VERSION "created by canmatrix"

NS_ :

BS_:

BU_:

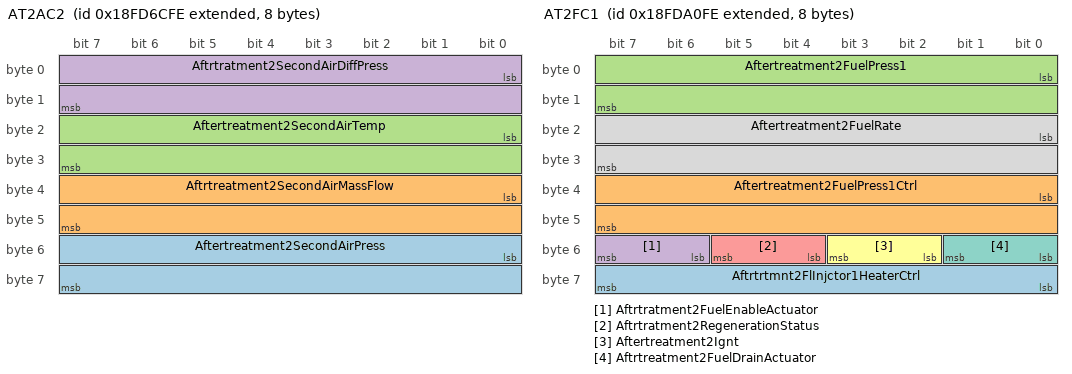
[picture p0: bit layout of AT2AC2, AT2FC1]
BO_ 2566745342 AT2AC2: 8 Vector__XXX
 SG_ Aftertreatment2SecondAirPress : 48|16@1+ (0.1,0) [0|6425.5] "kPa" Vector__XXX
 SG_ Aftrtreatment2SecondAirMassFlow : 32|16@1+ (0.2,0) [0|12851] "kg/h" Vector__XXX
 SG_ Aftertreatment2SecondAirTemp : 16|16@1+ (0.03125,-273) [-273|1734.96875] "deg C" Vector__XXX
 SG_ Aftrtratment2SecondAirDiffPress : 0|16@1+ (0.0078125,-250) [-250|251.99] "kPa" Vector__XXX

BO_ 2566758654 AT2FC1: 8 Vector__XXX
 SG_ Aftrtrtmnt2FlInjctor1HeaterCtrl : 56|8@1+ (0.4,0) [0|100] "%" Vector__XXX
 SG_ Aftertreatment2FuelPress1Ctrl : 32|16@1+ (0.0025,0) [0|160.6375] "%" Vector__XXX
 SG_ Aftertreatment2FuelPress1 : 0|16@1+ (0.1,0) [0|6425.5] "kPa" Vector__XXX
 SG_ Aftrtratment2FuelEnableActuator : 54|2@1+ (1,0) [0|3] "" Vector__XXX
 SG_ Aftrtratment2RegenerationStatus : 52|2@1+ (1,0) [0|3] "" Vector__XXX
 SG_ Aftertreatment2Ignt : 50|2@1+ (1,0) [0|3] "" Vector__XXX
 SG_ Aftrtreatment2FuelDrainActuator : 48|2@1+ (1,0) [0|3] "" Vector__XXX
 SG_ Aftertreatment2FuelRate : 16|16@1+ (0.05,0) [0|3212.75] "L/h" Vector__XXX

BO_ 2566753278 AT2GP: 8 Vector__XXX
 SG_ DslPrticulateFilterOutletPress2 : 16|16@1+ (0.1,0) [0|6425.5] "kPa" Vector__XXX
 SG_ DslPrticulateFilterIntakePress2 : 0|16@1+ (0.1,0) [0|6425.5] "kPa" Vector__XXX

BO_ 2566756862 AT2HI: 36 Vector__XXX
 SG_ Aftrtrtmnt2TtlNmbrOfActvRgnrtnMn : 224|32@1+ (1,0) [0|4294967295] "counts" Vector__XXX
 SG_ Aftrtrtmnt2TtlNmbrOfActvRgnrtnIn : 192|32@1+ (1,0) [0|4294967295] "counts" Vector__XXX
 SG_ Aftrtrtmnt2AvrgTmBtwnActvRgnrtns : 256|32@1+ (1,0) [0|4211081215] "s" Vector__XXX
 SG_ Aftrtrtmnt2TtlNmbrOfPssvRgnrtns : 160|32@1+ (1,0) [0|4294967295] "counts" Vector__XXX
 SG_ Aftrtrtmnt2TtlPssvRgnrationTime : 128|32@1+ (1,0) [0|4211081215] "s" Vector__XXX
 SG_ Aftrtrtmnt2TtlNmbrOfActvRgnrtns : 96|32@1+ (1,0) [0|4294967295] "counts" Vector__XXX
 SG_ Aftrtreatment2TotalDisabledTime : 64|32@1+ (1,0) [0|4211081215] "s" Vector__XXX
 SG_ Aftrtrtmnt2TtalRegenerationTime : 32|32@1+ (1,0) [0|4211081215] "s" Vector__XXX
 SG_ Aftertreatment2TotalFuelUsed : 0|32@1+ (0.5,0) [0|2105540607.5] "L" Vector__XXX

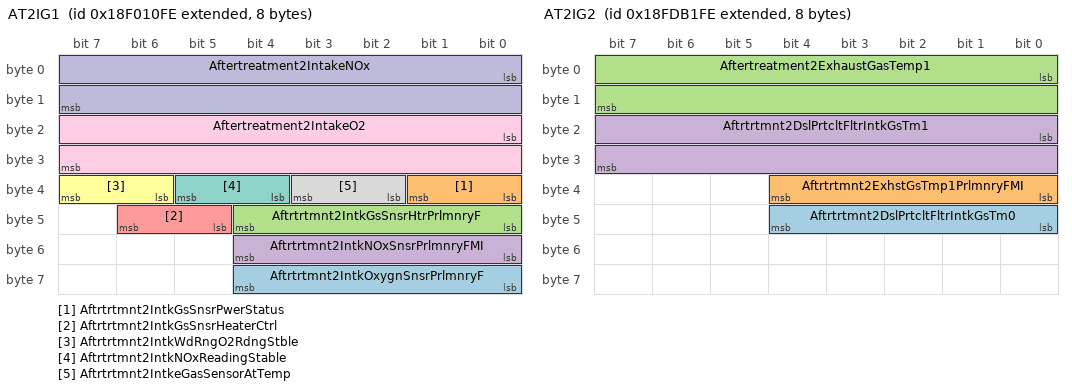
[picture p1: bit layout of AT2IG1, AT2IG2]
BO_ 2565869822 AT2IG1: 8 Vector__XXX
 SG_ Aftrtrtmnt2IntkOxygnSnsrPrlmnryF : 56|5@1+ (1,0) [0|31] "" Vector__XXX
 SG_ Aftrtrtmnt2IntkGsSnsrPwerStatus : 32|2@1+ (1,0) [0|3] "" Vector__XXX
 SG_ Aftrtrtmnt2IntkGsSnsrHtrPrlmnryF : 40|5@1+ (1,0) [0|31] "" Vector__XXX
 SG_ Aftrtrtmnt2IntkNOxSnsrPrlmnryFMI : 48|5@1+ (1,0) [0|31] "" Vector__XXX
 SG_ Aftrtrtmnt2IntkGsSnsrHeaterCtrl : 45|2@1+ (1,0) [0|3] "" Vector__XXX
 SG_ Aftrtrtmnt2IntkWdRngO2RdngStble : 38|2@1+ (1,0) [0|3] "" Vector__XXX
 SG_ Aftrtrtmnt2IntkNOxReadingStable : 36|2@1+ (1,0) [0|3] "" Vector__XXX
 SG_ Aftrtrtmnt2IntkeGasSensorAtTemp : 34|2@1+ (1,0) [0|3] "" Vector__XXX
 SG_ Aftertreatment2IntakeO2 : 16|16@1+ (0.000514,-12) [-12|21] "%" Vector__XXX
 SG_ Aftertreatment2IntakeNOx : 0|16@1+ (0.05,-200) [-200|3012.75] "ppm" Vector__XXX

BO_ 2566763006 AT2IG2: 8 Vector__XXX
 SG_ Aftrtrtmnt2DslPrtcltFltrIntkGsTm0 : 40|5@1+ (1,0) [0|31] "" Vector__XXX
 SG_ Aftrtrtmnt2ExhstGsTmp1PrlmnryFMI : 32|5@1+ (1,0) [0|31] "" Vector__XXX
 SG_ Aftertreatment2ExhaustGasTemp1 : 0|16@1+ (0.03125,-273) [-273|1734.96875] "deg C" Vector__XXX
 SG_ Aftrtrtmnt2DslPrtcltFltrIntkGsTm1 : 16|16@1+ (0.03125,-273) [-273|1734.96875] "deg C" Vector__XXX

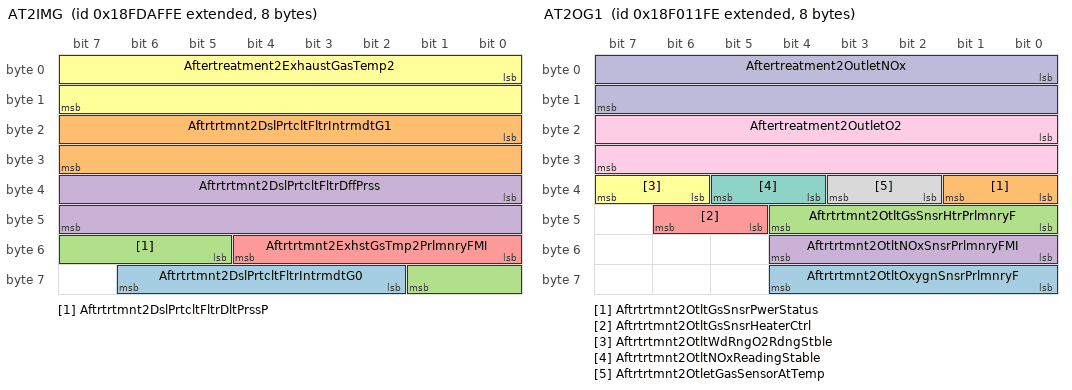
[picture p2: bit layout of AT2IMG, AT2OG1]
BO_ 2566762494 AT2IMG: 8 Vector__XXX
 SG_ Aftrtrtmnt2DslPrtcltFltrIntrmdtG0 : 58|5@1+ (1,0) [0|31] "" Vector__XXX
 SG_ Aftrtrtmnt2DslPrtcltFltrIntrmdtG1 : 16|16@1+ (0.03125,-273) [-273|1734.96875] "deg C" Vector__XXX
 SG_ Aftrtrtmnt2DslPrtcltFltrDltPrssP : 53|5@1+ (1,0) [0|31] "" Vector__XXX
 SG_ Aftrtrtmnt2DslPrtcltFltrDffPrss : 32|16@1+ (0.1,0) [0|6425.5] "kPa" Vector__XXX
 SG_ Aftrtrtmnt2ExhstGsTmp2PrlmnryFMI : 48|5@1+ (1,0) [0|31] "" Vector__XXX
 SG_ Aftertreatment2ExhaustGasTemp2 : 0|16@1+ (0.03125,-273) [-273|1734.96875] "deg C" Vector__XXX

BO_ 2565870078 AT2OG1: 8 Vector__XXX
 SG_ Aftrtrtmnt2OtltOxygnSnsrPrlmnryF : 56|5@1+ (1,0) [0|31] "" Vector__XXX
 SG_ Aftrtrtmnt2OtltGsSnsrPwerStatus : 32|2@1+ (1,0) [0|3] "" Vector__XXX
 SG_ Aftrtrtmnt2OtltGsSnsrHtrPrlmnryF : 40|5@1+ (1,0) [0|31] "" Vector__XXX
 SG_ Aftrtrtmnt2OtltNOxSnsrPrlmnryFMI : 48|5@1+ (1,0) [0|31] "" Vector__XXX
 SG_ Aftrtrtmnt2OtltGsSnsrHeaterCtrl : 45|2@1+ (1,0) [0|3] "" Vector__XXX
 SG_ Aftrtrtmnt2OtltWdRngO2RdngStble : 38|2@1+ (1,0) [0|3] "" Vector__XXX
 SG_ Aftrtrtmnt2OtltNOxReadingStable : 36|2@1+ (1,0) [0|3] "" Vector__XXX
 SG_ Aftrtrtmnt2OtletGasSensorAtTemp : 34|2@1+ (1,0) [0|3] "" Vector__XXX
 SG_ Aftertreatment2OutletO2 : 16|16@1+ (0.000514,-12) [-12|21] "%" Vector__XXX
 SG_ Aftertreatment2OutletNOx : 0|16@1+ (0.05,-200) [-200|3012.75] "ppm" Vector__XXX

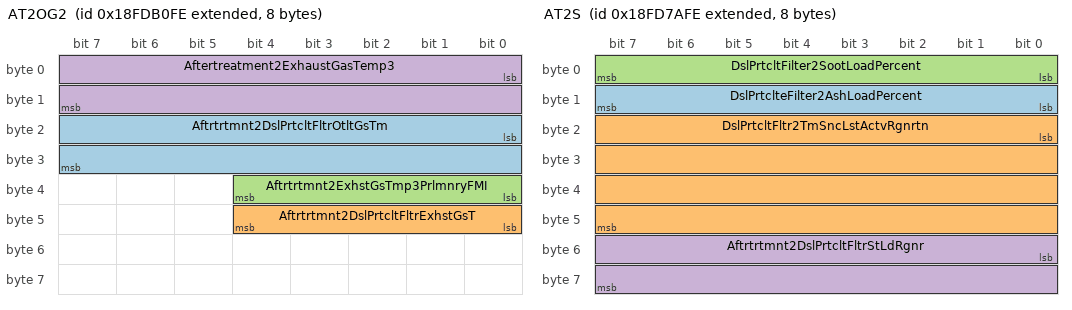
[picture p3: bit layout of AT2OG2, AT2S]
BO_ 2566762750 AT2OG2: 8 Vector__XXX
 SG_ Aftrtrtmnt2DslPrtcltFltrOtltGsTm : 16|16@1+ (0.03125,-273) [-273|1734.96875] "deg C" Vector__XXX
 SG_ Aftrtrtmnt2DslPrtcltFltrExhstGsT : 40|5@1+ (1,0) [0|31] "" Vector__XXX
 SG_ Aftrtrtmnt2ExhstGsTmp3PrlmnryFMI : 32|5@1+ (1,0) [0|31] "" Vector__XXX
 SG_ Aftertreatment2ExhaustGasTemp3 : 0|16@1+ (0.03125,-273) [-273|1734.96875] "deg C" Vector__XXX

BO_ 2566748926 AT2S: 8 Vector__XXX
 SG_ DslPrtclteFilter2AshLoadPercent : 8|8@1+ (1,0) [0|250] "%" Vector__XXX
 SG_ DslPrtcltFltr2TmSncLstActvRgnrtn : 16|32@1+ (1,0) [0|4211081215] "s" Vector__XXX
 SG_ DslPrtcltFilter2SootLoadPercent : 0|8@1+ (1,0) [0|250] "%" Vector__XXX
 SG_ Aftrtrtmnt2DslPrtcltFltrStLdRgnr : 48|16@1+ (0.0025,0) [0|160.6375] "%" Vector__XXX

BO_ 2566748414 AT2TI: 32 Vector__XXX
 SG_ Aftrtrtmnt2TrpNmbrOfActvRgnrtnMn : 224|32@1+ (1,0) [0|4294967295] "counts" Vector__XXX
 SG_ Aftrtrtmnt2TrpNmbrOfActvRgnrtnIn : 192|32@1+ (1,0) [0|4294967295] "counts" Vector__XXX
 SG_ Aftrtrtmnt2TrpNmbrOfPssvRgnrtns : 160|32@1+ (1,0) [0|4294967295] "counts" Vector__XXX
 SG_ Aftrtrtmnt2TrpPssvRgnrationTime : 128|32@1+ (1,0) [0|4211081215] "s" Vector__XXX
 SG_ Aftrtrtmnt2TrpNmbrOfActvRgnrtns : 96|32@1+ (1,0) [0|4294967295] "counts" Vector__XXX
 SG_ Aftertreatment2TripDisabledTime : 64|32@1+ (1,0) [0|4211081215] "s" Vector__XXX
 SG_ Aftrtrtmnt2TrpActvRgnrationTime : 32|32@1+ (1,0) [0|4211081215] "s" Vector__XXX
 SG_ Aftertreatment2TripFuelUsed : 0|32@1+ (0.5,0) [0|2105540607.5] "L" Vector__XXX

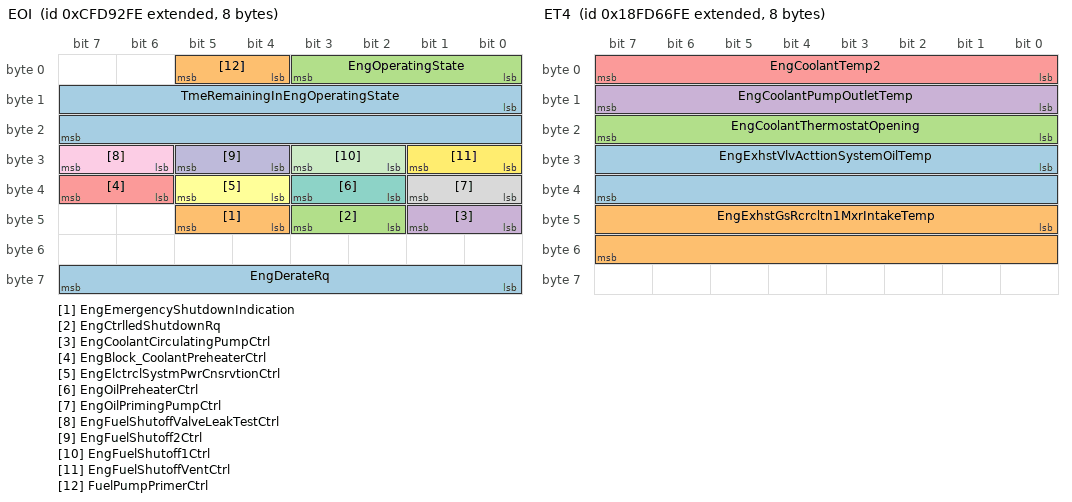
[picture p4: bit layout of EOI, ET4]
BO_ 2365428478 EOI: 8 Vector__XXX
 SG_ EngDerateRq : 56|8@1+ (0.4,0) [0|100] "%" Vector__XXX
 SG_ EngEmergencyShutdownIndication : 44|2@1+ (1,0) [0|3] "" Vector__XXX
 SG_ EngCtrlledShutdownRq : 42|2@1+ (1,0) [0|3] "" Vector__XXX
 SG_ EngCoolantCirculatingPumpCtrl : 40|2@1+ (1,0) [0|3] "" Vector__XXX
 SG_ EngBlock_CoolantPreheaterCtrl : 38|2@1+ (1,0) [0|3] "" Vector__XXX
 SG_ EngElctrclSystmPwrCnsrvtionCtrl : 36|2@1+ (1,0) [0|3] "" Vector__XXX
 SG_ EngOilPreheaterCtrl : 34|2@1+ (1,0) [0|3] "" Vector__XXX
 SG_ EngOilPrimingPumpCtrl : 32|2@1+ (1,0) [0|3] "" Vector__XXX
 SG_ EngFuelShutoffValveLeakTestCtrl : 30|2@1+ (1,0) [0|3] "" Vector__XXX
 SG_ EngFuelShutoff2Ctrl : 28|2@1+ (1,0) [0|3] "" Vector__XXX
 SG_ EngFuelShutoff1Ctrl : 26|2@1+ (1,0) [0|3] "" Vector__XXX
 SG_ EngFuelShutoffVentCtrl : 24|2@1+ (1,0) [0|3] "" Vector__XXX
 SG_ TmeRemainingInEngOperatingState : 8|16@1+ (1,0) [0|64255] "s" Vector__XXX
 SG_ FuelPumpPrimerCtrl : 4|2@1+ (1,0) [0|3] "" Vector__XXX
 SG_ EngOperatingState : 0|4@1+ (1,0) [0|15] "" Vector__XXX

BO_ 2566743806 ET4: 8 Vector__XXX
 SG_ EngExhstVlvActtionSystemOilTemp : 24|16@1+ (0.03125,-273) [-273|1734.96875] "deg C" Vector__XXX
 SG_ EngExhstGsRcrcltn1MxrIntakeTemp : 40|16@1+ (0.03125,-273) [-273|1734.96875] "deg C" Vector__XXX
 SG_ EngCoolantThermostatOpening : 16|8@1+ (0.4,0) [0|100] "%" Vector__XXX
 SG_ EngCoolantPumpOutletTemp : 8|8@1+ (1,-40) [-40|210] "deg C" Vector__XXX
 SG_ EngCoolantTemp2 : 0|8@1+ (1,-40) [-40|210] "deg C" Vector__XXX

BO_ 2499635454 GCVW: 8 Vector__XXX
 SG_ NetVehicleWeightChange : 24|24@1+ (2,-16449535) [-16449535|16449535] "kg" Vector__XXX
 SG_ GrossCombinationWeight : 0|24@1+ (2,0) [0|32899070] "kg" Vector__XXX

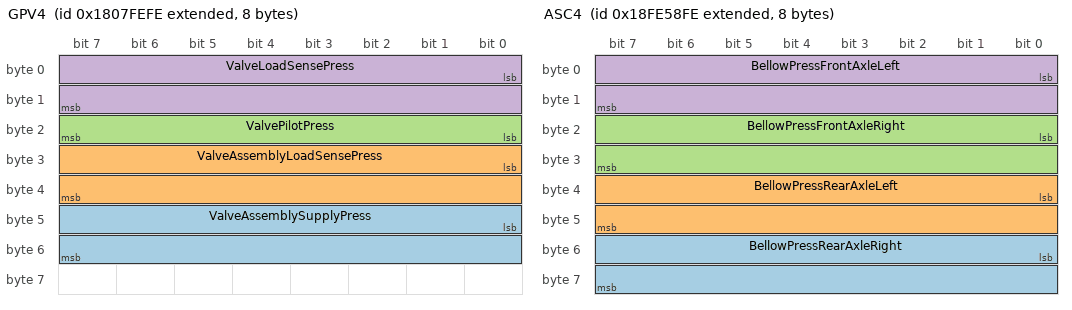
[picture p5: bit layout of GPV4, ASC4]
BO_ 2550660862 GPV4: 8 Vector__XXX
 SG_ ValveAssemblySupplyPress : 40|16@1+ (5,0) [0|321275] "kPa" Vector__XXX
 SG_ ValveAssemblyLoadSensePress : 24|16@1+ (5,0) [0|321275] "kPa" Vector__XXX
 SG_ ValvePilotPress : 16|8@1+ (16,0) [0|4000] "kPa" Vector__XXX
 SG_ ValveLoadSensePress : 0|16@1+ (5,0) [0|321275] "kPa" Vector__XXX

BO_ 2566805758 ASC4: 8 Vector__XXX
 SG_ BellowPressRearAxleRight : 48|16@1+ (0.1,0) [0|6425.5] "kPa" Vector__XXX
 SG_ BellowPressRearAxleLeft : 32|16@1+ (0.1,0) [0|6425.5] "kPa" Vector__XXX
 SG_ BellowPressFrontAxleRight : 16|16@1+ (0.1,0) [0|6425.5] "kPa" Vector__XXX
 SG_ BellowPressFrontAxleLeft : 0|16@1+ (0.1,0) [0|6425.5] "kPa" Vector__XXX

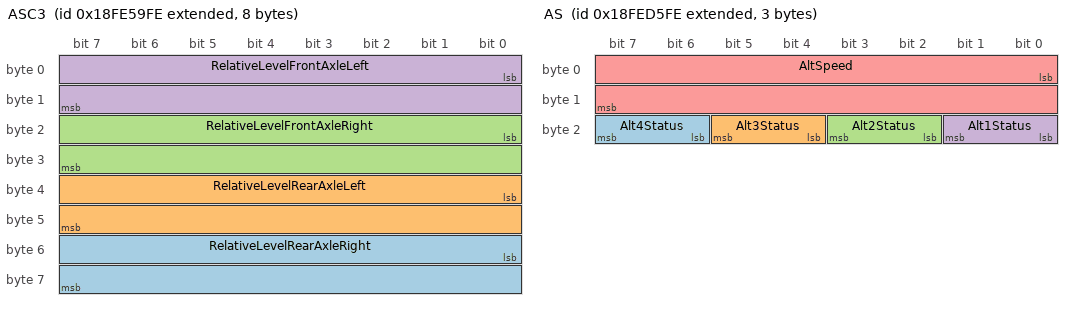
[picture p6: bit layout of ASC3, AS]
BO_ 2566806014 ASC3: 8 Vector__XXX
 SG_ RelativeLevelRearAxleRight : 48|16@1+ (0.1,-3200) [-3200|3225.5] "mm" Vector__XXX
 SG_ RelativeLevelRearAxleLeft : 32|16@1+ (0.1,-3200) [-3200|3225.5] "mm" Vector__XXX
 SG_ RelativeLevelFrontAxleRight : 16|16@1+ (0.1,-3200) [-3200|3225.5] "mm" Vector__XXX
 SG_ RelativeLevelFrontAxleLeft : 0|16@1+ (0.1,-3200) [-3200|3225.5] "mm" Vector__XXX

BO_ 2362638078 ASC2: 8 Vector__XXX
 SG_ SpeedDependentLevelCtrlRq : 56|2@1+ (1,0) [0|3] "" Vector__XXX
 SG_ PrhbtAutomaticAirSuspensionCtrl : 58|2@1+ (1,0) [0|3] "" Vector__XXX
 SG_ MemoryLevelRq : 60|4@1+ (1,0) [0|15] "" Vector__XXX
 SG_ AllowLevelCtrlDuringBrakingCmd : 54|2@1+ (1,0) [0|3] "" Vector__XXX
 SG_ ProhibitAirSuspensionCtrl : 52|2@1+ (1,0) [0|3] "" Vector__XXX
 SG_ KneelingCmdRearAxle : 50|2@1+ (1,0) [0|3] "" Vector__XXX
 SG_ KneelingCmdFrontAxle : 48|2@1+ (1,0) [0|3] "" Vector__XXX
 SG_ DamperStiffnessRqLift_TagAxle : 40|8@1+ (0.4,0) [0|100] "%" Vector__XXX
 SG_ DamperStiffnessRqRearAxle : 32|8@1+ (0.4,0) [0|100] "%" Vector__XXX
 SG_ DamperStiffnessRqFrontAxle : 24|8@1+ (0.4,0) [0|100] "%" Vector__XXX
 SG_ LevelCtrlModeRq : 16|4@1+ (1,0) [0|15] "" Vector__XXX
 SG_ NominalLevelRqRearAxle : 12|4@1+ (1,0) [0|15] "" Vector__XXX
 SG_ NominalLevelRqFrontAxle : 8|4@1+ (1,0) [0|15] "" Vector__XXX
 SG_ KneelingCtrlModeRq : 6|2@1+ (1,0) [0|3] "" Vector__XXX
 SG_ KneelingRqRightSide : 4|2@1+ (1,0) [0|3] "" Vector__XXX
 SG_ KneelingRqLeftSide : 2|2@1+ (1,0) [0|3] "" Vector__XXX
 SG_ AutomaticTractionHelp : 0|2@1+ (1,0) [0|3] "" Vector__XXX
 SG_ LiftAxle2PosCmd : 22|2@1+ (1,0) [0|3] "" Vector__XXX
 SG_ LiftAxle1PosCmd : 20|2@1+ (1,0) [0|3] "" Vector__XXX

BO_ 2365479678 ASC1: 8 Vector__XXX
 SG_ SpeedDependantLevelCtrlStatus : 54|2@1+ (1,0) [0|3] "" Vector__XXX
 SG_ MemoryLevel : 60|4@1+ (1,0) [0|15] "" Vector__XXX
 SG_ AllwLvelCtrlDuringBrakingStatus : 52|2@1+ (1,0) [0|3] "" Vector__XXX
 SG_ SspensionCtrlRefusalInformation : 56|4@1+ (1,0) [0|15] "" Vector__XXX
 SG_ SuspensionRemoteCtrl2 : 50|2@1+ (1,0) [0|3] "" Vector__XXX
 SG_ SuspensionRemoteCtrl1 : 48|2@1+ (1,0) [0|3] "" Vector__XXX
 SG_ RearAxleInBumperRange : 42|2@1+ (1,0) [0|3] "" Vector__XXX
 SG_ FrontAxleInBumperRange : 40|2@1+ (1,0) [0|3] "" Vector__XXX
 SG_ DoorRelease : 36|2@1+ (1,0) [0|3] "" Vector__XXX
 SG_ VehicleMotionInhibit : 34|2@1+ (1,0) [0|3] "" Vector__XXX
 SG_ SecurityDevice : 32|2@1+ (1,0) [0|3] "" Vector__XXX
 SG_ LevelCtrlMode : 28|4@1+ (1,0) [0|15] "" Vector__XXX
 SG_ KneelingInformation : 24|4@1+ (1,0) [0|15] "" Vector__XXX
 SG_ LiftingCtrlModeRearAxle : 22|2@1+ (1,0) [0|3] "" Vector__XXX
 SG_ LiftingCtrlModeFrontAxle : 20|2@1+ (1,0) [0|3] "" Vector__XXX
 SG_ LoweringCtrlModeRearAxle : 18|2@1+ (1,0) [0|3] "" Vector__XXX
 SG_ LoweringCtrlModeFrontAxle : 16|2@1+ (1,0) [0|3] "" Vector__XXX
 SG_ AboveNominalLevelRearAxle : 14|2@1+ (1,0) [0|3] "" Vector__XXX
 SG_ AboveNominalLevelFrontAxle : 12|2@1+ (1,0) [0|3] "" Vector__XXX
 SG_ BelowNominalLevelRearAxle : 10|2@1+ (1,0) [0|3] "" Vector__XXX
 SG_ BelowNominalLevelFrontAxle : 8|2@1+ (1,0) [0|3] "" Vector__XXX
 SG_ NominalLevelRearAxle : 4|4@1+ (1,0) [0|15] "" Vector__XXX
 SG_ NominalLevelFrontAxle : 0|4@1+ (1,0) [0|15] "" Vector__XXX
 SG_ LiftAxle2Pos : 46|2@1+ (1,0) [0|3] "" Vector__XXX
 SG_ LiftAxle1Pos : 38|2@1+ (1,0) [0|3] "" Vector__XXX

BO_ 2566837758 AS: 3 Vector__XXX
 SG_ Alt4Status : 22|2@1+ (1,0) [0|3] "" Vector__XXX
 SG_ Alt3Status : 20|2@1+ (1,0) [0|3] "" Vector__XXX
 SG_ Alt2Status : 18|2@1+ (1,0) [0|3] "" Vector__XXX
 SG_ Alt1Status : 16|2@1+ (1,0) [0|3] "" Vector__XXX
 SG_ AltSpeed : 0|16@1+ (0.5,0) [0|32127.5] "rpm" Vector__XXX

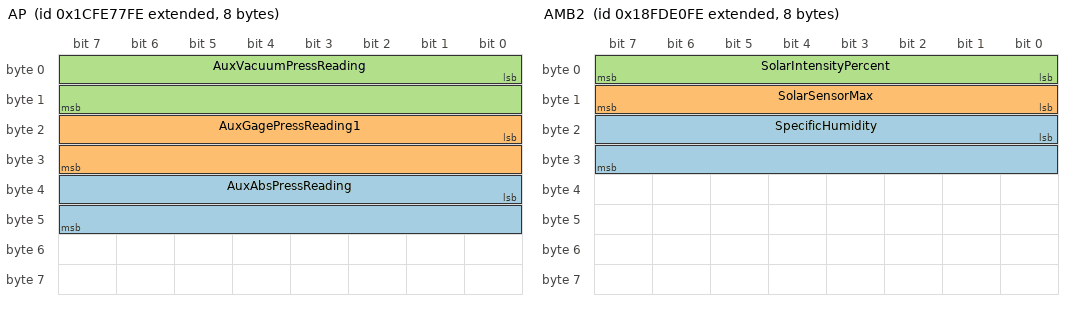
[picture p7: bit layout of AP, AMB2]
BO_ 2633922558 AP: 8 Vector__XXX
 SG_ AuxAbsPressReading : 32|16@1+ (0.5,0) [0|32127.5] "kPa" Vector__XXX
 SG_ AuxGagePressReading1 : 16|16@1+ (0.5,0) [0|32127.5] "kPa" Vector__XXX
 SG_ AuxVacuumPressReading : 0|16@1+ (0.5,0) [0|32127.5] "kPa" Vector__XXX

BO_ 2566775038 AMB2: 8 Vector__XXX
 SG_ SpecificHumidity : 16|16@1+ (0.01,0) [0|642.55] "g/kg" Vector__XXX
 SG_ SolarSensorMax : 8|8@1+ (0.4,0) [0|100] "mW/cm/cm" Vector__XXX
 SG_ SolarIntensityPercent : 0|8@1+ (0.4,0) [0|100] "%" Vector__XXX

BO_ 2499635966 AGW: 8 Vector__XXX
 SG_ AxleGroupWeight : 8|16@1+ (2,0) [0|128510] "kg" Vector__XXX
 SG_ AxleGroupLocation : 0|4@1+ (1,0) [0|15] "" Vector__XXX

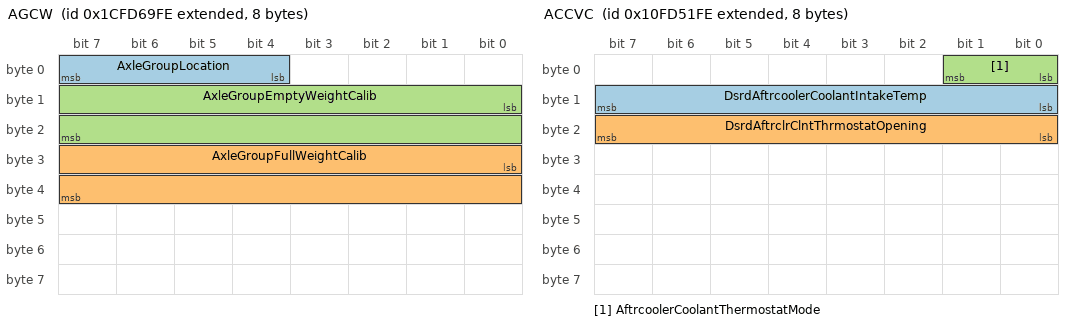
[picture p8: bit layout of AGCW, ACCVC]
BO_ 2633853438 AGCW: 8 Vector__XXX
 SG_ AxleGroupLocation : 4|4@1+ (1,0) [0|15] "" Vector__XXX
 SG_ AxleGroupFullWeightCalib : 24|16@1+ (2,0) [0|128510] "kg" Vector__XXX
 SG_ AxleGroupEmptyWeightCalib : 8|16@1+ (2,0) [0|128510] "kg" Vector__XXX

BO_ 2432520702 ACCVC: 8 Vector__XXX
 SG_ DsrdAftrcoolerCoolantIntakeTemp : 8|8@1+ (1,-40) [-40|210] "deg C" Vector__XXX
 SG_ DsrdAftrclrClntThrmostatOpening : 16|8@1+ (0.4,0) [0|100] "%" Vector__XXX
 SG_ AftrcoolerCoolantThermostatMode : 0|2@1+ (1,0) [0|3] "" Vector__XXX

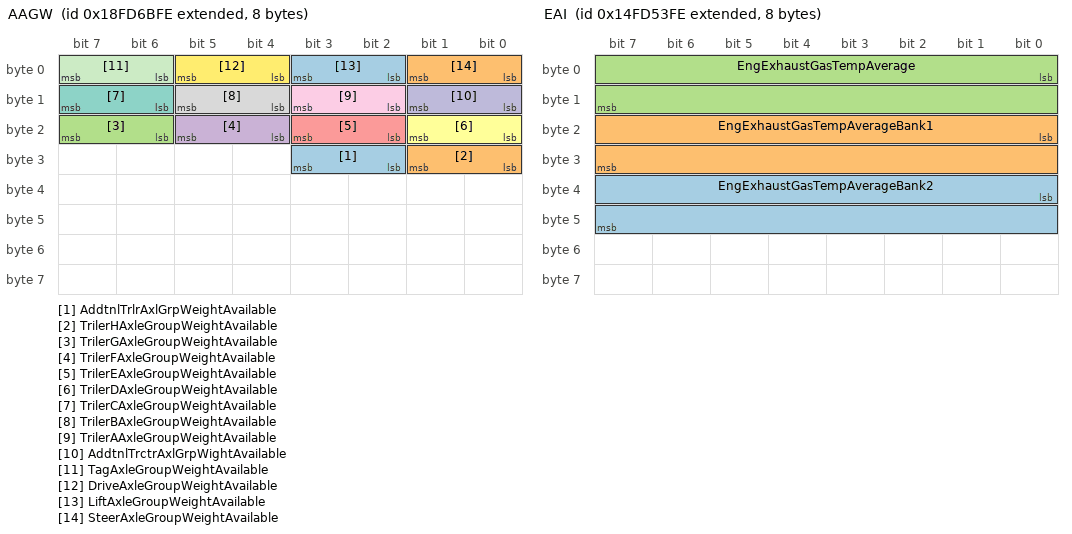
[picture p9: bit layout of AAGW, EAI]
BO_ 2566745086 AAGW: 8 Vector__XXX
 SG_ AddtnlTrlrAxlGrpWeightAvailable : 26|2@1+ (1,0) [0|3] "" Vector__XXX
 SG_ TrilerHAxleGroupWeightAvailable : 24|2@1+ (1,0) [0|3] "" Vector__XXX
 SG_ TrilerGAxleGroupWeightAvailable : 22|2@1+ (1,0) [0|3] "" Vector__XXX
 SG_ TrilerFAxleGroupWeightAvailable : 20|2@1+ (1,0) [0|3] "" Vector__XXX
 SG_ TrilerEAxleGroupWeightAvailable : 18|2@1+ (1,0) [0|3] "" Vector__XXX
 SG_ TrilerDAxleGroupWeightAvailable : 16|2@1+ (1,0) [0|3] "" Vector__XXX
 SG_ TrilerCAxleGroupWeightAvailable : 14|2@1+ (1,0) [0|3] "" Vector__XXX
 SG_ TrilerBAxleGroupWeightAvailable : 12|2@1+ (1,0) [0|3] "" Vector__XXX
 SG_ TrilerAAxleGroupWeightAvailable : 10|2@1+ (1,0) [0|3] "" Vector__XXX
 SG_ AddtnlTrctrAxlGrpWightAvailable : 8|2@1+ (1,0) [0|3] "" Vector__XXX
 SG_ TagAxleGroupWeightAvailable : 6|2@1+ (1,0) [0|3] "" Vector__XXX
 SG_ DriveAxleGroupWeightAvailable : 4|2@1+ (1,0) [0|3] "" Vector__XXX
 SG_ LiftAxleGroupWeightAvailable : 2|2@1+ (1,0) [0|3] "" Vector__XXX
 SG_ SteerAxleGroupWeightAvailable : 0|2@1+ (1,0) [0|3] "" Vector__XXX

BO_ 2566744062 ZNVW: 8 Vector__XXX
 SG_ ZeroNetVehicleWeightChange : 0|2@1+ (1,0) [0|3] "" Vector__XXX

BO_ 2499630078 EAI: 8 Vector__XXX
 SG_ EngExhaustGasTempAverageBank2 : 32|16@1+ (0.03125,-273) [-273|1734.96875] "deg C" Vector__XXX
 SG_ EngExhaustGasTempAverageBank1 : 16|16@1+ (0.03125,-273) [-273|1734.96875] "deg C" Vector__XXX
 SG_ EngExhaustGasTempAverage : 0|16@1+ (0.03125,-273) [-273|1734.96875] "deg C" Vector__XXX

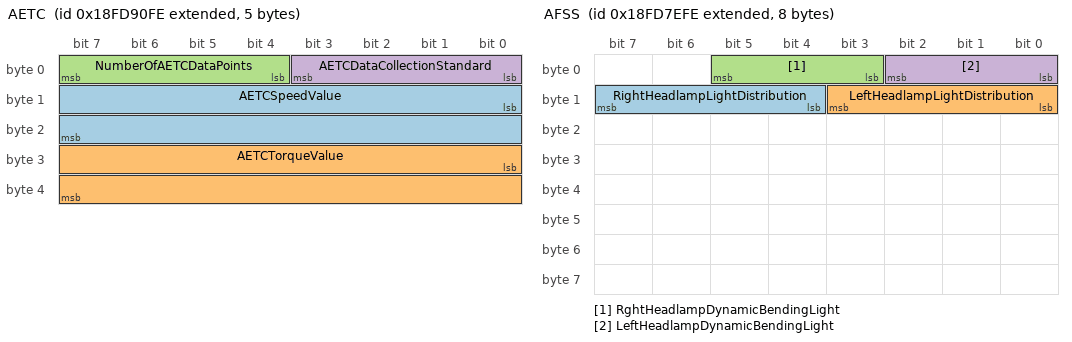
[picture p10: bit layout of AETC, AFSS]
BO_ 2566754558 AETC: 5 Vector__XXX
 SG_ AETCSpeedValue : 8|16@1- (1,0) [0|8031.875] "rpm" Vector__XXX
 SG_ AETCTorqueValue : 24|16@1+ (1,0) [0|64255] "Nm" Vector__XXX
 SG_ NumberOfAETCDataPoints : 4|4@1+ (1,0) [0|15] "" Vector__XXX
 SG_ AETCDataCollectionStandard : 0|4@1+ (1,0) [0|15] "" Vector__XXX

BO_ 2566749950 AFSS: 8 Vector__XXX
 SG_ RightHeadlampLightDistribution : 12|4@1+ (1,0) [0|15] "" Vector__XXX
 SG_ LeftHeadlampLightDistribution : 8|4@1+ (1,0) [0|15] "" Vector__XXX
 SG_ RghtHeadlampDynamicBendingLight : 3|3@1+ (1,0) [0|7] "" Vector__XXX
 SG_ LeftHeadlampDynamicBendingLight : 0|3@1+ (1,0) [0|7] "" Vector__XXX

BO_ 2566838782 AUXIO1: 8 Vector__XXX
 SG_ AuxI_O16 : 24|2@1+ (1,0) [0|3] "" Vector__XXX
 SG_ AuxI_O15 : 26|2@1+ (1,0) [0|3] "" Vector__XXX
 SG_ AuxI_O14 : 28|2@1+ (1,0) [0|3] "" Vector__XXX
 SG_ AuxI_O13 : 30|2@1+ (1,0) [0|3] "" Vector__XXX
 SG_ AuxI_O12 : 16|2@1+ (1,0) [0|3] "" Vector__XXX
 SG_ AuxI_O11 : 18|2@1+ (1,0) [0|3] "" Vector__XXX
 SG_ AuxI_O10 : 20|2@1+ (1,0) [0|3] "" Vector__XXX
 SG_ AuxI_O09 : 22|2@1+ (1,0) [0|3] "" Vector__XXX
 SG_ AuxI_O08 : 8|2@1+ (1,0) [0|3] "" Vector__XXX
 SG_ AuxI_O07 : 10|2@1+ (1,0) [0|3] "" Vector__XXX
 SG_ AuxI_O06 : 12|2@1+ (1,0) [0|3] "" Vector__XXX
 SG_ AuxI_O05 : 14|2@1+ (1,0) [0|3] "" Vector__XXX
 SG_ AuxI_O04 : 0|2@1+ (1,0) [0|3] "" Vector__XXX
 SG_ AuxI_O03 : 2|2@1+ (1,0) [0|3] "" Vector__XXX
 SG_ AuxI_O02 : 4|2@1+ (1,0) [0|3] "" Vector__XXX
 SG_ AuxI_O01 : 6|2@1+ (1,0) [0|3] "" Vector__XXX
 SG_ AuxI_OChannel2 : 48|16@1+ (1,0) [0|64255] "counts" Vector__XXX
 SG_ AuxI_OChannel1 : 32|16@1+ (1,0) [0|64255] "counts" Vector__XXX

BO_ 2561146622 AUXIO2: 8 Vector__XXX
 SG_ AuxI_O45 : 62|2@1+ (1,0) [0|3] "" Vector__XXX
 SG_ AuxI_O46 : 60|2@1+ (1,0) [0|3] "" Vector__XXX
 SG_ AuxI_O47 : 58|2@1+ (1,0) [0|3] "" Vector__XXX
 SG_ AuxI_O48 : 56|2@1+ (1,0) [0|3] "" Vector__XXX
 SG_ AuxI_O41 : 54|2@1+ (1,0) [0|3] "" Vector__XXX
 SG_ AuxI_O42 : 52|2@1+ (1,0) [0|3] "" Vector__XXX
 SG_ AuxI_O43 : 50|2@1+ (1,0) [0|3] "" Vector__XXX
 SG_ AuxI_O44 : 48|2@1+ (1,0) [0|3] "" Vector__XXX
 SG_ AuxI_O37 : 46|2@1+ (1,0) [0|3] "" Vector__XXX
 SG_ AuxI_O38 : 44|2@1+ (1,0) [0|3] "" Vector__XXX
 SG_ AuxI_O39 : 42|2@1+ (1,0) [0|3] "" Vector__XXX
 SG_ AuxI_O40 : 40|2@1+ (1,0) [0|3] "" Vector__XXX
 SG_ AuxI_O33 : 38|2@1+ (1,0) [0|3] "" Vector__XXX
 SG_ AuxI_O34 : 36|2@1+ (1,0) [0|3] "" Vector__XXX
 SG_ AuxI_O35 : 34|2@1+ (1,0) [0|3] "" Vector__XXX
 SG_ AuxI_O36 : 32|2@1+ (1,0) [0|3] "" Vector__XXX
 SG_ AuxI_O29 : 30|2@1+ (1,0) [0|3] "" Vector__XXX
 SG_ AuxI_O30 : 28|2@1+ (1,0) [0|3] "" Vector__XXX
 SG_ AuxI_O31 : 26|2@1+ (1,0) [0|3] "" Vector__XXX
 SG_ AuxI_O32 : 24|2@1+ (1,0) [0|3] "" Vector__XXX
 SG_ AuxI_O25 : 22|2@1+ (1,0) [0|3] "" Vector__XXX
 SG_ AuxI_O26 : 20|2@1+ (1,0) [0|3] "" Vector__XXX
 SG_ AuxI_O27 : 18|2@1+ (1,0) [0|3] "" Vector__XXX
 SG_ AuxI_O28 : 16|2@1+ (1,0) [0|3] "" Vector__XXX
 SG_ AuxI_O21 : 14|2@1+ (1,0) [0|3] "" Vector__XXX
 SG_ AuxI_O22 : 12|2@1+ (1,0) [0|3] "" Vector__XXX
 SG_ AuxI_O23 : 10|2@1+ (1,0) [0|3] "" Vector__XXX
 SG_ AuxI_O24 : 8|2@1+ (1,0) [0|3] "" Vector__XXX
 SG_ AuxI_O17 : 6|2@1+ (1,0) [0|3] "" Vector__XXX
 SG_ AuxI_O18 : 4|2@1+ (1,0) [0|3] "" Vector__XXX
 SG_ AuxI_O19 : 2|2@1+ (1,0) [0|3] "" Vector__XXX
 SG_ AuxI_O20 : 0|2@1+ (1,0) [0|3] "" Vector__XXX

BO_ 2561081086 AUXIO3: 8 Vector__XXX
 SG_ AuxI_O77 : 62|2@1+ (1,0) [0|3] "" Vector__XXX
 SG_ AuxI_O78 : 60|2@1+ (1,0) [0|3] "" Vector__XXX
 SG_ AuxI_O79 : 58|2@1+ (1,0) [0|3] "" Vector__XXX
 SG_ AuxI_O80 : 56|2@1+ (1,0) [0|3] "" Vector__XXX
 SG_ AuxI_O73 : 54|2@1+ (1,0) [0|3] "" Vector__XXX
 SG_ AuxI_O74 : 52|2@1+ (1,0) [0|3] "" Vector__XXX
 SG_ AuxI_O75 : 50|2@1+ (1,0) [0|3] "" Vector__XXX
 SG_ AuxI_O76 : 48|2@1+ (1,0) [0|3] "" Vector__XXX
 SG_ AuxI_O69 : 46|2@1+ (1,0) [0|3] "" Vector__XXX
 SG_ AuxI_O70 : 44|2@1+ (1,0) [0|3] "" Vector__XXX
 SG_ AuxI_O71 : 42|2@1+ (1,0) [0|3] "" Vector__XXX
 SG_ AuxI_O72 : 40|2@1+ (1,0) [0|3] "" Vector__XXX
 SG_ AuxI_O65 : 38|2@1+ (1,0) [0|3] "" Vector__XXX
 SG_ AuxI_O66 : 36|2@1+ (1,0) [0|3] "" Vector__XXX
 SG_ AuxI_O67 : 34|2@1+ (1,0) [0|3] "" Vector__XXX
 SG_ AuxI_O68 : 32|2@1+ (1,0) [0|3] "" Vector__XXX
 SG_ AuxI_O61 : 30|2@1+ (1,0) [0|3] "" Vector__XXX
 SG_ AuxI_O62 : 28|2@1+ (1,0) [0|3] "" Vector__XXX
 SG_ AuxI_O63 : 26|2@1+ (1,0) [0|3] "" Vector__XXX
 SG_ AuxI_O64 : 24|2@1+ (1,0) [0|3] "" Vector__XXX
 SG_ AuxI_O57 : 22|2@1+ (1,0) [0|3] "" Vector__XXX
 SG_ AuxI_O58 : 20|2@1+ (1,0) [0|3] "" Vector__XXX
 SG_ AuxI_O59 : 18|2@1+ (1,0) [0|3] "" Vector__XXX
 SG_ AuxI_O60 : 16|2@1+ (1,0) [0|3] "" Vector__XXX
 SG_ AuxI_O53 : 14|2@1+ (1,0) [0|3] "" Vector__XXX
 SG_ AuxI_O54 : 12|2@1+ (1,0) [0|3] "" Vector__XXX
 SG_ AuxI_O55 : 10|2@1+ (1,0) [0|3] "" Vector__XXX
 SG_ AuxI_O56 : 8|2@1+ (1,0) [0|3] "" Vector__XXX
 SG_ AuxI_O49 : 6|2@1+ (1,0) [0|3] "" Vector__XXX
 SG_ AuxI_O50 : 4|2@1+ (1,0) [0|3] "" Vector__XXX
 SG_ AuxI_O51 : 2|2@1+ (1,0) [0|3] "" Vector__XXX
 SG_ AuxI_O52 : 0|2@1+ (1,0) [0|3] "" Vector__XXX

BO_ 2561015550 AUXIO4: 8 Vector__XXX
 SG_ AuxI_O92 : 16|2@1+ (1,0) [0|3] "" Vector__XXX
 SG_ AuxI_O85 : 14|2@1+ (1,0) [0|3] "" Vector__XXX
 SG_ AuxI_O86 : 12|2@1+ (1,0) [0|3] "" Vector__XXX
 SG_ AuxI_O87 : 10|2@1+ (1,0) [0|3] "" Vector__XXX
 SG_ AuxI_O88 : 8|2@1+ (1,0) [0|3] "" Vector__XXX
 SG_ AuxI_O81 : 6|2@1+ (1,0) [0|3] "" Vector__XXX
 SG_ AuxI_O82 : 4|2@1+ (1,0) [0|3] "" Vector__XXX
 SG_ AuxI_O83 : 2|2@1+ (1,0) [0|3] "" Vector__XXX
 SG_ AuxI_O84 : 0|2@1+ (1,0) [0|3] "" Vector__XXX
 SG_ AuxI_O109 : 62|2@1+ (1,0) [0|3] "" Vector__XXX
 SG_ AuxI_O110 : 60|2@1+ (1,0) [0|3] "" Vector__XXX
 SG_ AuxI_O111 : 58|2@1+ (1,0) [0|3] "" Vector__XXX
 SG_ AuxI_O112 : 56|2@1+ (1,0) [0|3] "" Vector__XXX
 SG_ AuxI_O105 : 54|2@1+ (1,0) [0|3] "" Vector__XXX
 SG_ AuxI_O106 : 52|2@1+ (1,0) [0|3] "" Vector__XXX
 SG_ AuxI_O107 : 50|2@1+ (1,0) [0|3] "" Vector__XXX
 SG_ AuxI_O108 : 48|2@1+ (1,0) [0|3] "" Vector__XXX
 SG_ AuxI_O101 : 46|2@1+ (1,0) [0|3] "" Vector__XXX
 SG_ AuxI_O102 : 44|2@1+ (1,0) [0|3] "" Vector__XXX
 SG_ AuxI_O103 : 42|2@1+ (1,0) [0|3] "" Vector__XXX
 SG_ AuxI_O104 : 40|2@1+ (1,0) [0|3] "" Vector__XXX
 SG_ AuxI_O97 : 38|2@1+ (1,0) [0|3] "" Vector__XXX
 SG_ AuxI_O98 : 36|2@1+ (1,0) [0|3] "" Vector__XXX
 SG_ AuxI_O99 : 34|2@1+ (1,0) [0|3] "" Vector__XXX
 SG_ AuxI_O100 : 32|2@1+ (1,0) [0|3] "" Vector__XXX
 SG_ AuxI_O93 : 30|2@1+ (1,0) [0|3] "" Vector__XXX
 SG_ AuxI_O94 : 28|2@1+ (1,0) [0|3] "" Vector__XXX
 SG_ AuxI_O95 : 26|2@1+ (1,0) [0|3] "" Vector__XXX
 SG_ AuxI_O96 : 24|2@1+ (1,0) [0|3] "" Vector__XXX
 SG_ AuxI_O89 : 22|2@1+ (1,0) [0|3] "" Vector__XXX
 SG_ AuxI_O90 : 20|2@1+ (1,0) [0|3] "" Vector__XXX
 SG_ AuxI_O91 : 18|2@1+ (1,0) [0|3] "" Vector__XXX

BO_ 2566746622 BSA: 8 Vector__XXX
 SG_ TrailerBrakeStrokeAxle5Right : 57|3@1+ (1,0) [0|7] "" Vector__XXX
 SG_ TrailerBrakeStrokeAxle5Left : 54|3@1+ (1,0) [0|7] "" Vector__XXX
 SG_ TrailerBrakeStrokeAxle4Right : 51|3@1+ (1,0) [0|7] "" Vector__XXX
 SG_ TrailerBrakeStrokeAxle4Left : 48|3@1+ (1,0) [0|7] "" Vector__XXX
 SG_ TrailerBrakeStrokeAxle3Right : 45|3@1+ (1,0) [0|7] "" Vector__XXX
 SG_ TrailerBrakeStrokeAxle3Left : 42|3@1+ (1,0) [0|7] "" Vector__XXX
 SG_ TrailerBrakeStrokeAxle2Right : 39|3@1+ (1,0) [0|7] "" Vector__XXX
 SG_ TrailerBrakeStrokeAxle2Left : 36|3@1+ (1,0) [0|7] "" Vector__XXX
 SG_ TrailerBrakeStrokeAxle1Right : 33|3@1+ (1,0) [0|7] "" Vector__XXX
 SG_ TrailerBrakeStrokeAxle1Left : 30|3@1+ (1,0) [0|7] "" Vector__XXX
 SG_ TractorBrakeStrokeAxle5Right : 27|3@1+ (1,0) [0|7] "" Vector__XXX
 SG_ TractorBrakeStrokeAxle5Left : 24|3@1+ (1,0) [0|7] "" Vector__XXX
 SG_ TractorBrakeStrokeAxle4Right : 21|3@1+ (1,0) [0|7] "" Vector__XXX
 SG_ TractorBrakeStrokeAxle4Left : 18|3@1+ (1,0) [0|7] "" Vector__XXX
 SG_ TractorBrakeStrokeAxle3Right : 15|3@1+ (1,0) [0|7] "" Vector__XXX
 SG_ TractorBrakeStrokeAxle3Left : 12|3@1+ (1,0) [0|7] "" Vector__XXX
 SG_ TractorBrakeStrokeAxle2Right : 9|3@1+ (1,0) [0|7] "" Vector__XXX
 SG_ TractorBrakeStrokeAxle2Left : 6|3@1+ (1,0) [0|7] "" Vector__XXX
 SG_ TractorBrakeStrokeAxle1Right : 3|3@1+ (1,0) [0|7] "" Vector__XXX
 SG_ TractorBrakeStrokeAxle1Left : 0|3@1+ (1,0) [0|7] "" Vector__XXX

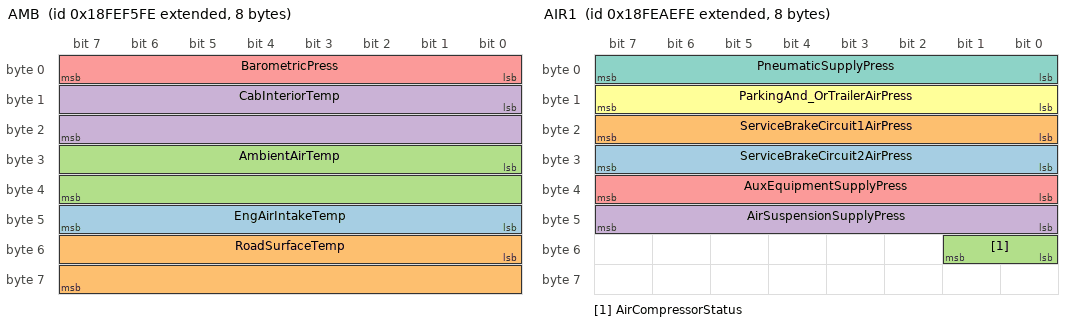
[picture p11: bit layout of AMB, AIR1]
BO_ 2566845950 AMB: 8 Vector__XXX
 SG_ EngAirIntakeTemp : 40|8@1+ (1,-40) [-40|210] "deg C" Vector__XXX
 SG_ RoadSurfaceTemp : 48|16@1+ (0.03125,-273) [-273|1734.96875] "deg C" Vector__XXX
 SG_ AmbientAirTemp : 24|16@1+ (0.03125,-273) [-273|1734.96875] "deg C" Vector__XXX
 SG_ CabInteriorTemp : 8|16@1+ (0.03125,-273) [-273|1734.96875] "deg C" Vector__XXX
 SG_ BarometricPress : 0|8@1+ (0.5,0) [0|125] "kPa" Vector__XXX

BO_ 2566840062 AIR2: 8 Vector__XXX
 SG_ EngAirStartPress : 0|8@1+ (4,0) [0|1000] "kPa" Vector__XXX

BO_ 2566827774 AIR1: 8 Vector__XXX
 SG_ ServiceBrakeCircuit2AirPress : 24|8@1+ (8,0) [0|2000] "kPa" Vector__XXX
 SG_ ServiceBrakeCircuit1AirPress : 16|8@1+ (8,0) [0|2000] "kPa" Vector__XXX
 SG_ AirCompressorStatus : 48|2@1+ (1,0) [0|3] "" Vector__XXX
 SG_ AirSuspensionSupplyPress : 40|8@1+ (8,0) [0|2000] "kPa" Vector__XXX
 SG_ AuxEquipmentSupplyPress : 32|8@1+ (8,0) [0|2000] "kPa" Vector__XXX
 SG_ ParkingAnd_OrTrailerAirPress : 8|8@1+ (8,0) [0|2000] "kPa" Vector__XXX
 SG_ PneumaticSupplyPress : 0|8@1+ (8,0) [0|2000] "kPa" Vector__XXX

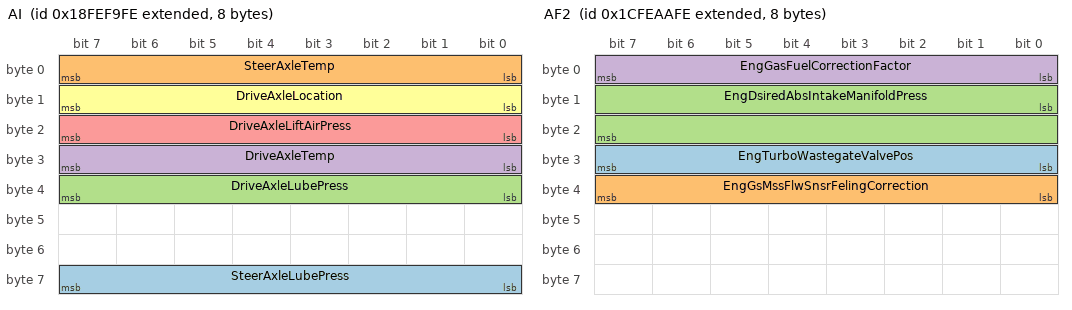
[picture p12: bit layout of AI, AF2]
BO_ 2566846974 AI: 8 Vector__XXX
 SG_ SteerAxleLubePress : 56|8@1+ (4,0) [0|1000] "kPa" Vector__XXX
 SG_ SteerAxleTemp : 0|8@1+ (1,-40) [-40|210] "deg C" Vector__XXX
 SG_ DriveAxleLubePress : 32|8@1+ (4,0) [0|1000] "kPa" Vector__XXX
 SG_ DriveAxleTemp : 24|8@1+ (1,-40) [-40|210] "deg C" Vector__XXX
 SG_ DriveAxleLiftAirPress : 16|8@1+ (4,0) [0|1000] "kPa" Vector__XXX
 SG_ DriveAxleLocation : 8|8@1+ (1,0) [0|255] "" Vector__XXX

BO_ 2633935614 AF2: 8 Vector__XXX
 SG_ EngTurboWastegateValvePos : 24|8@1+ (0.4,0) [0|100] "%" Vector__XXX
 SG_ EngGsMssFlwSnsrFelingCorrection : 32|8@1+ (1,-125) [-125|125] "%" Vector__XXX
 SG_ EngDsiredAbsIntakeManifoldPress : 8|16@1+ (0.1,0) [0|6425.5] "kPa" Vector__XXX
 SG_ EngGasFuelCorrectionFactor : 0|8@1+ (1,0) [0|250] "%" Vector__XXX

BO_ 2566803966 ACC2: 8 Vector__XXX
 SG_ ACCUsageDemand : 0|2@1+ (1,0) [0|3] "" Vector__XXX
 SG_ RqedACCDistanceMode : 5|3@1+ (1,0) [0|7] "" Vector__XXX

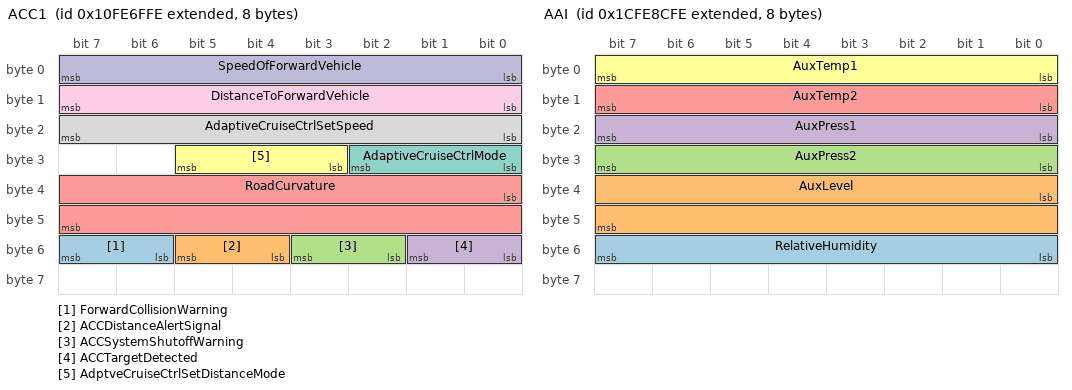
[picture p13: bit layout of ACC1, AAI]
BO_ 2432593918 ACC1: 8 Vector__XXX
 SG_ ForwardCollisionWarning : 54|2@1+ (1,0) [0|3] "" Vector__XXX
 SG_ ACCDistanceAlertSignal : 52|2@1+ (1,0) [0|3] "" Vector__XXX
 SG_ ACCSystemShutoffWarning : 50|2@1+ (1,0) [0|3] "" Vector__XXX
 SG_ ACCTargetDetected : 48|2@1+ (1,0) [0|3] "" Vector__XXX
 SG_ RoadCurvature : 32|16@1+ (0.0078125,-250) [-250|251.992] "1/km" Vector__XXX
 SG_ AdptveCruiseCtrlSetDistanceMode : 27|3@1+ (1,0) [0|7] "" Vector__XXX
 SG_ AdaptiveCruiseCtrlMode : 24|3@1+ (1,0) [0|7] "" Vector__XXX
 SG_ AdaptiveCruiseCtrlSetSpeed : 16|8@1+ (1,0) [0|250] "km/h" Vector__XXX
 SG_ DistanceToForwardVehicle : 8|8@1+ (1,0) [0|250] "m" Vector__XXX
 SG_ SpeedOfForwardVehicle : 0|8@1+ (1,0) [0|250] "km/h" Vector__XXX

BO_ 2633935102 AC: 8 Vector__XXX
 SG_ ArticulationAngle : 0|8@1+ (1,-125) [-125|125] "deg" Vector__XXX

BO_ 2633927934 AAI: 8 Vector__XXX
 SG_ RelativeHumidity : 48|8@1+ (0.4,0) [0|100] "%" Vector__XXX
 SG_ AuxLevel : 32|16@1+ (0.1,0) [0|6425.5] "mm" Vector__XXX
 SG_ AuxPress2 : 24|8@1+ (16,0) [0|4000] "kPa" Vector__XXX
 SG_ AuxPress1 : 16|8@1+ (16,0) [0|4000] "kPa" Vector__XXX
 SG_ AuxTemp2 : 8|8@1+ (1,-40) [-40|210] "deg C" Vector__XXX
 SG_ AuxTemp1 : 0|8@1+ (1,-40) [-40|210] "deg C" Vector__XXX

BO_ 2566847998 A1: 8 Vector__XXX
 SG_ EngBlowerBypassValvePos : 0|8@1+ (0.4,0) [0|100] "%" Vector__XXX
 SG_ EngGasSupplyPress : 8|16@1+ (0.5,0) [0|32127.5] "kPa" Vector__XXX

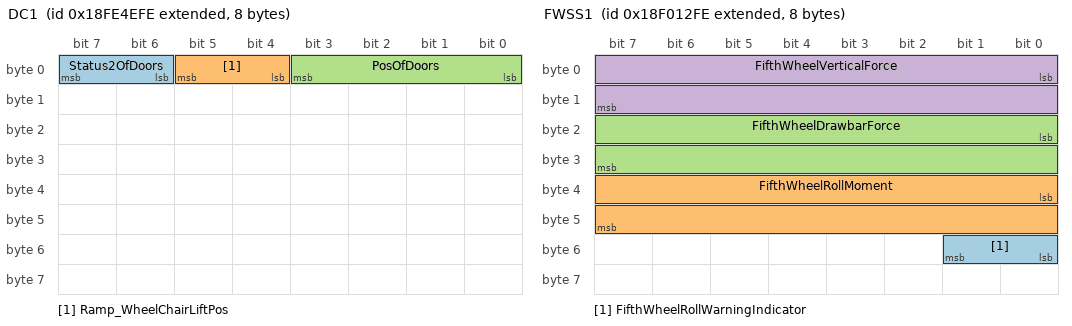
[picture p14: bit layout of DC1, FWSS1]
BO_ 2566803198 DC1: 8 Vector__XXX
 SG_ Status2OfDoors : 6|2@1+ (1,0) [0|3] "" Vector__XXX
 SG_ Ramp_WheelChairLiftPos : 4|2@1+ (1,0) [0|3] "" Vector__XXX
 SG_ PosOfDoors : 0|4@1+ (1,0) [0|15] "" Vector__XXX

BO_ 2565870334 FWSS1: 8 Vector__XXX
 SG_ FifthWheelRollWarningIndicator : 48|2@1+ (1,0) [0|3] "" Vector__XXX
 SG_ FifthWheelRollMoment : 32|16@1+ (10,-320000) [-320000|322550] "N" Vector__XXX
 SG_ FifthWheelDrawbarForce : 16|16@1+ (10,-320000) [-320000|322550] "N" Vector__XXX
 SG_ FifthWheelVerticalForce : 0|16@1+ (5,0) [0|321275] "N" Vector__XXX

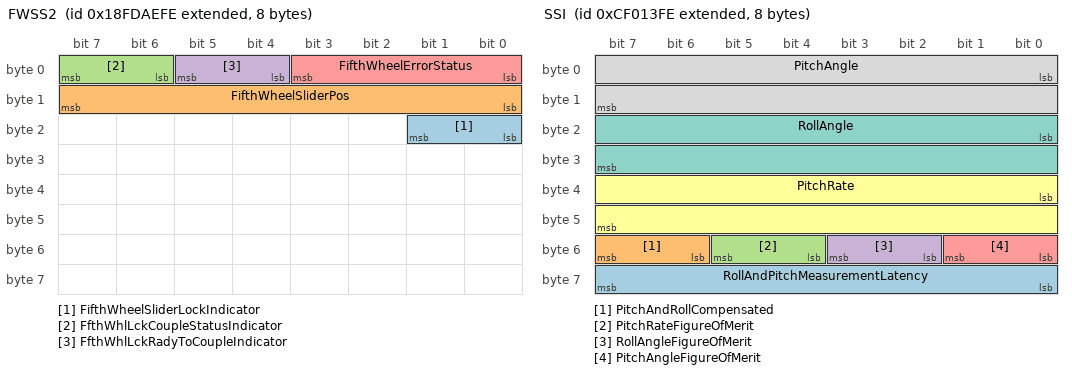
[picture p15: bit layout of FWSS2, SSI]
BO_ 2566762238 FWSS2: 8 Vector__XXX
 SG_ FifthWheelSliderLockIndicator : 16|2@1+ (1,0) [0|3] "" Vector__XXX
 SG_ FifthWheelSliderPos : 8|8@1+ (10,0) [0|2500] "mm" Vector__XXX
 SG_ FfthWhlLckCoupleStatusIndicator : 6|2@1+ (1,0) [0|3] "" Vector__XXX
 SG_ FfthWhlLckRadyToCoupleIndicator : 4|2@1+ (1,0) [0|3] "" Vector__XXX
 SG_ FifthWheelErrorStatus : 0|4@1+ (1,0) [0|15] "" Vector__XXX

BO_ 2364543998 SSI: 8 Vector__XXX
 SG_ RollAndPitchMeasurementLatency : 56|8@1+ (0.5,0) [0|125] "ms" Vector__XXX
 SG_ PitchAndRollCompensated : 54|2@1+ (1,0) [0|3] "" Vector__XXX
 SG_ PitchRateFigureOfMerit : 52|2@1+ (1,0) [0|3] "" Vector__XXX
 SG_ RollAngleFigureOfMerit : 50|2@1+ (1,0) [0|3] "" Vector__XXX
 SG_ PitchAngleFigureOfMerit : 48|2@1+ (1,0) [0|3] "" Vector__XXX
 SG_ PitchRate : 32|16@1+ (0.002,-64) [-64|64.51] "deg/sec" Vector__XXX
 SG_ RollAngle : 16|16@1+ (0.002,-64) [-64|64.51] "deg" Vector__XXX
 SG_ PitchAngle : 0|16@1+ (0.002,-64) [-64|64.51] "deg" Vector__XXX

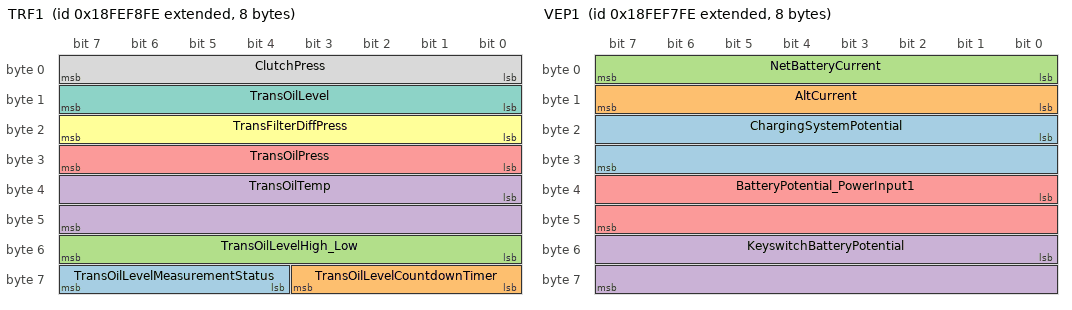
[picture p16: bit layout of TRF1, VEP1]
BO_ 2566846718 TRF1: 8 Vector__XXX
 SG_ TransOilLevelMeasurementStatus : 60|4@1+ (1,0) [0|15] "" Vector__XXX
 SG_ TransOilLevelCountdownTimer : 56|4@1+ (1,0) [0|15] "" Vector__XXX
 SG_ TransOilLevelHigh_Low : 48|8@1+ (0.5,-62.5) [-62.5|62.5] "L" Vector__XXX
 SG_ TransOilTemp : 32|16@1+ (0.03125,-273) [-273|1734.96875] "deg C" Vector__XXX
 SG_ TransOilPress : 24|8@1+ (16,0) [0|4000] "kPa" Vector__XXX
 SG_ TransFilterDiffPress : 16|8@1+ (2,0) [0|500] "kPa" Vector__XXX
 SG_ TransOilLevel : 8|8@1+ (0.4,0) [0|100] "%" Vector__XXX
 SG_ ClutchPress : 0|8@1+ (16,0) [0|4000] "kPa" Vector__XXX

BO_ 2566846462 VEP1: 8 Vector__XXX
 SG_ ChargingSystemPotential : 16|16@1+ (0.05,0) [0|3212.75] "V" Vector__XXX
 SG_ AltCurrent : 8|8@1+ (1,0) [0|250] "A" Vector__XXX
 SG_ NetBatteryCurrent : 0|8@1+ (1,-125) [-125|125] "A" Vector__XXX
 SG_ KeyswitchBatteryPotential : 48|16@1+ (0.05,0) [0|3212.75] "V" Vector__XXX
 SG_ BatteryPotential_PowerInput1 : 32|16@1+ (0.05,0) [0|3212.75] "V" Vector__XXX

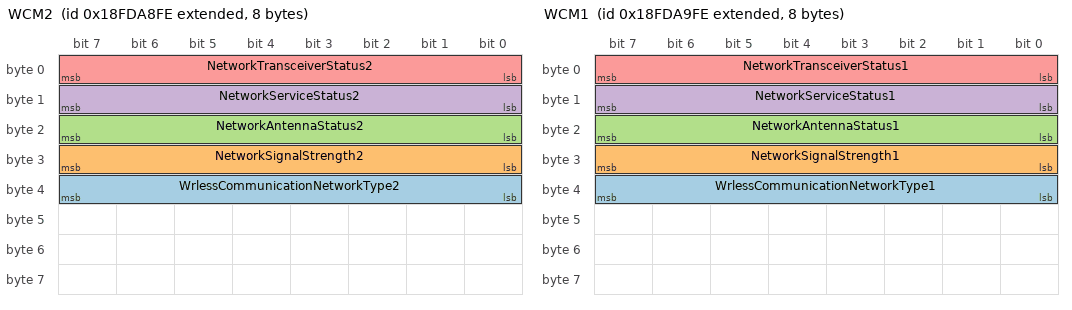
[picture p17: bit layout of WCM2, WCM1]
BO_ 2566760702 WCM2: 8 Vector__XXX
 SG_ WrlessCommunicationNetworkType2 : 32|8@1+ (1,0) [0|255] "" Vector__XXX
 SG_ NetworkSignalStrength2 : 24|8@1+ (0.4,0) [0|100] "%" Vector__XXX
 SG_ NetworkAntennaStatus2 : 16|8@1+ (1,0) [0|255] "" Vector__XXX
 SG_ NetworkServiceStatus2 : 8|8@1+ (1,0) [0|255] "" Vector__XXX
 SG_ NetworkTransceiverStatus2 : 0|8@1+ (1,0) [0|255] "" Vector__XXX

BO_ 2566760958 WCM1: 8 Vector__XXX
 SG_ WrlessCommunicationNetworkType1 : 32|8@1+ (1,0) [0|255] "" Vector__XXX
 SG_ NetworkSignalStrength1 : 24|8@1+ (0.4,0) [0|100] "%" Vector__XXX
 SG_ NetworkAntennaStatus1 : 16|8@1+ (1,0) [0|255] "" Vector__XXX
 SG_ NetworkServiceStatus1 : 8|8@1+ (1,0) [0|255] "" Vector__XXX
 SG_ NetworkTransceiverStatus1 : 0|8@1+ (1,0) [0|255] "" Vector__XXX

CM_ BO_ 2566745342  "Aftertreatment 2 Air Control 2";
CM_ BO_ 2566758654  "Aftertreatment 2 Fuel Control 1";
CM_ BO_ 2566753278  "Aftertreatment 2 Gas Parameters";
CM_ BO_ 2566756862  "Aftertreatment 2 Historical information";
CM_ BO_ 2565869822  "Aftertreatment 2 Intake Gas 1";
CM_ BO_ 2566763006  "Aftertreatment 2 Intake Gas 2";
CM_ BO_ 2566762494  "Aftertreatment 2 Intermediate Gas";
CM_ BO_ 2565870078  "Aftertreatment 2 Outlet Gas 1";
CM_ BO_ 2566762750  "Aftertreatment 2 Outlet Gas 2";
CM_ BO_ 2566748926  "Aftertreatment 2 Service";
CM_ BO_ 2566748414  "Aftertreatment 2 Trip Information";
CM_ BO_ 2365428478  "Engine Operating Information";
CM_ BO_ 2566743806  "Engine Temperature 4";
CM_ BO_ 2499635454  "Gross Combination Vehicle Weight";
CM_ BO_ 2550660862  "General Purpose Valve Pressure";
CM_ BO_ 2566805758  "Air Suspension Control 4";
CM_ BO_ 2566806014  "Air Suspension Control 3";
CM_ BO_ 2362638078  "Air Suspension Control 2";
CM_ BO_ 2365479678  "Air Suspension Control 1";
CM_ BO_ 2566837758  "Alternator Information";
CM_ BO_ 2633922558  "Auxiliary Pressures";
CM_ BO_ 2566775038  "Ambient Conditions 2";
CM_ BO_ 2499635966  "Axle Group Weight";
CM_ BO_ 2633853438  "Axle Group Calibration Weights";
CM_ BO_ 2432520702  "Aftercooler Coolant Control Valve Command";
CM_ BO_ 2566745086  "Available Axle Group Weights";
CM_ BO_ 2566744062  "Zero Net Vehicle Weight Change";
CM_ BO_ 2499630078  "Reports averaged engine information";
CM_ BO_ 2566754558  "Advertised Engine Torque Curve";
CM_ BO_ 2566749950  "Adaptive Front-Lighting System Status";
CM_ BO_ 2566838782  "Auxiliary Input/Output Status 1";
CM_ BO_ 2561146622  "Auxiliary Input/Output Status 2";
CM_ BO_ 2561081086  "Auxiliary Input/Output Status 3";
CM_ BO_ 2561015550  "Auxiliary Input/Output Status 4";
CM_ BO_ 2566746622  "Brake actuator stroke status";
CM_ BO_ 2566845950  "Ambient Conditions";
CM_ BO_ 2566840062  "Air Start Pressure";
CM_ BO_ 2566827774  "Air Supply Pressure";
CM_ BO_ 2566846974  "Axle Information";
CM_ BO_ 2633935614  "Alternate Fuel 2";
CM_ BO_ 2566803966  "Adaptive Cruise Control, Operator Input";
CM_ BO_ 2432593918  "Adaptive Cruise Control";
CM_ BO_ 2633935102  "Articulation Control";
CM_ BO_ 2633927934  "Auxiliary Analog Information";
CM_ BO_ 2566847998  "Alternate Fuel 1";
CM_ BO_ 2566803198  "Door Control 1";
CM_ BO_ 2565870334  "Fifth Wheel Smart Systems 1";
CM_ BO_ 2566762238  "Fifth Wheel Smart Systems 2";
CM_ BO_ 2364543998  "Slope Sensor Information";
CM_ BO_ 2566846718  "Transmission Fluids 1";
CM_ BO_ 2566846462  "Vehicle Electrical Power 1";
CM_ BO_ 2566760702  "Wireless Communications Message 2";
CM_ BO_ 2566760958  "Wireless Communications Message 1";
CM_ SG_ 2566745342 Aftertreatment2SecondAirPress "Pressure of the secondary air for aftertreatment 2.";
CM_ SG_ 2566745342 Aftrtreatment2SecondAirMassFlow "Indicates the secondary air mass flow for aftertreatment 2.";
CM_ SG_ 2566745342 Aftertreatment2SecondAirTemp "Indicates the secondary air temperature for aftertreatment 2.";
CM_ SG_ 2566745342 Aftrtratment2SecondAirDiffPress "Indicates the secondary air differential pressure for aftertreatment 2.";
CM_ SG_ 2566758654 Aftrtrtmnt2FlInjctor1HeaterCtrl "Heating level that the controller is commanding the aftertreatment 2 fuel injector 1 heater control to maintain.";
CM_ SG_ 2566758654 Aftertreatment2FuelPress1Ctrl "Position that the controller is commanding the aftertreatment 2 fuel pressure control to maintain.";
CM_ SG_ 2566758654 Aftertreatment2FuelPress1 "Pressure of the fuel for Aftertreatment 2.";
CM_ SG_ 2566758654 Aftrtratment2FuelEnableActuator "Indicates whether aftertreatment 2 fuel enable actuator is on or off";
CM_ SG_ 2566758654 Aftrtratment2RegenerationStatus "Indicates whether regeneration is active or inactive in aftertreatment 2.";
CM_ SG_ 2566758654 Aftertreatment2Ignt "Indicates whether aftertreatment 2 ignition circuit is energized by the ECM.";
CM_ SG_ 2566758654 Aftrtreatment2FuelDrainActuator "Indicates whether aftertreatment 2 fuel drain actuator is on or off";
CM_ SG_ 2566758654 Aftertreatment2FuelRate "Rate of fuel being delivered to aftertreatment 2 for regeneration";
CM_ SG_ 2566753278 DslPrticulateFilterOutletPress2 "This parameter indicates the diesel particulate filter outlet gage pressure 2 (bank 2).";
CM_ SG_ 2566753278 DslPrticulateFilterIntakePress2 "This parameter indicates the diesel particulate filter intake gage pressure 2 (bank 2).";
CM_ SG_ 2566756862 Aftrtrtmnt2TtlNmbrOfActvRgnrtnMn "Total number of Aftertreatment device 2 active regeneration manual requests by the operator over the lifetime of the";
CM_ SG_ 2566756862 Aftrtrtmnt2TtlNmbrOfActvRgnrtnIn "Total number of Aftertreatment device 2 active regeneration inhibit requests by the operator over the lifetime of the";
CM_ SG_ 2566756862 Aftrtrtmnt2AvrgTmBtwnActvRgnrtns "Indicates the average time since last reset between active regenerations, that have not been forced to occur by manual";
CM_ SG_ 2566756862 Aftrtrtmnt2TtlNmbrOfPssvRgnrtns "Total number of passive regenerations by Aftertreatment device 2 over the lifetime of the device.";
CM_ SG_ 2566756862 Aftrtrtmnt2TtlPssvRgnrationTime "Total amount of time that Aftertreatment device 2 has been in passive regeneration over the lifetime of the device.";
CM_ SG_ 2566756862 Aftrtrtmnt2TtlNmbrOfActvRgnrtns "Total number of active regenerations by aftertreatment device 2 over the lifetime of the device.";
CM_ SG_ 2566756862 Aftrtreatment2TotalDisabledTime "Total amount of time that aftertreatment 2 regeneration has been manually disabled.";
CM_ SG_ 2566756862 Aftrtrtmnt2TtalRegenerationTime "Total amount of time that aftertreatment device 2 has been regenerating over the lifetime of the device.";
CM_ SG_ 2566756862 Aftertreatment2TotalFuelUsed "Total amount of fuel used by aftertreatment device 2 over the lifetime of the device.";
CM_ SG_ 2565869822 Aftrtrtmnt2IntkOxygnSnsrPrlmnryF "Used to identify the applicable J1939-73 FMI detected in the aftertreatment intake oxygen sensor by the manufacturer's";
CM_ SG_ 2565869822 Aftrtrtmnt2IntkGsSnsrPwerStatus "Indicates that the power supplied to the aftertreatment intake gas sensor, either NOx or O2, is within the manufacturer's";
CM_ SG_ 2565869822 Aftrtrtmnt2IntkGsSnsrHtrPrlmnryF "Used to identify the applicable J1939-73 FMI detected in the heater of the intake exhaust gas sensor, either NOx or O2,";
CM_ SG_ 2565869822 Aftrtrtmnt2IntkNOxSnsrPrlmnryFMI "Used to identify the applicable J1939-73 FMI detected in the aftertreatment intake NOx sensor by the manufacturer's";
CM_ SG_ 2565869822 Aftrtrtmnt2IntkGsSnsrHeaterCtrl "Indicates the heater status in the warm-up process.";
CM_ SG_ 2565869822 Aftrtrtmnt2IntkWdRngO2RdngStble "Indicates that the %O2 reading of the aftertreatment intake gas sensor, either NOx or O2, is stable as determined by the";
CM_ SG_ 2565869822 Aftrtrtmnt2IntkNOxReadingStable "Indicates that the NOx reading of the aftertreatment intake NOx sensor is stable as determined by the manufacturer's";
CM_ SG_ 2565869822 Aftrtrtmnt2IntkeGasSensorAtTemp "Indicates that the heater element of the aftertreatment intake gas sensor, either NOx or O2, is within the manufacturer's";
CM_ SG_ 2565869822 Aftertreatment2IntakeO2 "The actual oxidation factor (%O2) of the gas within the exhaust stream.";
CM_ SG_ 2565869822 Aftertreatment2IntakeNOx "The amount of combined NO and NO2 in the exhaust entering the aftertreatment system measured by a NOx sensor at";
CM_ SG_ 2566763006 Aftrtrtmnt2DslPrtcltFltrIntkGsTm0 "Used to identify the applicable J1939-73 FMI detected in the diesel particulate filter intake gas temperature sensor by the";
CM_ SG_ 2566763006 Aftrtrtmnt2ExhstGsTmp1PrlmnryFMI "Used to identify the applicable J1939-73 FMI detected in the exhaust gas temperature 1 sensor by the manufacturer's";
CM_ SG_ 2566763006 Aftertreatment2ExhaustGasTemp1 "The reading from the exhaust gas temperature sensor located farthest upstream in the aftertreatment system in exhaust bank 2.";
CM_ SG_ 2566763006 Aftrtrtmnt2DslPrtcltFltrIntkGsTm1 "Temperature of engine combustion byproducts entering the diesel particulate filter in exhaust bank 2.";
CM_ SG_ 2566762494 Aftrtrtmnt2DslPrtcltFltrIntrmdtG0 "Used to identify the applicable J1939-73 FMI detected in the diesel particulate filter intermediate gas temperature sensor";
CM_ SG_ 2566762494 Aftrtrtmnt2DslPrtcltFltrIntrmdtG1 "Temperature of engine combustion byproducts at a mid-point in the diesel particulate filter in exhaust bank 2.";
CM_ SG_ 2566762494 Aftrtrtmnt2DslPrtcltFltrDltPrssP "Used to identify the applicable J1939-73 FMI detected in the diesel particulate filter differential pressure sensor by the";
CM_ SG_ 2566762494 Aftrtrtmnt2DslPrtcltFltrDffPrss "Exhaust differential pressure measured between the intake and exhaust of a diesel particulate filter in exhaust bank 2.";
CM_ SG_ 2566762494 Aftrtrtmnt2ExhstGsTmp2PrlmnryFMI "Used to identify the applicable J1939-73 FMI detected in the exhaust gas temperature 2 sensor by the manufacturer's";
CM_ SG_ 2566762494 Aftertreatment2ExhaustGasTemp2 "The reading from the exhaust gas temperature sensor located midstream of the other two temperature sensors in the";
CM_ SG_ 2565870078 Aftrtrtmnt2OtltOxygnSnsrPrlmnryF "Used to identify the applicable J1939-73 FMI detected in the aftertreatment outlet oxygen sensor by the manufacturer's";
CM_ SG_ 2565870078 Aftrtrtmnt2OtltGsSnsrPwerStatus "Indicates that the power supplied to the aftertreatment outlet gas sensor, either NOx or O2, is within the manufacturer's";
CM_ SG_ 2565870078 Aftrtrtmnt2OtltGsSnsrHtrPrlmnryF "Used to identify the applicable J1939-73 FMI detected in the heater of the outlet exhaust gas sensor, either NOx or O2, by";
CM_ SG_ 2565870078 Aftrtrtmnt2OtltNOxSnsrPrlmnryFMI "Used to identify the applicable J1939-73 FMI detected in the aftertreatment outlet NOx sensor by the manufacturer's";
CM_ SG_ 2565870078 Aftrtrtmnt2OtltGsSnsrHeaterCtrl "Indicates the heater status in the warm-up process.";
CM_ SG_ 2565870078 Aftrtrtmnt2OtltWdRngO2RdngStble "Indicates that the %O2 reading of the aftertreatment outlet gas sensor, either NOx or O2, is stable as determined by the";
CM_ SG_ 2565870078 Aftrtrtmnt2OtltNOxReadingStable "Indicates that the NOx reading of the aftertreatment outlet NOx sensor is stable as determined by the manufacturer's";
CM_ SG_ 2565870078 Aftrtrtmnt2OtletGasSensorAtTemp "Indicates that the heater element of the aftertreatment outlet gas sensor, either NOx or O2, is within the manufacturer's";
CM_ SG_ 2565870078 Aftertreatment2OutletO2 "The actual oxidation factor (%O2) of the gas within the exhaust stream.";
CM_ SG_ 2565870078 Aftertreatment2OutletNOx "The amount of combined NO and NO2 in the exhaust entering the aftertreatment system measured by a NOx sensor at";
CM_ SG_ 2566762750 Aftrtrtmnt2DslPrtcltFltrOtltGsTm "Temperature of engine combustion byproducts leaving the diesel particulate filter exhaust in exhaust bank 2.";
CM_ SG_ 2566762750 Aftrtrtmnt2DslPrtcltFltrExhstGsT "Used to identify the applicable J1939-73 FMI detected in the diesel particulate filter outlet gas temperature sensor by the";
CM_ SG_ 2566762750 Aftrtrtmnt2ExhstGsTmp3PrlmnryFMI "Used to identify the applicable J1939-73 FMI detected in the exhaust gas temperature 3 sensor by the manufacturer's";
CM_ SG_ 2566762750 Aftertreatment2ExhaustGasTemp3 "The reading from the exhaust gas temperature sensor located farthest downstream in the aftertreatment system in";
CM_ SG_ 2566748926 DslPrtclteFilter2AshLoadPercent "Indicates the ash load percent of diesel particulate filter 2.";
CM_ SG_ 2566748926 DslPrtcltFltr2TmSncLstActvRgnrtn "Indicates the time since the last active regeneration event of diesel particulate filter 2.";
CM_ SG_ 2566748926 DslPrtcltFilter2SootLoadPercent "Indicates the soot load percent of diesel particulate filter 2.";
CM_ SG_ 2566748926 Aftrtrtmnt2DslPrtcltFltrStLdRgnr "This parameter indicates the value that will first cause DPF regeneration in aftertreatment 2.";
CM_ SG_ 2566748414 Aftrtrtmnt2TrpNmbrOfActvRgnrtnMn "Total number of aftertreatment device 2 active regeneration manual requests by the operator during the current trip";
CM_ SG_ 2566748414 Aftrtrtmnt2TrpNmbrOfActvRgnrtnIn "Total number of aftertreatment device 2 active regeneration inhibit requests by the operator during the current trip period.";
CM_ SG_ 2566748414 Aftrtrtmnt2TrpNmbrOfPssvRgnrtns "Total number of passive regenerations by aftertreatment device 2 during the current trip period.";
CM_ SG_ 2566748414 Aftrtrtmnt2TrpPssvRgnrationTime "Total amount of time that aftertreatment device 2 has been in passive regeneration during the current trip period.";
CM_ SG_ 2566748414 Aftrtrtmnt2TrpNmbrOfActvRgnrtns "Total number of active regenerations by aftertreatment device 2 during the current trip period.";
CM_ SG_ 2566748414 Aftertreatment2TripDisabledTime "Total amount of time that aftertreatment 2 regeneration has been manually disabled during the current trip period.";
CM_ SG_ 2566748414 Aftrtrtmnt2TrpActvRgnrationTime "Total amount of time that aftertreatment device 2 has been in active regeneration during the current trip period.";
CM_ SG_ 2566748414 Aftertreatment2TripFuelUsed "Total amount of fuel used by aftertreatment device 2 during the current trip period.";
CM_ SG_ 2365428478 EngDerateRq "This parameter is a derate request made from the engine control system to an external system, where the engine is";
CM_ SG_ 2365428478 EngEmergencyShutdownIndication "A signal issued by the engine control system to a user or external system indicating that it is immediately shutting the engine";
CM_ SG_ 2365428478 EngCtrlledShutdownRq "A signal issued by the engine control system to a user or external system requesting for a controlled shutdown.";
CM_ SG_ 2365428478 EngCoolantCirculatingPumpCtrl "Control setting for an electrically actuated engine coolant circulating pump.";
CM_ SG_ 2365428478 EngBlock_CoolantPreheaterCtrl "Control setting for an electrically actuated engine block or coolant pre-heating device.";
CM_ SG_ 2365428478 EngElctrclSystmPwrCnsrvtionCtrl "Control setting for cutting power to various devices when the engine is not in use.";
CM_ SG_ 2365428478 EngOilPreheaterCtrl "Control setting for an electrically actuated oil pre-heating device.";
CM_ SG_ 2365428478 EngOilPrimingPumpCtrl "This control is used to activate a pump that lubricates the engine, particularly prior to initial engine startup.";
CM_ SG_ 2365428478 EngFuelShutoffValveLeakTestCtrl "Control setting for fuel shutoff valve proving system test.";
CM_ SG_ 2365428478 EngFuelShutoff2Ctrl "Control setting for fuel shutoff 2.";
CM_ SG_ 2365428478 EngFuelShutoff1Ctrl "Control setting for fuel shutoff 1.";
CM_ SG_ 2365428478 EngFuelShutoffVentCtrl "Control setting for a fuel shutoff vent.";
CM_ SG_ 2365428478 TmeRemainingInEngOperatingState "This parameter is used to indicate the time remaining in the current engine operating state, based on the state defined in";
CM_ SG_ 2365428478 FuelPumpPrimerCtrl "Parameter used to activate or deactivate a priming system on the fuel transfer system.";
CM_ SG_ 2365428478 EngOperatingState "This parameter is used to indicate the current state, or mode, of operation by the engine.";
CM_ SG_ 2566743806 EngExhstVlvActtionSystemOilTemp "The temperature of the oil in the hydraulic system that powers the engine exhaust valve actuation system";
CM_ SG_ 2566743806 EngExhstGsRcrcltn1MxrIntakeTemp "The temperature of the EGR gas entering the intake mixer, measured after the intake throttle when provided.";
CM_ SG_ 2566743806 EngCoolantThermostatOpening "The current position of the Thermostat used to regulate the temperature of the engine coolant.";
CM_ SG_ 2566743806 EngCoolantPumpOutletTemp "The actual value of engine coolant temperature at the coolant pump outlet";
CM_ SG_ 2566743806 EngCoolantTemp2 "Second temperature of liquid found in the engine cooling system.";
CM_ SG_ 2499635454 NetVehicleWeightChange "Identifies the net vehicle weight change from the time of last vehicle net weight zeroing.";
CM_ SG_ 2499635454 GrossCombinationWeight "Total weight of the truck and all the trailers with on-board scales.";
CM_ SG_ 2550660862 ValveAssemblySupplyPress "Pressure of the hydraulic supply port to a valve assembly.";
CM_ SG_ 2550660862 ValveAssemblyLoadSensePress "The maximum pressure of a valve assembly's current collective load sense pressures where a valve assembly can";
CM_ SG_ 2550660862 ValvePilotPress "Pressure of a valve's pilot supply port.";
CM_ SG_ 2550660862 ValveLoadSensePress "The maximum of the currently measured pressures of a valve's work port A and work port B.";
CM_ SG_ 2566805758 BellowPressRearAxleRight "Information of the pressure of the air suspension bellow at the right side of the rear axle";
CM_ SG_ 2566805758 BellowPressRearAxleLeft "Information of the pressure of the air suspension bellow at the left side of the rear axle";
CM_ SG_ 2566805758 BellowPressFrontAxleRight "Information of the pressure of the air suspension bellow at the right side of the front axle";
CM_ SG_ 2566805758 BellowPressFrontAxleLeft "Information of the pressure of the air suspension bellow at the left side of the front axle";
CM_ SG_ 2566806014 RelativeLevelRearAxleRight "Information of the height at the left side of the rear axle referred to normal level 1.";
CM_ SG_ 2566806014 RelativeLevelRearAxleLeft "Information of the height at the left side of the rear axle referred to normal level 1.";
CM_ SG_ 2566806014 RelativeLevelFrontAxleRight "Information of the height at the right side of the front axle referred to normal level 1.";
CM_ SG_ 2566806014 RelativeLevelFrontAxleLeft "Information of the height at the left side of the front axle referred to normal level 1.";
CM_ SG_ 2362638078 SpeedDependentLevelCtrlRq "This parameter activates speed dependent level control in suspension system.";
CM_ SG_ 2362638078 PrhbtAutomaticAirSuspensionCtrl "[Ed note - description needs to be reviewed and adjusted as necessary]";
CM_ SG_ 2362638078 MemoryLevelRq "Signal which indicates that the air suspension control requests a memory level or a memory level shall be stored.";
CM_ SG_ 2362638078 AllowLevelCtrlDuringBrakingCmd "This parameter overides the inhibit of level control during braking.";
CM_ SG_ 2362638078 ProhibitAirSuspensionCtrl "This parameter is an external request to the air suspension control system to prohibit all air suspension control.";
CM_ SG_ 2362638078 KneelingCmdRearAxle "Command signal to activate the kneeling functionality at the rear axle of the vehicle.";
CM_ SG_ 2362638078 KneelingCmdFrontAxle "Command signal to activate the kneeling functionality at the front axle of the vehicle";
CM_ SG_ 2362638078 DamperStiffnessRqLift_TagAxle "Demand value for the shock absorber control at the lift or tag axle";
CM_ SG_ 2362638078 DamperStiffnessRqRearAxle "Demand value for the shock absorber control at the rear axle.";
CM_ SG_ 2362638078 DamperStiffnessRqFrontAxle "Demand value for the shock absorber control at the front axle.";
CM_ SG_ 2362638078 LevelCtrlModeRq "Command signal to activate a level control mode";
CM_ SG_ 2362638078 NominalLevelRqRearAxle "Command signal to activate a level of the rear axle programmed and/or memorized in the ECU.";
CM_ SG_ 2362638078 NominalLevelRqFrontAxle "Command signal to activate a level of the front axle programmed and/or memorized in the ECU For explanations of";
CM_ SG_ 2362638078 KneelingCtrlModeRq "Command signal to select the kneeling functionality";
CM_ SG_ 2362638078 KneelingRqRightSide "Command signal to activate the kneeling functionality on the right side of the vehicle";
CM_ SG_ 2362638078 KneelingRqLeftSide "Command signal to activate the kneeling functionality on the left side of the vehicle";
CM_ SG_ 2362638078 AutomaticTractionHelp "This signal enables the traction help (load transfer) in case of an active ASR function";
CM_ SG_ 2362638078 LiftAxle2PosCmd "Signal to command the position / load condition of lift / tag axle #2.";
CM_ SG_ 2362638078 LiftAxle1PosCmd "Signal to command the position/load condition of lift/tag axle #1.";
CM_ SG_ 2365479678 SpeedDependantLevelCtrlStatus "This parameter indicates if the function Speed Dependant Level Control is active.";
CM_ SG_ 2365479678 MemoryLevel "Signal which indicates that the air suspension control has memory levels selected or stored.";
CM_ SG_ 2365479678 AllwLvelCtrlDuringBrakingStatus "This parameter indicates if the function Allow Level Control During Braking is active.";
CM_ SG_ 2365479678 SspensionCtrlRefusalInformation "Signal which indicates that the air suspension control cannot perform a request due to the operating conditions.";
CM_ SG_ 2365479678 SuspensionRemoteCtrl2 "Signal which indicates that the suspension system is controlled by remote control #2.";
CM_ SG_ 2365479678 SuspensionRemoteCtrl1 "Signal which indicates that the suspension system is controlled by remote control #1.";
CM_ SG_ 2365479678 RearAxleInBumperRange "Signal which indicates that the vehicle height at the rear axle (SPNs 1723 and 1724) is within the bumper range.";
CM_ SG_ 2365479678 FrontAxleInBumperRange "Signal which indicates that the vehicle height at the front axle (SPNs 1721 and 1722) is within the bumper range.";
CM_ SG_ 2365479678 DoorRelease "Signal which indicates that the doors may be opened.";
CM_ SG_ 2365479678 VehicleMotionInhibit "Signal which indicates whether vehicle motion is inhibited.";
CM_ SG_ 2365479678 SecurityDevice "The signal which indicates the status of the security device.";
CM_ SG_ 2365479678 LevelCtrlMode "Signal which indicates the actual control mode of the air suspension system";
CM_ SG_ 2365479678 KneelingInformation "Signal which indicates the actual level change in case of kneeling function";
CM_ SG_ 2365479678 LiftingCtrlModeRearAxle "Signal which indicates the actual lifting level change at the rear axle";
CM_ SG_ 2365479678 LiftingCtrlModeFrontAxle "Signal which indicates the actual lifting level change at the front axle";
CM_ SG_ 2365479678 LoweringCtrlModeRearAxle "Signal which indicates the actual lowering level change at the rear axle";
CM_ SG_ 2365479678 LoweringCtrlModeFrontAxle "Signal which indicates the actual lowering level change at the front axle";
CM_ SG_ 2365479678 AboveNominalLevelRearAxle "Signal which indicates whether the actual height of the rear axle is above the nominal (desired) level of the rear axle.";
CM_ SG_ 2365479678 AboveNominalLevelFrontAxle "Signal which indicates whether the actual height of the front axle is above the nominal (desired) level of the front axle.";
CM_ SG_ 2365479678 BelowNominalLevelRearAxle "Signal which indicates whether the actual height of the rear axle is below the nominal (desired) level for the rear axle.";
CM_ SG_ 2365479678 BelowNominalLevelFrontAxle "Signal which indicates whether the actual height of the front axle is below the nominal (desired) level for the front axle.";
CM_ SG_ 2365479678 NominalLevelRearAxle "Signal which indicates the nominal (desired) height of the rear axle to be controlled by the suspension system.";
CM_ SG_ 2365479678 NominalLevelFrontAxle "Signal which indicates the nominal (desired) height of the front axle to be controlled by the suspension system.";
CM_ SG_ 2365479678 LiftAxle2Pos "Signal which indicates the position / load condition of lift axle / tag axle #2.";
CM_ SG_ 2365479678 LiftAxle1Pos "Signal which indicates the position / load condition of lift axle / tag axle #1.";
CM_ SG_ 2566837758 Alt4Status "Alternator 4 operating status.";
CM_ SG_ 2566837758 Alt3Status "Alternator 3 operating status.";
CM_ SG_ 2566837758 Alt2Status "Alternator 2 operating status.";
CM_ SG_ 2566837758 Alt1Status "Alternator 1 operating status.";
CM_ SG_ 2566837758 AltSpeed "Actual rotation speed of the alternator.";
CM_ SG_ 2633922558 AuxAbsPressReading "Identifies the current absolute pressure (relative to 0 pressure) that is configured uniquely per application.";
CM_ SG_ 2633922558 AuxGagePressReading1 "Identifies the current gage pressure (relative to atmosphere) that is configured uniquely per application.";
CM_ SG_ 2633922558 AuxVacuumPressReading "Identifies the current vacuum pressure (relative to atmosphere) that is configured uniquely per application.";
CM_ SG_ 2566775038 SpecificHumidity "Specific humidity of the ambient intake air.";
CM_ SG_ 2566775038 SolarSensorMax "This is the maximum value which can be reported by the sensor for the solar intensity.";
CM_ SG_ 2566775038 SolarIntensityPercent "This is the solar radiation (power density) falling on the vehicle in percent of the maximum sensor value (SPN 2611).";
CM_ SG_ 2499635966 AxleGroupWeight "Total mass imposed on the road surface by all the tires in the axle group";
CM_ SG_ 2499635966 AxleGroupLocation "Specific axle group used in conjunction with and when communicating the axle group weight, listed from the front of the";
CM_ SG_ 2633853438 AxleGroupLocation "Specific axle group used in conjunction with and when communicating the axle group calibration, listed from the front of";
CM_ SG_ 2633853438 AxleGroupFullWeightCalib "The full weight calibration measurement of an axle group";
CM_ SG_ 2633853438 AxleGroupEmptyWeightCalib "The empty weight calibration measurement of an axle group";
CM_ SG_ 2432520702 DsrdAftrcoolerCoolantIntakeTemp "Indicates the desired temperature of the fluid in the low temperature aftercooler circuit to an electronic thermostat.";
CM_ SG_ 2432520702 DsrdAftrclrClntThrmostatOpening "Used to transmit the desired position of the low temperature aftercooler temperature control valve.";
CM_ SG_ 2432520702 AftrcoolerCoolantThermostatMode "Specifies if the aftercooler coolant thermostat valve will operate in temperature control mode or position control mode.";
CM_ SG_ 2566745086 AddtnlTrlrAxlGrpWeightAvailable "Indicates the availability of the additional trailer axle group for purposes of weight measurement";
CM_ SG_ 2566745086 TrilerHAxleGroupWeightAvailable "Indicates the availability of the trailer H axle group for purposes of weight measurement";
CM_ SG_ 2566745086 TrilerGAxleGroupWeightAvailable "Indicates the availability of the trailer G axle group for purposes of weight measurement";
CM_ SG_ 2566745086 TrilerFAxleGroupWeightAvailable "Indicates the availability of the trailer F axle group for purposes of weight measurement";
CM_ SG_ 2566745086 TrilerEAxleGroupWeightAvailable "Indicates the availability of the trailer E axle group for purposes of weight measurement";
CM_ SG_ 2566745086 TrilerDAxleGroupWeightAvailable "Indicates the availability of the trailer D axle group for purposes of weight measurement";
CM_ SG_ 2566745086 TrilerCAxleGroupWeightAvailable "Indicates the availability of the trailer C axle group for purposes of weight measurement";
CM_ SG_ 2566745086 TrilerBAxleGroupWeightAvailable "Indicates the availability of the trailer B axle group for purposes of weight measurement";
CM_ SG_ 2566745086 TrilerAAxleGroupWeightAvailable "Indicates the availability of the trailer A axle group for purposes of weight measurement";
CM_ SG_ 2566745086 AddtnlTrctrAxlGrpWightAvailable "Indicates the availability of the additional tractor axle group for purposes of weight measurement";
CM_ SG_ 2566745086 TagAxleGroupWeightAvailable "Indicates the availability of the tag axle group for purposes of weight measurement";
CM_ SG_ 2566745086 DriveAxleGroupWeightAvailable "Indicates the availability of the drive axle group for purposes of weight measurement";
CM_ SG_ 2566745086 LiftAxleGroupWeightAvailable "Indicates the availability of the lift axle group for purposes of weight measurement";
CM_ SG_ 2566745086 SteerAxleGroupWeightAvailable "Indicates the availability of the steer axle group for purposes of weight measurement";
CM_ SG_ 2566744062 ZeroNetVehicleWeightChange "Zero Net Vehicle Weight Change command.";
CM_ SG_ 2499630078 EngExhaustGasTempAverageBank2 "The calculated average temperature based upon all of the Bank 2 (right bank) engine exhaust port temperatures.";
CM_ SG_ 2499630078 EngExhaustGasTempAverageBank1 "The calculated average temperature based upon all of the Bank 1 (left bank) engine exhaust port temperatures.";
CM_ SG_ 2499630078 EngExhaustGasTempAverage "The calculated average temperature based upon all of the engine exhaust port temperatures.";
CM_ SG_ 2566754558 AETCTorqueValue "Engine torque value of the data points in PGN 64912 Advertised Engine Torque Curve (AETC).";
CM_ SG_ 2566754558 NumberOfAETCDataPoints "Indicates the number of speed / torque data points contained in the Advertised Engine Torque Curve broadcast (AETC).";
CM_ SG_ 2566754558 AETCDataCollectionStandard "Indicates the standardized method by which torque data was obtained for the Advertised Engine Torque Curve (AETC).";
CM_ SG_ 2566749950 RightHeadlampLightDistribution "This parameter indicates what kind of light distribution is set by the AFS system for the right headlamp.";
CM_ SG_ 2566749950 LeftHeadlampLightDistribution "This parameter indicates what kind of light distribution is set by the AFS system for the left headlamp.";
CM_ SG_ 2566749950 RghtHeadlampDynamicBendingLight "This parameter indicates whether the dynamic bending light of the left headlamp is working properly.";
CM_ SG_ 2566749950 LeftHeadlampDynamicBendingLight "This parameter indicates whether the dynamic bending light of the left headlamp is working properly.";
CM_ SG_ 2566838782 AuxI_O16 "Identifies the current status of auxiliary input/output functions that are configured uniquely per application.";
CM_ SG_ 2566838782 AuxI_O15 "Identifies the current status of auxiliary input/output functions that are configured uniquely per application.";
CM_ SG_ 2566838782 AuxI_O14 "Identifies the current status of auxiliary input/output functions that are configured uniquely per application.";
CM_ SG_ 2566838782 AuxI_O13 "Identifies the current status of auxiliary input/output functions that are configured uniquely per application.";
CM_ SG_ 2566838782 AuxI_O12 "Identifies the current status of auxiliary input/output functions that are configured uniquely per application.";
CM_ SG_ 2566838782 AuxI_O11 "Identifies the current status of auxiliary input/output functions that are configured uniquely per application.";
CM_ SG_ 2566838782 AuxI_O10 "Identifies the current status of auxiliary input/output functions that are configured uniquely per application.";
CM_ SG_ 2566838782 AuxI_O09 "Identifies the current status of auxiliary input/output functions that are configured uniquely per application.";
CM_ SG_ 2566838782 AuxI_O08 "Identifies the current status of auxiliary input/output functions that are configured uniquely per application.";
CM_ SG_ 2566838782 AuxI_O07 "Identifies the current status of auxiliary input/output functions that are configured uniquely per application.";
CM_ SG_ 2566838782 AuxI_O06 "Identifies the current status of auxiliary input/output functions that are configured uniquely per application.";
CM_ SG_ 2566838782 AuxI_O05 "Identifies the current status of auxiliary input/output functions that are configured uniquely per application.";
CM_ SG_ 2566838782 AuxI_O04 "Identifies the current status of auxiliary input/output functions that are configured uniquely per application.";
CM_ SG_ 2566838782 AuxI_O03 "Identifies the current status of auxiliary input/output functions that are configured uniquely per application.";
CM_ SG_ 2566838782 AuxI_O02 "Identifies the current status of auxiliary input/output functions that are configured uniquely per application.";
CM_ SG_ 2566838782 AuxI_O01 "Identifies the current status of auxiliary input/output functions that are configured uniquely per application.";
CM_ SG_ 2566838782 AuxI_OChannel2 "Auxiliary channel of data (16 bit) read by the ECU.";
CM_ SG_ 2566838782 AuxI_OChannel1 "Auxiliary channel of data (16 bit) read by the ECU.";
CM_ SG_ 2561146622 AuxI_O45 "Identifies the current status of auxiliary input/output functions that are configured uniquely per application.";
CM_ SG_ 2561146622 AuxI_O46 "Identifies the current status of auxiliary input/output functions that are configured uniquely per application.";
CM_ SG_ 2561146622 AuxI_O47 "Identifies the current status of auxiliary input/output functions that are configured uniquely per application.";
CM_ SG_ 2561146622 AuxI_O48 "Identifies the current status of auxiliary input/output functions that are configured uniquely per application.";
CM_ SG_ 2561146622 AuxI_O41 "Identifies the current status of auxiliary input/output functions that are configured uniquely per application.";
CM_ SG_ 2561146622 AuxI_O42 "Identifies the current status of auxiliary input/output functions that are configured uniquely per application.";
CM_ SG_ 2561146622 AuxI_O43 "Identifies the current status of auxiliary input/output functions that are configured uniquely per application.";
CM_ SG_ 2561146622 AuxI_O44 "Identifies the current status of auxiliary input/output functions that are configured uniquely per application.";
CM_ SG_ 2561146622 AuxI_O37 "Identifies the current status of auxiliary input/output functions that are configured uniquely per application.";
CM_ SG_ 2561146622 AuxI_O38 "Identifies the current status of auxiliary input/output functions that are configured uniquely per application.";
CM_ SG_ 2561146622 AuxI_O39 "Identifies the current status of auxiliary input/output functions that are configured uniquely per application.";
CM_ SG_ 2561146622 AuxI_O40 "Identifies the current status of auxiliary input/output functions that are configured uniquely per application.";
CM_ SG_ 2561146622 AuxI_O33 "Identifies the current status of auxiliary input/output functions that are configured uniquely per application.";
CM_ SG_ 2561146622 AuxI_O34 "Identifies the current status of auxiliary input/output functions that are configured uniquely per application.";
CM_ SG_ 2561146622 AuxI_O35 "Identifies the current status of auxiliary input/output functions that are configured uniquely per application.";
CM_ SG_ 2561146622 AuxI_O36 "Identifies the current status of auxiliary input/output functions that are configured uniquely per application.";
CM_ SG_ 2561146622 AuxI_O29 "Identifies the current status of auxiliary input/output functions that are configured uniquely per application.";
CM_ SG_ 2561146622 AuxI_O30 "Identifies the current status of auxiliary input/output functions that are configured uniquely per application.";
CM_ SG_ 2561146622 AuxI_O31 "Identifies the current status of auxiliary input/output functions that are configured uniquely per application.";
CM_ SG_ 2561146622 AuxI_O32 "Identifies the current status of auxiliary input/output functions that are configured uniquely per application.";
CM_ SG_ 2561146622 AuxI_O25 "Identifies the current status of auxiliary input/output functions that are configured uniquely per application.";
CM_ SG_ 2561146622 AuxI_O26 "Identifies the current status of auxiliary input/output functions that are configured uniquely per application.";
CM_ SG_ 2561146622 AuxI_O27 "Identifies the current status of auxiliary input/output functions that are configured uniquely per application.";
CM_ SG_ 2561146622 AuxI_O28 "Identifies the current status of auxiliary input/output functions that are configured uniquely per application.";
CM_ SG_ 2561146622 AuxI_O21 "Identifies the current status of auxiliary input/output functions that are configured uniquely per application.";
CM_ SG_ 2561146622 AuxI_O22 "Identifies the current status of auxiliary input/output functions that are configured uniquely per application.";
CM_ SG_ 2561146622 AuxI_O23 "Identifies the current status of auxiliary input/output functions that are configured uniquely per application.";
CM_ SG_ 2561146622 AuxI_O24 "Identifies the current status of auxiliary input/output functions that are configured uniquely per application.";
CM_ SG_ 2561146622 AuxI_O17 "Identifies the current status of auxiliary input/output functions that are configured uniquely per application.";
CM_ SG_ 2561146622 AuxI_O18 "Identifies the current status of auxiliary input/output functions that are configured uniquely per application.";
CM_ SG_ 2561146622 AuxI_O19 "Identifies the current status of auxiliary input/output functions that are configured uniquely per application.";
CM_ SG_ 2561146622 AuxI_O20 "Identifies the current status of auxiliary input/output functions that are configured uniquely per application.";
CM_ SG_ 2561081086 AuxI_O77 "Identifies the current status of auxiliary input/output functions that are configured uniquely per application.";
CM_ SG_ 2561081086 AuxI_O78 "Identifies the current status of auxiliary input/output functions that are configured uniquely per application.";
CM_ SG_ 2561081086 AuxI_O79 "Identifies the current status of auxiliary input/output functions that are configured uniquely per application.";
CM_ SG_ 2561081086 AuxI_O80 "Identifies the current status of auxiliary input/output functions that are configured uniquely per application.";
CM_ SG_ 2561081086 AuxI_O73 "Identifies the current status of auxiliary input/output functions that are configured uniquely per application.";
CM_ SG_ 2561081086 AuxI_O74 "Identifies the current status of auxiliary input/output functions that are configured uniquely per application.";
CM_ SG_ 2561081086 AuxI_O75 "Identifies the current status of auxiliary input/output functions that are configured uniquely per application.";
CM_ SG_ 2561081086 AuxI_O76 "Identifies the current status of auxiliary input/output functions that are configured uniquely per application.";
CM_ SG_ 2561081086 AuxI_O69 "Identifies the current status of auxiliary input/output functions that are configured uniquely per application.";
CM_ SG_ 2561081086 AuxI_O70 "Identifies the current status of auxiliary input/output functions that are configured uniquely per application.";
CM_ SG_ 2561081086 AuxI_O71 "Identifies the current status of auxiliary input/output functions that are configured uniquely per application.";
CM_ SG_ 2561081086 AuxI_O72 "Identifies the current status of auxiliary input/output functions that are configured uniquely per application.";
CM_ SG_ 2561081086 AuxI_O65 "Identifies the current status of auxiliary input/output functions that are configured uniquely per application.";
CM_ SG_ 2561081086 AuxI_O66 "Identifies the current status of auxiliary input/output functions that are configured uniquely per application.";
CM_ SG_ 2561081086 AuxI_O67 "Identifies the current status of auxiliary input/output functions that are configured uniquely per application.";
CM_ SG_ 2561081086 AuxI_O68 "Identifies the current status of auxiliary input/output functions that are configured uniquely per application.";
CM_ SG_ 2561081086 AuxI_O61 "Identifies the current status of auxiliary input/output functions that are configured uniquely per application.";
CM_ SG_ 2561081086 AuxI_O62 "Identifies the current status of auxiliary input/output functions that are configured uniquely per application.";
CM_ SG_ 2561081086 AuxI_O63 "Identifies the current status of auxiliary input/output functions that are configured uniquely per application.";
CM_ SG_ 2561081086 AuxI_O64 "Identifies the current status of auxiliary input/output functions that are configured uniquely per application.";
CM_ SG_ 2561081086 AuxI_O57 "Identifies the current status of auxiliary input/output functions that are configured uniquely per application.";
CM_ SG_ 2561081086 AuxI_O58 "Identifies the current status of auxiliary input/output functions that are configured uniquely per application.";
CM_ SG_ 2561081086 AuxI_O59 "Identifies the current status of auxiliary input/output functions that are configured uniquely per application.";
CM_ SG_ 2561081086 AuxI_O60 "Identifies the current status of auxiliary input/output functions that are configured uniquely per application.";
CM_ SG_ 2561081086 AuxI_O53 "Identifies the current status of auxiliary input/output functions that are configured uniquely per application.";
CM_ SG_ 2561081086 AuxI_O54 "Identifies the current status of auxiliary input/output functions that are configured uniquely per application.";
CM_ SG_ 2561081086 AuxI_O55 "Identifies the current status of auxiliary input/output functions that are configured uniquely per application.";
CM_ SG_ 2561081086 AuxI_O56 "Identifies the current status of auxiliary input/output functions that are configured uniquely per application.";
CM_ SG_ 2561081086 AuxI_O49 "Identifies the current status of auxiliary input/output functions that are configured uniquely per application.";
CM_ SG_ 2561081086 AuxI_O50 "Identifies the current status of auxiliary input/output functions that are configured uniquely per application.";
CM_ SG_ 2561081086 AuxI_O51 "Identifies the current status of auxiliary input/output functions that are configured uniquely per application.";
CM_ SG_ 2561081086 AuxI_O52 "Identifies the current status of auxiliary input/output functions that are configured uniquely per application.";
CM_ SG_ 2561015550 AuxI_O92 "Identifies the current status of auxiliary input/output functions that are configured uniquely per application.";
CM_ SG_ 2561015550 AuxI_O85 "Identifies the current status of auxiliary input/output functions that are configured uniquely per application.";
CM_ SG_ 2561015550 AuxI_O86 "Identifies the current status of auxiliary input/output functions that are configured uniquely per application.";
CM_ SG_ 2561015550 AuxI_O87 "Identifies the current status of auxiliary input/output functions that are configured uniquely per application.";
CM_ SG_ 2561015550 AuxI_O88 "Identifies the current status of auxiliary input/output functions that are configured uniquely per application.";
CM_ SG_ 2561015550 AuxI_O81 "Identifies the current status of auxiliary input/output functions that are configured uniquely per application.";
CM_ SG_ 2561015550 AuxI_O82 "Identifies the current status of auxiliary input/output functions that are configured uniquely per application.";
CM_ SG_ 2561015550 AuxI_O83 "Identifies the current status of auxiliary input/output functions that are configured uniquely per application.";
CM_ SG_ 2561015550 AuxI_O84 "Identifies the current status of auxiliary input/output functions that are configured uniquely per application.";
CM_ SG_ 2561015550 AuxI_O109 "Identifies the current status of auxiliary input/output functions that are configured uniquely per application.";
CM_ SG_ 2561015550 AuxI_O110 "Identifies the current status of auxiliary input/output functions that are configured uniquely per application.";
CM_ SG_ 2561015550 AuxI_O111 "Identifies the current status of auxiliary input/output functions that are configured uniquely per application.";
CM_ SG_ 2561015550 AuxI_O112 "Identifies the current status of auxiliary input/output functions that are configured uniquely per application.";
CM_ SG_ 2561015550 AuxI_O105 "Identifies the current status of auxiliary input/output functions that are configured uniquely per application.";
CM_ SG_ 2561015550 AuxI_O106 "Identifies the current status of auxiliary input/output functions that are configured uniquely per application.";
CM_ SG_ 2561015550 AuxI_O107 "Identifies the current status of auxiliary input/output functions that are configured uniquely per application.";
CM_ SG_ 2561015550 AuxI_O108 "Identifies the current status of auxiliary input/output functions that are configured uniquely per application.";
CM_ SG_ 2561015550 AuxI_O101 "Identifies the current status of auxiliary input/output functions that are configured uniquely per application.";
CM_ SG_ 2561015550 AuxI_O102 "Identifies the current status of auxiliary input/output functions that are configured uniquely per application.";
CM_ SG_ 2561015550 AuxI_O103 "Identifies the current status of auxiliary input/output functions that are configured uniquely per application.";
CM_ SG_ 2561015550 AuxI_O104 "Identifies the current status of auxiliary input/output functions that are configured uniquely per application.";
CM_ SG_ 2561015550 AuxI_O97 "Identifies the current status of auxiliary input/output functions that are configured uniquely per application.";
CM_ SG_ 2561015550 AuxI_O98 "Identifies the current status of auxiliary input/output functions that are configured uniquely per application.";
CM_ SG_ 2561015550 AuxI_O99 "Identifies the current status of auxiliary input/output functions that are configured uniquely per application.";
CM_ SG_ 2561015550 AuxI_O100 "Identifies the current status of auxiliary input/output functions that are configured uniquely per application.";
CM_ SG_ 2561015550 AuxI_O93 "Identifies the current status of auxiliary input/output functions that are configured uniquely per application.";
CM_ SG_ 2561015550 AuxI_O94 "Identifies the current status of auxiliary input/output functions that are configured uniquely per application.";
CM_ SG_ 2561015550 AuxI_O95 "Identifies the current status of auxiliary input/output functions that are configured uniquely per application.";
CM_ SG_ 2561015550 AuxI_O96 "Identifies the current status of auxiliary input/output functions that are configured uniquely per application.";
CM_ SG_ 2561015550 AuxI_O89 "Identifies the current status of auxiliary input/output functions that are configured uniquely per application.";
CM_ SG_ 2561015550 AuxI_O90 "Identifies the current status of auxiliary input/output functions that are configured uniquely per application.";
CM_ SG_ 2561015550 AuxI_O91 "Identifies the current status of auxiliary input/output functions that are configured uniquely per application.";
CM_ SG_ 2566746622 TrailerBrakeStrokeAxle5Right "Brake stroke status for right brake actuator on trailer axle 5.";
CM_ SG_ 2566746622 TrailerBrakeStrokeAxle5Left "Brake stroke status for left brake actuator on trailer axle 5.";
CM_ SG_ 2566746622 TrailerBrakeStrokeAxle4Right "Brake stroke status for right brake actuator on trailer axle 4.";
CM_ SG_ 2566746622 TrailerBrakeStrokeAxle4Left "Brake stroke status for left brake actuator on trailer axle 4.";
CM_ SG_ 2566746622 TrailerBrakeStrokeAxle3Right "Brake stroke status for right brake actuator on trailer axle 3.";
CM_ SG_ 2566746622 TrailerBrakeStrokeAxle3Left "Brake stroke status for left brake actuator on trailer axle 3.";
CM_ SG_ 2566746622 TrailerBrakeStrokeAxle2Right "Brake stroke status for right brake actuator on trailer axle 2.";
CM_ SG_ 2566746622 TrailerBrakeStrokeAxle2Left "Brake stroke status for left brake actuator on trailer axle 2.";
CM_ SG_ 2566746622 TrailerBrakeStrokeAxle1Right "Brake stroke status for right brake actuator on trailer axle 1.";
CM_ SG_ 2566746622 TrailerBrakeStrokeAxle1Left "Brake stroke status for left brake actuator on trailerr axle 1.";
CM_ SG_ 2566746622 TractorBrakeStrokeAxle5Right "Brake stroke status for right brake actuator on tractor axle 5.";
CM_ SG_ 2566746622 TractorBrakeStrokeAxle5Left "Brake stroke status for left brake actuator on tractor axle 5.";
CM_ SG_ 2566746622 TractorBrakeStrokeAxle4Right "Brake stroke status for right brake actuator on tractor axle 4.";
CM_ SG_ 2566746622 TractorBrakeStrokeAxle4Left "Brake stroke status for left brake actuator on tractor axle 4.";
CM_ SG_ 2566746622 TractorBrakeStrokeAxle3Right "Brake stroke status for right brake actuator on tractor axle 3.";
CM_ SG_ 2566746622 TractorBrakeStrokeAxle3Left "Brake stroke status for left brake actuator on tractor axle 3.";
CM_ SG_ 2566746622 TractorBrakeStrokeAxle2Right "Brake stroke status for right brake actuator on tractor axle 2.";
CM_ SG_ 2566746622 TractorBrakeStrokeAxle2Left "Brake stroke status for left brake actuator on tractor axle 2.";
CM_ SG_ 2566746622 TractorBrakeStrokeAxle1Right "Brake stroke status for right brake actuator on tractor axle 1.";
CM_ SG_ 2566746622 TractorBrakeStrokeAxle1Left "Brake stroke status for left brake actuator on tractor axle 1.";
CM_ SG_ 2566845950 EngAirIntakeTemp "Temperature of air entering vehicle air induction system.";
CM_ SG_ 2566845950 RoadSurfaceTemp "Indicated temperature of road surface over which vehicle is operating.";
CM_ SG_ 2566845950 AmbientAirTemp "Temperature of air surrounding vehicle.";
CM_ SG_ 2566845950 CabInteriorTemp "Temperature of air inside the part of the vehicle that encloses the driver and vehicle operating controls.";
CM_ SG_ 2566845950 BarometricPress "Absolute air pressure of the atmosphere.";
CM_ SG_ 2566840062 EngAirStartPress "Gage pressure of air in an engine starting system that utilizes compressed air to provide the force required to rotate the";
CM_ SG_ 2566827774 ServiceBrakeCircuit2AirPress "The pneumatic pressure in the secondary service brake circuit or reservoir, supplying the front axle.";
CM_ SG_ 2566827774 ServiceBrakeCircuit1AirPress "The pneumatic pressure in the primary service brake circuit or reservoir, supplying the rear axle.";
CM_ SG_ 2566827774 AirCompressorStatus "Indicates whether the air compressor is actively compressing air.";
CM_ SG_ 2566827774 AirSuspensionSupplyPress "The pneumatic pressure in the circuit for the electronically controlled air suspension system.";
CM_ SG_ 2566827774 AuxEquipmentSupplyPress "The pneumatic pressure in the auxiliary circuit.";
CM_ SG_ 2566827774 ParkingAnd_OrTrailerAirPress "The pneumatic pressure in the circuit or reservoir for the parking brake and/or the trailer supply.";
CM_ SG_ 2566827774 PneumaticSupplyPress "The pneumatic pressure in the main reservoir, sometimes referred to as the wet tank.";
CM_ SG_ 2566846974 SteerAxleLubePress "The steering axle lubricant pressure.";
CM_ SG_ 2566846974 SteerAxleTemp "Temperature of lubricant in steering axle.";
CM_ SG_ 2566846974 DriveAxleLubePress "The drive axle lubricant pressure with location determined by Drive Axle Location (SPN 930).";
CM_ SG_ 2566846974 DriveAxleTemp "Temperature of axle lubricant in drive axle.";
CM_ SG_ 2566846974 DriveAxleLiftAirPress "Gage pressure of air in system that utilizes compressed air to provide force between axle and frame.";
CM_ SG_ 2566846974 DriveAxleLocation "To identify to which of several similar devices (such as tires or fuel tanks) the information applies.";
CM_ SG_ 2633935614 EngTurboWastegateValvePos "The position of the turbocharger wastegate valve (not the electronic wastegate control valve).";
CM_ SG_ 2633935614 EngGsMssFlwSnsrFelingCorrection "The amount of fuel the Gas Mass Flow Sensor is sensing should be added or subtracted compared to the maximum";
CM_ SG_ 2633935614 EngDsiredAbsIntakeManifoldPress "The desired absolute intake manifold pressure of the engine.";
CM_ SG_ 2633935614 EngGasFuelCorrectionFactor "A correction to a predefined gaseous fuel energy (expressed in energy per unit volume) represented as a percentage.";
CM_ SG_ 2566803966 ACCUsageDemand "This parameter indicates the drivers demand to activate or deactivate ACC keeping distance control.";
CM_ SG_ 2566803966 RqedACCDistanceMode "The Requested Distance Control Mode to the ACC system from the operators interface.";
CM_ SG_ 2432593918 ForwardCollisionWarning "This parameter indicates if a collision is imminent and strong driver reaction either by braking hard or by an avoidance";
CM_ SG_ 2432593918 ACCDistanceAlertSignal "Signal to indicate to the operator that the ACC system is not able to maintain the distance to the target.";
CM_ SG_ 2432593918 ACCSystemShutoffWarning "Signal to warn the driver of system deactivation due to non-driver actions.";
CM_ SG_ 2432593918 ACCTargetDetected "Signal to indicate to the driver that the ACC system has detected a target.";
CM_ SG_ 2432593918 RoadCurvature "Estimated value of the current road curvature for use by the adaptive cruise control system.";
CM_ SG_ 2432593918 AdptveCruiseCtrlSetDistanceMode "Selected distance mode for adaptive cruise control.";
CM_ SG_ 2432593918 AdaptiveCruiseCtrlMode "This parameter is used to indicate the current state, or mode, of operation by the Adaptive Cruise Control (ACC) device.";
CM_ SG_ 2432593918 AdaptiveCruiseCtrlSetSpeed "Value of the desired (chosen) velocity of the adaptive cruise control system.";
CM_ SG_ 2432593918 DistanceToForwardVehicle "Distance to the preceding vehicle situated within 250 m in the same lane and moving in the same direction.";
CM_ SG_ 2432593918 SpeedOfForwardVehicle "Absolute velocity of the preceding vehicle situated within 250 m in the same lane and moving in the same direction.";
CM_ SG_ 2633935102 ArticulationAngle "Angle of deflection of an articulated transit vehicle.";
CM_ SG_ 2633927934 RelativeHumidity "Measures humidity of combustion air prior to entry into turbocharger";
CM_ SG_ 2633927934 AuxLevel "Level measured by a sensor.";
CM_ SG_ 2633927934 AuxPress2 "Pressure measured by auxiliary pressure sensor #2.";
CM_ SG_ 2633927934 AuxPress1 "Pressure measured by auxiliary pressure sensor #1.";
CM_ SG_ 2633927934 AuxTemp2 "Temperature measured by auxiliary temperature sensor #2.";
CM_ SG_ 2633927934 AuxTemp1 "Temperature measured by auxiliary temperature sensor #1.";
CM_ SG_ 2566847998 EngBlowerBypassValvePos "Relative position of the blower bypass valve.";
CM_ SG_ 2566847998 EngGasSupplyPress "Gage pressure of gas supply to fuel metering device.";
CM_ SG_ 2566803198 Status2OfDoors "Composite indication of all bus door statuses.";
CM_ SG_ 2566803198 Ramp_WheelChairLiftPos "Signal which indicates the actual position of the ramp / wheel chair lift.";
CM_ SG_ 2566803198 PosOfDoors "Signal which indicates the actual position of the doors.";
CM_ SG_ 2565870334 FifthWheelRollWarningIndicator "Indicates to the vehicle operator that the roll moment has exceeded a preset limit.";
CM_ SG_ 2565870334 FifthWheelRollMoment "Fifth wheel roll moment force - If the moment is positive, the trailer is rolling clockwise relative to the normal vehicle";
CM_ SG_ 2565870334 FifthWheelDrawbarForce "Fifth wheel drawbar force, with the trailer held stationary a positive force is generated by the vehicle pulling forward.";
CM_ SG_ 2565870334 FifthWheelVerticalForce "The amount of load being applied to the fifth wheel by the trailer.";
CM_ SG_ 2566762238 FifthWheelSliderLockIndicator "Indicates to vehicle operator that the fifth wheel slider is in position and locked.";
CM_ SG_ 2566762238 FifthWheelSliderPos "Slider position measurement.";
CM_ SG_ 2566762238 FfthWhlLckCoupleStatusIndicator "Indicates results of coupling operation to the vehicle operator.";
CM_ SG_ 2566762238 FfthWhlLckRadyToCoupleIndicator "Indicates to the vehicle operator that the fifth wheel lock is open and ready to couple.";
CM_ SG_ 2566762238 FifthWheelErrorStatus "Fifth wheel error state which conveys information when coupling status is incomplete or bad.";
CM_ SG_ 2364543998 RollAndPitchMeasurementLatency "The estimated measurement latency of the measurement.";
CM_ SG_ 2364543998 PitchAndRollCompensated "Compensated mode for the pitch and roll measurements.";
CM_ SG_ 2364543998 PitchRateFigureOfMerit "Figure of merit for the pitch rate measurement.";
CM_ SG_ 2364543998 RollAngleFigureOfMerit "Figure of merit for roll angle measurement.";
CM_ SG_ 2364543998 PitchAngleFigureOfMerit "Figure of merit for pitch angle measurement.";
CM_ SG_ 2364543998 PitchRate "Pitch rate is the rate-of-change of the pitch angle over time, where the pitch angle vector is in the direction of travel of the";
CM_ SG_ 2364543998 RollAngle "The angle between the vehicle y-axis and the ground plane.";
CM_ SG_ 2364543998 PitchAngle "The angle between the vehicle x-axis and the ground plane.";
CM_ SG_ 2566846718 TransOilLevelMeasurementStatus "Indicates if conditions are acceptable to obtain a valid transmission oil level measurement as conveyed in SPN 124";
CM_ SG_ 2566846718 TransOilLevelCountdownTimer "Once all vehicle conditions (such as vehicle stopped, etc) are met, some transmissions may require a `settling time' to";
CM_ SG_ 2566846718 TransOilLevelHigh_Low "Amount of current volume of transmission sump oil compared to recommended volume.";
CM_ SG_ 2566846718 TransOilTemp "Temperature of the transmission lubricant.";
CM_ SG_ 2566846718 TransOilPress "Gage pressure of lubrication fluid in transmission, measured after pump.";
CM_ SG_ 2566846718 TransFilterDiffPress "Change in transmission fluid pressure, measured after the filter, due to accumulation of solid or semisolid material on or in";
CM_ SG_ 2566846718 TransOilLevel "Ratio of volume of transmission sump oil to recommended volume.";
CM_ SG_ 2566846718 ClutchPress "Gage pressure of oil within a wet clutch.";
CM_ SG_ 2566846462 ChargingSystemPotential "Electrical potential measured at the charging system output.";
CM_ SG_ 2566846462 AltCurrent "Measure of electrical current flow from the alternator.";
CM_ SG_ 2566846462 NetBatteryCurrent "Net flow of electrical current into/out of the battery or batteries.";
CM_ SG_ 2566846462 KeyswitchBatteryPotential "Battery potential measured at the input of the electronic control unit supplied through a keyswitch or similar switching";
CM_ SG_ 2566846462 BatteryPotential_PowerInput1 "This parameter measures the first source of battery potential as measured at the input of the ECM/actuator etc.";
CM_ SG_ 2566760702 WrlessCommunicationNetworkType2 "Type of Wireless Communication Network";
CM_ SG_ 2566760702 NetworkSignalStrength2 "Indicates the signal strength for the wireless communications network type.";
CM_ SG_ 2566760702 NetworkAntennaStatus2 "Indicates the status of the antenna for the wireless communications network type";
CM_ SG_ 2566760702 NetworkServiceStatus2 "Indicates the status of the Service for the wireless communications network type";
CM_ SG_ 2566760702 NetworkTransceiverStatus2 "Indicates the status of the transceiver for the wireless communications network type";
CM_ SG_ 2566760958 WrlessCommunicationNetworkType1 "Type of Wireless Communication Network";
CM_ SG_ 2566760958 NetworkSignalStrength1 "Indicates the signal strength for the wireless communications network type.";
CM_ SG_ 2566760958 NetworkAntennaStatus1 "Indicates the status of the antenna for the wireless communications network type";
CM_ SG_ 2566760958 NetworkServiceStatus1 "Indicates the status of the Service for the wireless communications network type";
CM_ SG_ 2566760958 NetworkTransceiverStatus1 "Indicates the status of the transceiver for the wireless communications network type";

BA_DEF_ BO_ "GenMsgCycleTime" INT 0 3600000;
BA_DEF_ BO_ "GenMsgSendType" ENUM  "cyclic","reserved","cyclicIfActive","reserved","reserved","reserved","reserved","reserved","noMsgSendType";
BA_DEF_ BO_ "GenMsgStartDelayTime" INT 0 100000;
BA_DEF_ BO_ "VFrameFormat" ENUM  "StandardCAN","ExtendedCAN","reserved","J1939PG";
BA_DEF_ SG_ "GenSigStartValue" INT 0 10000;
BA_DEF_ SG_ "SPN" INT 0 524287;
BA_DEF_ SG_ "SigType" ENUM  "Default","Range","RangeSigned","ASCII","Discrete","Control","ReferencePGN","DTC","StringDelimiter","StringLength","StringLengthControl";
BA_DEF_ SG_ "SystemSignalLongSymbol" STRING;
BA_DEF_DEF_ "GenMsgCycleTime" 0;
BA_DEF_DEF_ "GenMsgSendType" "noMsgSendType";
BA_DEF_DEF_ "GenMsgStartDelayTime" 0;
BA_DEF_DEF_ "GenSigStartValue" 0;
BA_DEF_DEF_ "SPN" 0;
BA_DEF_DEF_ "SigType" "Default";
BA_DEF_DEF_ "VFrameFormat" "J1939PG";
BA_ "GenMsgCycleTime" BO_ 2566745342 500;
BA_ "GenMsgSendType" BO_ 2566745342 0;
BA_ "GenMsgCycleTime" BO_ 2566758654 500;
BA_ "GenMsgSendType" BO_ 2566758654 0;
BA_ "GenMsgCycleTime" BO_ 2566753278 500;
BA_ "GenMsgSendType" BO_ 2566753278 0;
BA_ "GenMsgCycleTime" BO_ 2565869822 50;
BA_ "GenMsgSendType" BO_ 2565869822 0;
BA_ "GenMsgCycleTime" BO_ 2566763006 500;
BA_ "GenMsgSendType" BO_ 2566763006 0;
BA_ "GenMsgCycleTime" BO_ 2566762494 500;
BA_ "GenMsgSendType" BO_ 2566762494 0;
BA_ "GenMsgCycleTime" BO_ 2565870078 50;
BA_ "GenMsgSendType" BO_ 2565870078 0;
BA_ "GenMsgCycleTime" BO_ 2566762750 500;
BA_ "GenMsgSendType" BO_ 2566762750 0;
BA_ "GenMsgCycleTime" BO_ 2365428478 250;
BA_ "GenMsgCycleTime" BO_ 2566743806 1000;
BA_ "GenMsgSendType" BO_ 2566743806 0;
BA_ "GenMsgCycleTime" BO_ 2550660862 100;
BA_ "GenMsgCycleTime" BO_ 2566805758 100;
BA_ "GenMsgSendType" BO_ 2566805758 0;
BA_ "GenMsgCycleTime" BO_ 2566806014 100;
BA_ "GenMsgSendType" BO_ 2566806014 0;
BA_ "GenMsgCycleTime" BO_ 2362638078 100;
BA_ "GenMsgSendType" BO_ 2362638078 0;
BA_ "GenMsgCycleTime" BO_ 2365479678 100;
BA_ "GenMsgSendType" BO_ 2365479678 0;
BA_ "GenMsgCycleTime" BO_ 2566837758 1000;
BA_ "GenMsgSendType" BO_ 2566837758 0;
BA_ "GenMsgCycleTime" BO_ 2566775038 1000;
BA_ "GenMsgSendType" BO_ 2566775038 0;
BA_ "GenMsgCycleTime" BO_ 2432520702 1000;
BA_ "GenMsgSendType" BO_ 2432520702 0;
BA_ "GenMsgCycleTime" BO_ 2499630078 500;
BA_ "GenMsgSendType" BO_ 2499630078 0;
BA_ "GenMsgCycleTime" BO_ 2566746622 1000;
BA_ "GenMsgSendType" BO_ 2566746622 0;
BA_ "GenMsgCycleTime" BO_ 2566845950 1000;
BA_ "GenMsgSendType" BO_ 2566845950 0;
BA_ "GenMsgCycleTime" BO_ 2566827774 1000;
BA_ "GenMsgSendType" BO_ 2566827774 0;
BA_ "GenMsgCycleTime" BO_ 2566846974 1000;
BA_ "GenMsgSendType" BO_ 2566846974 0;
BA_ "GenMsgCycleTime" BO_ 2566803966 250;
BA_ "GenMsgSendType" BO_ 2566803966 0;
BA_ "GenMsgCycleTime" BO_ 2432593918 100;
BA_ "GenMsgSendType" BO_ 2432593918 0;
BA_ "GenMsgCycleTime" BO_ 2566847998 500;
BA_ "GenMsgSendType" BO_ 2566847998 0;
BA_ "GenMsgCycleTime" BO_ 2566803198 100;
BA_ "GenMsgSendType" BO_ 2566803198 0;
BA_ "GenMsgCycleTime" BO_ 2565870334 50;
BA_ "GenMsgSendType" BO_ 2565870334 0;
BA_ "GenMsgCycleTime" BO_ 2364543998 10;
BA_ "GenMsgSendType" BO_ 2364543998 0;
BA_ "GenMsgCycleTime" BO_ 2566846718 1000;
BA_ "GenMsgSendType" BO_ 2566846718 0;
BA_ "GenMsgCycleTime" BO_ 2566846462 1000;
BA_ "GenMsgSendType" BO_ 2566846462 0;
BA_ "SPN" SG_ 2566745342 Aftertreatment2SecondAirPress 3838;
BA_ "SigType" SG_ 2566745342 Aftertreatment2SecondAirPress 1;
BA_ "SPN" SG_ 2566745342 Aftrtreatment2SecondAirMassFlow 3835;
BA_ "SigType" SG_ 2566745342 Aftrtreatment2SecondAirMassFlow 1;
BA_ "SPN" SG_ 2566745342 Aftertreatment2SecondAirTemp 3834;
BA_ "SigType" SG_ 2566745342 Aftertreatment2SecondAirTemp 1;
BA_ "SPN" SG_ 2566745342 Aftrtratment2SecondAirDiffPress 3833;
BA_ "SigType" SG_ 2566745342 Aftrtratment2SecondAirDiffPress 1;
BA_ "SPN" SG_ 2566758654 Aftrtrtmnt2FlInjctor1HeaterCtrl 4302;
BA_ "SigType" SG_ 2566758654 Aftrtrtmnt2FlInjctor1HeaterCtrl 1;
BA_ "SPN" SG_ 2566758654 Aftertreatment2FuelPress1Ctrl 3493;
BA_ "SigType" SG_ 2566758654 Aftertreatment2FuelPress1Ctrl 1;
BA_ "SPN" SG_ 2566758654 Aftertreatment2FuelPress1 3494;
BA_ "SigType" SG_ 2566758654 Aftertreatment2FuelPress1 1;
BA_ "SPN" SG_ 2566758654 Aftrtratment2FuelEnableActuator 3496;
BA_ "SigType" SG_ 2566758654 Aftrtratment2FuelEnableActuator 4;
BA_ "SPN" SG_ 2566758654 Aftrtratment2RegenerationStatus 3497;
BA_ "SigType" SG_ 2566758654 Aftrtratment2RegenerationStatus 4;
BA_ "SPN" SG_ 2566758654 Aftertreatment2Ignt 3498;
BA_ "SigType" SG_ 2566758654 Aftertreatment2Ignt 4;
BA_ "SPN" SG_ 2566758654 Aftrtreatment2FuelDrainActuator 4098;
BA_ "SigType" SG_ 2566758654 Aftrtreatment2FuelDrainActuator 4;
BA_ "SPN" SG_ 2566758654 Aftertreatment2FuelRate 3495;
BA_ "SigType" SG_ 2566758654 Aftertreatment2FuelRate 1;
BA_ "SPN" SG_ 2566753278 DslPrticulateFilterOutletPress2 3612;
BA_ "SigType" SG_ 2566753278 DslPrticulateFilterOutletPress2 1;
BA_ "SPN" SG_ 2566753278 DslPrticulateFilterIntakePress2 3611;
BA_ "SigType" SG_ 2566753278 DslPrticulateFilterIntakePress2 1;
BA_ "SPN" SG_ 2566756862 Aftrtrtmnt2TtlNmbrOfActvRgnrtnMn 3732;
BA_ "SigType" SG_ 2566756862 Aftrtrtmnt2TtlNmbrOfActvRgnrtnMn 1;
BA_ "SystemSignalLongSymbol" SG_ 2566756862 Aftrtrtmnt2TtlNmbrOfActvRgnrtnMn "Aftrtrtmnt2TtlNmbrOfActvRgnrtnMnlRqs";
BA_ "SPN" SG_ 2566756862 Aftrtrtmnt2TtlNmbrOfActvRgnrtnIn 3731;
BA_ "SigType" SG_ 2566756862 Aftrtrtmnt2TtlNmbrOfActvRgnrtnIn 1;
BA_ "SystemSignalLongSymbol" SG_ 2566756862 Aftrtrtmnt2TtlNmbrOfActvRgnrtnIn "Aftrtrtmnt2TtlNmbrOfActvRgnrtnInhbtRqs";
BA_ "SPN" SG_ 2566756862 Aftrtrtmnt2AvrgTmBtwnActvRgnrtns 5455;
BA_ "SigType" SG_ 2566756862 Aftrtrtmnt2AvrgTmBtwnActvRgnrtns 1;
BA_ "SPN" SG_ 2566756862 Aftrtrtmnt2TtlNmbrOfPssvRgnrtns 3730;
BA_ "SigType" SG_ 2566756862 Aftrtrtmnt2TtlNmbrOfPssvRgnrtns 1;
BA_ "SPN" SG_ 2566756862 Aftrtrtmnt2TtlPssvRgnrationTime 3729;
BA_ "SigType" SG_ 2566756862 Aftrtrtmnt2TtlPssvRgnrationTime 1;
BA_ "SPN" SG_ 2566756862 Aftrtrtmnt2TtlNmbrOfActvRgnrtns 3529;
BA_ "SigType" SG_ 2566756862 Aftrtrtmnt2TtlNmbrOfActvRgnrtns 1;
BA_ "SPN" SG_ 2566756862 Aftrtreatment2TotalDisabledTime 3528;
BA_ "SigType" SG_ 2566756862 Aftrtreatment2TotalDisabledTime 1;
BA_ "SPN" SG_ 2566756862 Aftrtrtmnt2TtalRegenerationTime 3527;
BA_ "SigType" SG_ 2566756862 Aftrtrtmnt2TtalRegenerationTime 1;
BA_ "SPN" SG_ 2566756862 Aftertreatment2TotalFuelUsed 3526;
BA_ "SigType" SG_ 2566756862 Aftertreatment2TotalFuelUsed 1;
BA_ "SPN" SG_ 2565869822 Aftrtrtmnt2IntkOxygnSnsrPrlmnryF 3264;
BA_ "SigType" SG_ 2565869822 Aftrtrtmnt2IntkOxygnSnsrPrlmnryF 1;
BA_ "SystemSignalLongSymbol" SG_ 2565869822 Aftrtrtmnt2IntkOxygnSnsrPrlmnryF "Aftrtrtmnt2IntkOxygnSnsrPrlmnryFMI";
BA_ "SPN" SG_ 2565869822 Aftrtrtmnt2IntkGsSnsrPwerStatus 3257;
BA_ "SigType" SG_ 2565869822 Aftrtrtmnt2IntkGsSnsrPwerStatus 4;
BA_ "SPN" SG_ 2565869822 Aftrtrtmnt2IntkGsSnsrHtrPrlmnryF 3261;
BA_ "SigType" SG_ 2565869822 Aftrtrtmnt2IntkGsSnsrHtrPrlmnryF 1;
BA_ "SystemSignalLongSymbol" SG_ 2565869822 Aftrtrtmnt2IntkGsSnsrHtrPrlmnryF "Aftrtrtmnt2IntkGsSnsrHtrPrlmnryFMI";
BA_ "SPN" SG_ 2565869822 Aftrtrtmnt2IntkNOxSnsrPrlmnryFMI 3263;
BA_ "SPN" SG_ 2565869822 Aftrtrtmnt2IntkGsSnsrHeaterCtrl 3262;
BA_ "SigType" SG_ 2565869822 Aftrtrtmnt2IntkGsSnsrHeaterCtrl 4;
BA_ "SPN" SG_ 2565869822 Aftrtrtmnt2IntkWdRngO2RdngStble 3260;
BA_ "SigType" SG_ 2565869822 Aftrtrtmnt2IntkWdRngO2RdngStble 4;
BA_ "SPN" SG_ 2565869822 Aftrtrtmnt2IntkNOxReadingStable 3259;
BA_ "SigType" SG_ 2565869822 Aftrtrtmnt2IntkNOxReadingStable 4;
BA_ "SPN" SG_ 2565869822 Aftrtrtmnt2IntkeGasSensorAtTemp 3258;
BA_ "SigType" SG_ 2565869822 Aftrtrtmnt2IntkeGasSensorAtTemp 4;
BA_ "SPN" SG_ 2565869822 Aftertreatment2IntakeO2 3256;
BA_ "SigType" SG_ 2565869822 Aftertreatment2IntakeO2 1;
BA_ "SPN" SG_ 2565869822 Aftertreatment2IntakeNOx 3255;
BA_ "SigType" SG_ 2565869822 Aftertreatment2IntakeNOx 1;
BA_ "SPN" SG_ 2566763006 Aftrtrtmnt2DslPrtcltFltrIntkGsTm0 3278;
BA_ "SigType" SG_ 2566763006 Aftrtrtmnt2DslPrtcltFltrIntkGsTm0 1;
BA_ "SystemSignalLongSymbol" SG_ 2566763006 Aftrtrtmnt2DslPrtcltFltrIntkGsTm0 "Aftrtrtmnt2DslPrtcltFltrIntkGsTmpPrlmnryFMI";
BA_ "SPN" SG_ 2566763006 Aftrtrtmnt2ExhstGsTmp1PrlmnryFMI 3277;
BA_ "SPN" SG_ 2566763006 Aftertreatment2ExhaustGasTemp1 3275;
BA_ "SigType" SG_ 2566763006 Aftertreatment2ExhaustGasTemp1 1;
BA_ "SPN" SG_ 2566763006 Aftrtrtmnt2DslPrtcltFltrIntkGsTm1 3276;
BA_ "SigType" SG_ 2566763006 Aftrtrtmnt2DslPrtcltFltrIntkGsTm1 1;
BA_ "SystemSignalLongSymbol" SG_ 2566763006 Aftrtrtmnt2DslPrtcltFltrIntkGsTm1 "Aftrtrtmnt2DslPrtcltFltrIntkGsTmp";
BA_ "SPN" SG_ 2566762494 Aftrtrtmnt2DslPrtcltFltrIntrmdtG0 3288;
BA_ "SigType" SG_ 2566762494 Aftrtrtmnt2DslPrtcltFltrIntrmdtG0 1;
BA_ "SystemSignalLongSymbol" SG_ 2566762494 Aftrtrtmnt2DslPrtcltFltrIntrmdtG0 "Aftrtrtmnt2DslPrtcltFltrIntrmdtGsTmpPrlmnryFMI";
BA_ "SPN" SG_ 2566762494 Aftrtrtmnt2DslPrtcltFltrIntrmdtG1 3284;
BA_ "SigType" SG_ 2566762494 Aftrtrtmnt2DslPrtcltFltrIntrmdtG1 1;
BA_ "SystemSignalLongSymbol" SG_ 2566762494 Aftrtrtmnt2DslPrtcltFltrIntrmdtG1 "Aftrtrtmnt2DslPrtcltFltrIntrmdtGsTmp";
BA_ "SPN" SG_ 2566762494 Aftrtrtmnt2DslPrtcltFltrDltPrssP 3287;
BA_ "SigType" SG_ 2566762494 Aftrtrtmnt2DslPrtcltFltrDltPrssP 1;
BA_ "SystemSignalLongSymbol" SG_ 2566762494 Aftrtrtmnt2DslPrtcltFltrDltPrssP "Aftrtrtmnt2DslPrtcltFltrDltPrssPrlmnryFMI";
BA_ "SPN" SG_ 2566762494 Aftrtrtmnt2DslPrtcltFltrDffPrss 3285;
BA_ "SigType" SG_ 2566762494 Aftrtrtmnt2DslPrtcltFltrDffPrss 1;
BA_ "SPN" SG_ 2566762494 Aftrtrtmnt2ExhstGsTmp2PrlmnryFMI 3286;
BA_ "SPN" SG_ 2566762494 Aftertreatment2ExhaustGasTemp2 3283;
BA_ "SigType" SG_ 2566762494 Aftertreatment2ExhaustGasTemp2 1;
BA_ "SPN" SG_ 2565870078 Aftrtrtmnt2OtltOxygnSnsrPrlmnryF 3274;
BA_ "SigType" SG_ 2565870078 Aftrtrtmnt2OtltOxygnSnsrPrlmnryF 1;
BA_ "SystemSignalLongSymbol" SG_ 2565870078 Aftrtrtmnt2OtltOxygnSnsrPrlmnryF "Aftrtrtmnt2OtltOxygnSnsrPrlmnryFMI";
BA_ "SPN" SG_ 2565870078 Aftrtrtmnt2OtltGsSnsrPwerStatus 3267;
BA_ "SigType" SG_ 2565870078 Aftrtrtmnt2OtltGsSnsrPwerStatus 4;
BA_ "SPN" SG_ 2565870078 Aftrtrtmnt2OtltGsSnsrHtrPrlmnryF 3271;
BA_ "SigType" SG_ 2565870078 Aftrtrtmnt2OtltGsSnsrHtrPrlmnryF 1;
BA_ "SystemSignalLongSymbol" SG_ 2565870078 Aftrtrtmnt2OtltGsSnsrHtrPrlmnryF "Aftrtrtmnt2OtltGsSnsrHtrPrlmnryFMI";
BA_ "SPN" SG_ 2565870078 Aftrtrtmnt2OtltNOxSnsrPrlmnryFMI 3273;
BA_ "SPN" SG_ 2565870078 Aftrtrtmnt2OtltGsSnsrHeaterCtrl 3272;
BA_ "SigType" SG_ 2565870078 Aftrtrtmnt2OtltGsSnsrHeaterCtrl 4;
BA_ "SPN" SG_ 2565870078 Aftrtrtmnt2OtltWdRngO2RdngStble 3270;
BA_ "SigType" SG_ 2565870078 Aftrtrtmnt2OtltWdRngO2RdngStble 4;
BA_ "SPN" SG_ 2565870078 Aftrtrtmnt2OtltNOxReadingStable 3269;
BA_ "SigType" SG_ 2565870078 Aftrtrtmnt2OtltNOxReadingStable 4;
BA_ "SPN" SG_ 2565870078 Aftrtrtmnt2OtletGasSensorAtTemp 3268;
BA_ "SigType" SG_ 2565870078 Aftrtrtmnt2OtletGasSensorAtTemp 4;
BA_ "SPN" SG_ 2565870078 Aftertreatment2OutletO2 3266;
BA_ "SigType" SG_ 2565870078 Aftertreatment2OutletO2 1;
BA_ "SPN" SG_ 2565870078 Aftertreatment2OutletNOx 3265;
BA_ "SigType" SG_ 2565870078 Aftertreatment2OutletNOx 1;
BA_ "SPN" SG_ 2566762750 Aftrtrtmnt2DslPrtcltFltrOtltGsTm 3280;
BA_ "SigType" SG_ 2566762750 Aftrtrtmnt2DslPrtcltFltrOtltGsTm 1;
BA_ "SystemSignalLongSymbol" SG_ 2566762750 Aftrtrtmnt2DslPrtcltFltrOtltGsTm "Aftrtrtmnt2DslPrtcltFltrOtltGsTmp";
BA_ "SPN" SG_ 2566762750 Aftrtrtmnt2DslPrtcltFltrExhstGsT 3282;
BA_ "SigType" SG_ 2566762750 Aftrtrtmnt2DslPrtcltFltrExhstGsT 1;
BA_ "SystemSignalLongSymbol" SG_ 2566762750 Aftrtrtmnt2DslPrtcltFltrExhstGsT "Aftrtrtmnt2DslPrtcltFltrExhstGsTmpPrlmnryFMI";
BA_ "SPN" SG_ 2566762750 Aftrtrtmnt2ExhstGsTmp3PrlmnryFMI 3281;
BA_ "SPN" SG_ 2566762750 Aftertreatment2ExhaustGasTemp3 3279;
BA_ "SigType" SG_ 2566762750 Aftertreatment2ExhaustGasTemp3 1;
BA_ "SPN" SG_ 2566748926 DslPrtclteFilter2AshLoadPercent 3723;
BA_ "SigType" SG_ 2566748926 DslPrtclteFilter2AshLoadPercent 1;
BA_ "SPN" SG_ 2566748926 DslPrtcltFltr2TmSncLstActvRgnrtn 3724;
BA_ "SigType" SG_ 2566748926 DslPrtcltFltr2TmSncLstActvRgnrtn 1;
BA_ "SPN" SG_ 2566748926 DslPrtcltFilter2SootLoadPercent 3722;
BA_ "SigType" SG_ 2566748926 DslPrtcltFilter2SootLoadPercent 1;
BA_ "SPN" SG_ 2566748926 Aftrtrtmnt2DslPrtcltFltrStLdRgnr 5467;
BA_ "SigType" SG_ 2566748926 Aftrtrtmnt2DslPrtcltFltrStLdRgnr 1;
BA_ "SystemSignalLongSymbol" SG_ 2566748926 Aftrtrtmnt2DslPrtcltFltrStLdRgnr "Aftrtrtmnt2DslPrtcltFltrStLdRgnrtnThrshld";
BA_ "SPN" SG_ 2566748414 Aftrtrtmnt2TrpNmbrOfActvRgnrtnMn 3748;
BA_ "SigType" SG_ 2566748414 Aftrtrtmnt2TrpNmbrOfActvRgnrtnMn 1;
BA_ "SystemSignalLongSymbol" SG_ 2566748414 Aftrtrtmnt2TrpNmbrOfActvRgnrtnMn "Aftrtrtmnt2TrpNmbrOfActvRgnrtnMnlRqs";
BA_ "SPN" SG_ 2566748414 Aftrtrtmnt2TrpNmbrOfActvRgnrtnIn 3747;
BA_ "SigType" SG_ 2566748414 Aftrtrtmnt2TrpNmbrOfActvRgnrtnIn 1;
BA_ "SystemSignalLongSymbol" SG_ 2566748414 Aftrtrtmnt2TrpNmbrOfActvRgnrtnIn "Aftrtrtmnt2TrpNmbrOfActvRgnrtnInhbtRqs";
BA_ "SPN" SG_ 2566748414 Aftrtrtmnt2TrpNmbrOfPssvRgnrtns 3746;
BA_ "SigType" SG_ 2566748414 Aftrtrtmnt2TrpNmbrOfPssvRgnrtns 1;
BA_ "SPN" SG_ 2566748414 Aftrtrtmnt2TrpPssvRgnrationTime 3745;
BA_ "SigType" SG_ 2566748414 Aftrtrtmnt2TrpPssvRgnrationTime 1;
BA_ "SPN" SG_ 2566748414 Aftrtrtmnt2TrpNmbrOfActvRgnrtns 3744;
BA_ "SigType" SG_ 2566748414 Aftrtrtmnt2TrpNmbrOfActvRgnrtns 1;
BA_ "SPN" SG_ 2566748414 Aftertreatment2TripDisabledTime 3743;
BA_ "SigType" SG_ 2566748414 Aftertreatment2TripDisabledTime 1;
BA_ "SPN" SG_ 2566748414 Aftrtrtmnt2TrpActvRgnrationTime 3742;
BA_ "SigType" SG_ 2566748414 Aftrtrtmnt2TrpActvRgnrationTime 1;
BA_ "SPN" SG_ 2566748414 Aftertreatment2TripFuelUsed 3741;
BA_ "SigType" SG_ 2566748414 Aftertreatment2TripFuelUsed 1;
BA_ "SPN" SG_ 2365428478 EngDerateRq 3644;
BA_ "SigType" SG_ 2365428478 EngDerateRq 1;
BA_ "SPN" SG_ 2365428478 EngEmergencyShutdownIndication 3607;
BA_ "SigType" SG_ 2365428478 EngEmergencyShutdownIndication 4;
BA_ "SPN" SG_ 2365428478 EngCtrlledShutdownRq 3606;
BA_ "SigType" SG_ 2365428478 EngCtrlledShutdownRq 4;
BA_ "SPN" SG_ 2365428478 EngCoolantCirculatingPumpCtrl 3605;
BA_ "SigType" SG_ 2365428478 EngCoolantCirculatingPumpCtrl 4;
BA_ "SPN" SG_ 2365428478 EngBlock_CoolantPreheaterCtrl 3604;
BA_ "SigType" SG_ 2365428478 EngBlock_CoolantPreheaterCtrl 4;
BA_ "SPN" SG_ 2365428478 EngElctrclSystmPwrCnsrvtionCtrl 3603;
BA_ "SigType" SG_ 2365428478 EngElctrclSystmPwrCnsrvtionCtrl 4;
BA_ "SPN" SG_ 2365428478 EngOilPreheaterCtrl 3602;
BA_ "SigType" SG_ 2365428478 EngOilPreheaterCtrl 4;
BA_ "SPN" SG_ 2365428478 EngOilPrimingPumpCtrl 3589;
BA_ "SigType" SG_ 2365428478 EngOilPrimingPumpCtrl 4;
BA_ "SPN" SG_ 2365428478 EngFuelShutoffValveLeakTestCtrl 3601;
BA_ "SigType" SG_ 2365428478 EngFuelShutoffValveLeakTestCtrl 4;
BA_ "SPN" SG_ 2365428478 EngFuelShutoff2Ctrl 2807;
BA_ "SigType" SG_ 2365428478 EngFuelShutoff2Ctrl 4;
BA_ "SPN" SG_ 2365428478 EngFuelShutoff1Ctrl 632;
BA_ "SigType" SG_ 2365428478 EngFuelShutoff1Ctrl 4;
BA_ "SPN" SG_ 2365428478 EngFuelShutoffVentCtrl 3608;
BA_ "SigType" SG_ 2365428478 EngFuelShutoffVentCtrl 4;
BA_ "SPN" SG_ 2365428478 TmeRemainingInEngOperatingState 3544;
BA_ "SigType" SG_ 2365428478 TmeRemainingInEngOperatingState 1;
BA_ "SPN" SG_ 2365428478 FuelPumpPrimerCtrl 4082;
BA_ "SigType" SG_ 2365428478 FuelPumpPrimerCtrl 4;
BA_ "SPN" SG_ 2365428478 EngOperatingState 3543;
BA_ "SigType" SG_ 2365428478 EngOperatingState 4;
BA_ "SPN" SG_ 2566743806 EngExhstVlvActtionSystemOilTemp 4288;
BA_ "SigType" SG_ 2566743806 EngExhstVlvActtionSystemOilTemp 1;
BA_ "SPN" SG_ 2566743806 EngExhstGsRcrcltn1MxrIntakeTemp 5020;
BA_ "SigType" SG_ 2566743806 EngExhstGsRcrcltn1MxrIntakeTemp 1;
BA_ "SPN" SG_ 2566743806 EngCoolantThermostatOpening 4194;
BA_ "SigType" SG_ 2566743806 EngCoolantThermostatOpening 1;
BA_ "SPN" SG_ 2566743806 EngCoolantPumpOutletTemp 4193;
BA_ "SigType" SG_ 2566743806 EngCoolantPumpOutletTemp 1;
BA_ "SPN" SG_ 2566743806 EngCoolantTemp2 4076;
BA_ "SigType" SG_ 2566743806 EngCoolantTemp2 1;
BA_ "SPN" SG_ 2499635454 NetVehicleWeightChange 413;
BA_ "SigType" SG_ 2499635454 NetVehicleWeightChange 1;
BA_ "SPN" SG_ 2499635454 GrossCombinationWeight 417;
BA_ "SigType" SG_ 2499635454 GrossCombinationWeight 1;
BA_ "SPN" SG_ 2550660862 ValveAssemblySupplyPress 4089;
BA_ "SigType" SG_ 2550660862 ValveAssemblySupplyPress 1;
BA_ "SPN" SG_ 2550660862 ValveAssemblyLoadSensePress 4088;
BA_ "SigType" SG_ 2550660862 ValveAssemblyLoadSensePress 1;
BA_ "SPN" SG_ 2550660862 ValvePilotPress 4087;
BA_ "SigType" SG_ 2550660862 ValvePilotPress 1;
BA_ "SPN" SG_ 2550660862 ValveLoadSensePress 4086;
BA_ "SigType" SG_ 2550660862 ValveLoadSensePress 1;
BA_ "SPN" SG_ 2566805758 BellowPressRearAxleRight 1728;
BA_ "SigType" SG_ 2566805758 BellowPressRearAxleRight 1;
BA_ "SPN" SG_ 2566805758 BellowPressRearAxleLeft 1727;
BA_ "SigType" SG_ 2566805758 BellowPressRearAxleLeft 1;
BA_ "SPN" SG_ 2566805758 BellowPressFrontAxleRight 1726;
BA_ "SigType" SG_ 2566805758 BellowPressFrontAxleRight 1;
BA_ "SPN" SG_ 2566805758 BellowPressFrontAxleLeft 1725;
BA_ "SigType" SG_ 2566805758 BellowPressFrontAxleLeft 1;
BA_ "SPN" SG_ 2566806014 RelativeLevelRearAxleRight 1723;
BA_ "SigType" SG_ 2566806014 RelativeLevelRearAxleRight 1;
BA_ "SPN" SG_ 2566806014 RelativeLevelRearAxleLeft 1724;
BA_ "SigType" SG_ 2566806014 RelativeLevelRearAxleLeft 1;
BA_ "SPN" SG_ 2566806014 RelativeLevelFrontAxleRight 1722;
BA_ "SigType" SG_ 2566806014 RelativeLevelFrontAxleRight 1;
BA_ "SPN" SG_ 2566806014 RelativeLevelFrontAxleLeft 1721;
BA_ "SigType" SG_ 2566806014 RelativeLevelFrontAxleLeft 1;
BA_ "SPN" SG_ 2362638078 SpeedDependentLevelCtrlRq 5295;
BA_ "SigType" SG_ 2362638078 SpeedDependentLevelCtrlRq 4;
BA_ "SPN" SG_ 2362638078 PrhbtAutomaticAirSuspensionCtrl 5274;
BA_ "SigType" SG_ 2362638078 PrhbtAutomaticAirSuspensionCtrl 4;
BA_ "SPN" SG_ 2362638078 MemoryLevelRq 5433;
BA_ "SigType" SG_ 2362638078 MemoryLevelRq 4;
BA_ "SPN" SG_ 2362638078 AllowLevelCtrlDuringBrakingCmd 5293;
BA_ "SigType" SG_ 2362638078 AllowLevelCtrlDuringBrakingCmd 4;
BA_ "SPN" SG_ 2362638078 ProhibitAirSuspensionCtrl 3215;
BA_ "SigType" SG_ 2362638078 ProhibitAirSuspensionCtrl 4;
BA_ "SPN" SG_ 2362638078 KneelingCmdRearAxle 1829;
BA_ "SigType" SG_ 2362638078 KneelingCmdRearAxle 4;
BA_ "SPN" SG_ 2362638078 KneelingCmdFrontAxle 1830;
BA_ "SigType" SG_ 2362638078 KneelingCmdFrontAxle 4;
BA_ "SPN" SG_ 2362638078 DamperStiffnessRqLift_TagAxle 1720;
BA_ "SigType" SG_ 2362638078 DamperStiffnessRqLift_TagAxle 1;
BA_ "SPN" SG_ 2362638078 DamperStiffnessRqRearAxle 1719;
BA_ "SigType" SG_ 2362638078 DamperStiffnessRqRearAxle 1;
BA_ "SPN" SG_ 2362638078 DamperStiffnessRqFrontAxle 1718;
BA_ "SigType" SG_ 2362638078 DamperStiffnessRqFrontAxle 1;
BA_ "SPN" SG_ 2362638078 LevelCtrlModeRq 1753;
BA_ "SigType" SG_ 2362638078 LevelCtrlModeRq 4;
BA_ "SPN" SG_ 2362638078 NominalLevelRqRearAxle 1750;
BA_ "SigType" SG_ 2362638078 NominalLevelRqRearAxle 4;
BA_ "SPN" SG_ 2362638078 NominalLevelRqFrontAxle 1751;
BA_ "SigType" SG_ 2362638078 NominalLevelRqFrontAxle 4;
BA_ "SPN" SG_ 2362638078 KneelingCtrlModeRq 1747;
BA_ "SigType" SG_ 2362638078 KneelingCtrlModeRq 4;
BA_ "SPN" SG_ 2362638078 KneelingRqRightSide 1748;
BA_ "SigType" SG_ 2362638078 KneelingRqRightSide 4;
BA_ "SPN" SG_ 2362638078 KneelingRqLeftSide 1749;
BA_ "SigType" SG_ 2362638078 KneelingRqLeftSide 4;
BA_ "SPN" SG_ 2362638078 AutomaticTractionHelp 2984;
BA_ "SigType" SG_ 2362638078 AutomaticTractionHelp 4;
BA_ "SPN" SG_ 2362638078 LiftAxle2PosCmd 1828;
BA_ "SigType" SG_ 2362638078 LiftAxle2PosCmd 4;
BA_ "SPN" SG_ 2362638078 LiftAxle1PosCmd 1752;
BA_ "SigType" SG_ 2362638078 LiftAxle1PosCmd 4;
BA_ "SPN" SG_ 2365479678 SpeedDependantLevelCtrlStatus 5296;
BA_ "SigType" SG_ 2365479678 SpeedDependantLevelCtrlStatus 4;
BA_ "SPN" SG_ 2365479678 MemoryLevel 5432;
BA_ "SigType" SG_ 2365479678 MemoryLevel 4;
BA_ "SPN" SG_ 2365479678 AllwLvelCtrlDuringBrakingStatus 5294;
BA_ "SigType" SG_ 2365479678 AllwLvelCtrlDuringBrakingStatus 4;
BA_ "SPN" SG_ 2365479678 SspensionCtrlRefusalInformation 1827;
BA_ "SigType" SG_ 2365479678 SspensionCtrlRefusalInformation 4;
BA_ "SPN" SG_ 2365479678 SuspensionRemoteCtrl2 1825;
BA_ "SigType" SG_ 2365479678 SuspensionRemoteCtrl2 4;
BA_ "SPN" SG_ 2365479678 SuspensionRemoteCtrl1 1826;
BA_ "SigType" SG_ 2365479678 SuspensionRemoteCtrl1 4;
BA_ "SPN" SG_ 2365479678 RearAxleInBumperRange 1823;
BA_ "SigType" SG_ 2365479678 RearAxleInBumperRange 4;
BA_ "SPN" SG_ 2365479678 FrontAxleInBumperRange 1824;
BA_ "SigType" SG_ 2365479678 FrontAxleInBumperRange 4;
BA_ "SPN" SG_ 2365479678 DoorRelease 1744;
BA_ "SigType" SG_ 2365479678 DoorRelease 4;
BA_ "SPN" SG_ 2365479678 VehicleMotionInhibit 1745;
BA_ "SigType" SG_ 2365479678 VehicleMotionInhibit 4;
BA_ "SPN" SG_ 2365479678 SecurityDevice 1746;
BA_ "SigType" SG_ 2365479678 SecurityDevice 4;
BA_ "SPN" SG_ 2365479678 LevelCtrlMode 1741;
BA_ "SigType" SG_ 2365479678 LevelCtrlMode 4;
BA_ "SPN" SG_ 2365479678 KneelingInformation 1742;
BA_ "SigType" SG_ 2365479678 KneelingInformation 4;
BA_ "SPN" SG_ 2365479678 LiftingCtrlModeRearAxle 1756;
BA_ "SigType" SG_ 2365479678 LiftingCtrlModeRearAxle 4;
BA_ "SPN" SG_ 2365479678 LiftingCtrlModeFrontAxle 1739;
BA_ "SigType" SG_ 2365479678 LiftingCtrlModeFrontAxle 4;
BA_ "SPN" SG_ 2365479678 LoweringCtrlModeRearAxle 1755;
BA_ "SigType" SG_ 2365479678 LoweringCtrlModeRearAxle 4;
BA_ "SPN" SG_ 2365479678 LoweringCtrlModeFrontAxle 1740;
BA_ "SigType" SG_ 2365479678 LoweringCtrlModeFrontAxle 4;
BA_ "SPN" SG_ 2365479678 AboveNominalLevelRearAxle 1736;
BA_ "SigType" SG_ 2365479678 AboveNominalLevelRearAxle 4;
BA_ "SPN" SG_ 2365479678 AboveNominalLevelFrontAxle 1737;
BA_ "SigType" SG_ 2365479678 AboveNominalLevelFrontAxle 4;
BA_ "SPN" SG_ 2365479678 BelowNominalLevelRearAxle 1754;
BA_ "SigType" SG_ 2365479678 BelowNominalLevelRearAxle 4;
BA_ "SPN" SG_ 2365479678 BelowNominalLevelFrontAxle 1738;
BA_ "SigType" SG_ 2365479678 BelowNominalLevelFrontAxle 4;
BA_ "SPN" SG_ 2365479678 NominalLevelRearAxle 1733;
BA_ "SigType" SG_ 2365479678 NominalLevelRearAxle 4;
BA_ "SPN" SG_ 2365479678 NominalLevelFrontAxle 1734;
BA_ "SigType" SG_ 2365479678 NominalLevelFrontAxle 4;
BA_ "SPN" SG_ 2365479678 LiftAxle2Pos 1822;
BA_ "SigType" SG_ 2365479678 LiftAxle2Pos 4;
BA_ "SPN" SG_ 2365479678 LiftAxle1Pos 1743;
BA_ "SigType" SG_ 2365479678 LiftAxle1Pos 4;
BA_ "SPN" SG_ 2566837758 Alt4Status 3356;
BA_ "SigType" SG_ 2566837758 Alt4Status 4;
BA_ "SPN" SG_ 2566837758 Alt3Status 3355;
BA_ "SigType" SG_ 2566837758 Alt3Status 4;
BA_ "SPN" SG_ 2566837758 Alt2Status 3354;
BA_ "SigType" SG_ 2566837758 Alt2Status 4;
BA_ "SPN" SG_ 2566837758 Alt1Status 3353;
BA_ "SigType" SG_ 2566837758 Alt1Status 4;
BA_ "SPN" SG_ 2566837758 AltSpeed 589;
BA_ "SigType" SG_ 2566837758 AltSpeed 1;
BA_ "SPN" SG_ 2633922558 AuxAbsPressReading 138;
BA_ "SigType" SG_ 2633922558 AuxAbsPressReading 1;
BA_ "SPN" SG_ 2633922558 AuxGagePressReading1 137;
BA_ "SigType" SG_ 2633922558 AuxGagePressReading1 1;
BA_ "SPN" SG_ 2633922558 AuxVacuumPressReading 136;
BA_ "SigType" SG_ 2633922558 AuxVacuumPressReading 1;
BA_ "SPN" SG_ 2566775038 SpecificHumidity 4490;
BA_ "SigType" SG_ 2566775038 SpecificHumidity 1;
BA_ "SPN" SG_ 2566775038 SolarSensorMax 2611;
BA_ "SigType" SG_ 2566775038 SolarSensorMax 1;
BA_ "SPN" SG_ 2566775038 SolarIntensityPercent 2610;
BA_ "SigType" SG_ 2566775038 SolarIntensityPercent 1;
BA_ "SPN" SG_ 2499635966 AxleGroupWeight 409;
BA_ "SigType" SG_ 2499635966 AxleGroupWeight 1;
BA_ "SPN" SG_ 2499635966 AxleGroupLocation 4073;
BA_ "SigType" SG_ 2499635966 AxleGroupLocation 4;
BA_ "SPN" SG_ 2633853438 AxleGroupLocation 4074;
BA_ "SigType" SG_ 2633853438 AxleGroupLocation 4;
BA_ "SPN" SG_ 2633853438 AxleGroupFullWeightCalib 407;
BA_ "SigType" SG_ 2633853438 AxleGroupFullWeightCalib 1;
BA_ "SPN" SG_ 2633853438 AxleGroupEmptyWeightCalib 408;
BA_ "SigType" SG_ 2633853438 AxleGroupEmptyWeightCalib 1;
BA_ "SPN" SG_ 2432520702 DsrdAftrcoolerCoolantIntakeTemp 4199;
BA_ "SigType" SG_ 2432520702 DsrdAftrcoolerCoolantIntakeTemp 1;
BA_ "SPN" SG_ 2432520702 DsrdAftrclrClntThrmostatOpening 4200;
BA_ "SigType" SG_ 2432520702 DsrdAftrclrClntThrmostatOpening 1;
BA_ "SPN" SG_ 2432520702 AftrcoolerCoolantThermostatMode 4198;
BA_ "SigType" SG_ 2432520702 AftrcoolerCoolantThermostatMode 4;
BA_ "SPN" SG_ 2566745086 AddtnlTrlrAxlGrpWeightAvailable 4072;
BA_ "SigType" SG_ 2566745086 AddtnlTrlrAxlGrpWeightAvailable 4;
BA_ "SPN" SG_ 2566745086 TrilerHAxleGroupWeightAvailable 4071;
BA_ "SigType" SG_ 2566745086 TrilerHAxleGroupWeightAvailable 4;
BA_ "SPN" SG_ 2566745086 TrilerGAxleGroupWeightAvailable 4070;
BA_ "SigType" SG_ 2566745086 TrilerGAxleGroupWeightAvailable 4;
BA_ "SPN" SG_ 2566745086 TrilerFAxleGroupWeightAvailable 4069;
BA_ "SigType" SG_ 2566745086 TrilerFAxleGroupWeightAvailable 4;
BA_ "SPN" SG_ 2566745086 TrilerEAxleGroupWeightAvailable 4068;
BA_ "SigType" SG_ 2566745086 TrilerEAxleGroupWeightAvailable 4;
BA_ "SPN" SG_ 2566745086 TrilerDAxleGroupWeightAvailable 4067;
BA_ "SigType" SG_ 2566745086 TrilerDAxleGroupWeightAvailable 4;
BA_ "SPN" SG_ 2566745086 TrilerCAxleGroupWeightAvailable 4066;
BA_ "SigType" SG_ 2566745086 TrilerCAxleGroupWeightAvailable 4;
BA_ "SPN" SG_ 2566745086 TrilerBAxleGroupWeightAvailable 4065;
BA_ "SigType" SG_ 2566745086 TrilerBAxleGroupWeightAvailable 4;
BA_ "SPN" SG_ 2566745086 TrilerAAxleGroupWeightAvailable 4064;
BA_ "SigType" SG_ 2566745086 TrilerAAxleGroupWeightAvailable 4;
BA_ "SPN" SG_ 2566745086 AddtnlTrctrAxlGrpWightAvailable 4063;
BA_ "SigType" SG_ 2566745086 AddtnlTrctrAxlGrpWightAvailable 4;
BA_ "SPN" SG_ 2566745086 TagAxleGroupWeightAvailable 4062;
BA_ "SigType" SG_ 2566745086 TagAxleGroupWeightAvailable 4;
BA_ "SPN" SG_ 2566745086 DriveAxleGroupWeightAvailable 4061;
BA_ "SigType" SG_ 2566745086 DriveAxleGroupWeightAvailable 4;
BA_ "SPN" SG_ 2566745086 LiftAxleGroupWeightAvailable 4060;
BA_ "SigType" SG_ 2566745086 LiftAxleGroupWeightAvailable 4;
BA_ "SPN" SG_ 2566745086 SteerAxleGroupWeightAvailable 4059;
BA_ "SigType" SG_ 2566745086 SteerAxleGroupWeightAvailable 4;
BA_ "SPN" SG_ 2566744062 ZeroNetVehicleWeightChange 4075;
BA_ "SigType" SG_ 2566744062 ZeroNetVehicleWeightChange 4;
BA_ "SPN" SG_ 2499630078 EngExhaustGasTempAverageBank2 4152;
BA_ "SigType" SG_ 2499630078 EngExhaustGasTempAverageBank2 1;
BA_ "SPN" SG_ 2499630078 EngExhaustGasTempAverageBank1 4153;
BA_ "SigType" SG_ 2499630078 EngExhaustGasTempAverageBank1 1;
BA_ "SPN" SG_ 2499630078 EngExhaustGasTempAverage 4151;
BA_ "SigType" SG_ 2499630078 EngExhaustGasTempAverage 1;
BA_ "SPN" SG_ 2566754558 AETCSpeedValue 3560;
BA_ "SPN" SG_ 2566754558 AETCTorqueValue 3561;
BA_ "SigType" SG_ 2566754558 AETCTorqueValue 1;
BA_ "SPN" SG_ 2566754558 NumberOfAETCDataPoints 3559;
BA_ "SPN" SG_ 2566754558 AETCDataCollectionStandard 3558;
BA_ "SigType" SG_ 2566754558 AETCDataCollectionStandard 4;
BA_ "SPN" SG_ 2566749950 RightHeadlampLightDistribution 3694;
BA_ "SigType" SG_ 2566749950 RightHeadlampLightDistribution 4;
BA_ "SPN" SG_ 2566749950 LeftHeadlampLightDistribution 3693;
BA_ "SigType" SG_ 2566749950 LeftHeadlampLightDistribution 4;
BA_ "SPN" SG_ 2566749950 RghtHeadlampDynamicBendingLight 3692;
BA_ "SPN" SG_ 2566749950 LeftHeadlampDynamicBendingLight 3691;
BA_ "SPN" SG_ 2566838782 AuxI_O16 716;
BA_ "SigType" SG_ 2566838782 AuxI_O16 4;
BA_ "SPN" SG_ 2566838782 AuxI_O15 715;
BA_ "SigType" SG_ 2566838782 AuxI_O15 4;
BA_ "SPN" SG_ 2566838782 AuxI_O14 714;
BA_ "SigType" SG_ 2566838782 AuxI_O14 4;
BA_ "SPN" SG_ 2566838782 AuxI_O13 713;
BA_ "SigType" SG_ 2566838782 AuxI_O13 4;
BA_ "SPN" SG_ 2566838782 AuxI_O12 712;
BA_ "SigType" SG_ 2566838782 AuxI_O12 4;
BA_ "SPN" SG_ 2566838782 AuxI_O11 711;
BA_ "SigType" SG_ 2566838782 AuxI_O11 4;
BA_ "SPN" SG_ 2566838782 AuxI_O10 710;
BA_ "SigType" SG_ 2566838782 AuxI_O10 4;
BA_ "SPN" SG_ 2566838782 AuxI_O09 709;
BA_ "SigType" SG_ 2566838782 AuxI_O09 4;
BA_ "SPN" SG_ 2566838782 AuxI_O08 708;
BA_ "SigType" SG_ 2566838782 AuxI_O08 4;
BA_ "SPN" SG_ 2566838782 AuxI_O07 707;
BA_ "SigType" SG_ 2566838782 AuxI_O07 4;
BA_ "SPN" SG_ 2566838782 AuxI_O06 706;
BA_ "SigType" SG_ 2566838782 AuxI_O06 4;
BA_ "SPN" SG_ 2566838782 AuxI_O05 705;
BA_ "SigType" SG_ 2566838782 AuxI_O05 4;
BA_ "SPN" SG_ 2566838782 AuxI_O04 704;
BA_ "SigType" SG_ 2566838782 AuxI_O04 4;
BA_ "SPN" SG_ 2566838782 AuxI_O03 703;
BA_ "SigType" SG_ 2566838782 AuxI_O03 4;
BA_ "SPN" SG_ 2566838782 AuxI_O02 702;
BA_ "SigType" SG_ 2566838782 AuxI_O02 4;
BA_ "SPN" SG_ 2566838782 AuxI_O01 701;
BA_ "SigType" SG_ 2566838782 AuxI_O01 4;
BA_ "SPN" SG_ 2566838782 AuxI_OChannel2 1084;
BA_ "SigType" SG_ 2566838782 AuxI_OChannel2 1;
BA_ "SPN" SG_ 2566838782 AuxI_OChannel1 1083;
BA_ "SigType" SG_ 2566838782 AuxI_OChannel1 1;
BA_ "SPN" SG_ 2561146622 AuxI_O45 3868;
BA_ "SigType" SG_ 2561146622 AuxI_O45 4;
BA_ "SPN" SG_ 2561146622 AuxI_O46 3869;
BA_ "SigType" SG_ 2561146622 AuxI_O46 4;
BA_ "SPN" SG_ 2561146622 AuxI_O47 3870;
BA_ "SigType" SG_ 2561146622 AuxI_O47 4;
BA_ "SPN" SG_ 2561146622 AuxI_O48 3871;
BA_ "SigType" SG_ 2561146622 AuxI_O48 4;
BA_ "SPN" SG_ 2561146622 AuxI_O41 3864;
BA_ "SigType" SG_ 2561146622 AuxI_O41 4;
BA_ "SPN" SG_ 2561146622 AuxI_O42 3865;
BA_ "SigType" SG_ 2561146622 AuxI_O42 4;
BA_ "SPN" SG_ 2561146622 AuxI_O43 3866;
BA_ "SigType" SG_ 2561146622 AuxI_O43 4;
BA_ "SPN" SG_ 2561146622 AuxI_O44 3867;
BA_ "SigType" SG_ 2561146622 AuxI_O44 4;
BA_ "SPN" SG_ 2561146622 AuxI_O37 3860;
BA_ "SigType" SG_ 2561146622 AuxI_O37 4;
BA_ "SPN" SG_ 2561146622 AuxI_O38 3861;
BA_ "SigType" SG_ 2561146622 AuxI_O38 4;
BA_ "SPN" SG_ 2561146622 AuxI_O39 3862;
BA_ "SigType" SG_ 2561146622 AuxI_O39 4;
BA_ "SPN" SG_ 2561146622 AuxI_O40 3863;
BA_ "SigType" SG_ 2561146622 AuxI_O40 4;
BA_ "SPN" SG_ 2561146622 AuxI_O33 3856;
BA_ "SigType" SG_ 2561146622 AuxI_O33 4;
BA_ "SPN" SG_ 2561146622 AuxI_O34 3857;
BA_ "SigType" SG_ 2561146622 AuxI_O34 4;
BA_ "SPN" SG_ 2561146622 AuxI_O35 3858;
BA_ "SigType" SG_ 2561146622 AuxI_O35 4;
BA_ "SPN" SG_ 2561146622 AuxI_O36 3859;
BA_ "SigType" SG_ 2561146622 AuxI_O36 4;
BA_ "SPN" SG_ 2561146622 AuxI_O29 3852;
BA_ "SigType" SG_ 2561146622 AuxI_O29 4;
BA_ "SPN" SG_ 2561146622 AuxI_O30 3853;
BA_ "SigType" SG_ 2561146622 AuxI_O30 4;
BA_ "SPN" SG_ 2561146622 AuxI_O31 3854;
BA_ "SigType" SG_ 2561146622 AuxI_O31 4;
BA_ "SPN" SG_ 2561146622 AuxI_O32 3855;
BA_ "SigType" SG_ 2561146622 AuxI_O32 4;
BA_ "SPN" SG_ 2561146622 AuxI_O25 3848;
BA_ "SigType" SG_ 2561146622 AuxI_O25 4;
BA_ "SPN" SG_ 2561146622 AuxI_O26 3849;
BA_ "SigType" SG_ 2561146622 AuxI_O26 4;
BA_ "SPN" SG_ 2561146622 AuxI_O27 3850;
BA_ "SigType" SG_ 2561146622 AuxI_O27 4;
BA_ "SPN" SG_ 2561146622 AuxI_O28 3851;
BA_ "SigType" SG_ 2561146622 AuxI_O28 4;
BA_ "SPN" SG_ 2561146622 AuxI_O21 3844;
BA_ "SigType" SG_ 2561146622 AuxI_O21 4;
BA_ "SPN" SG_ 2561146622 AuxI_O22 3845;
BA_ "SigType" SG_ 2561146622 AuxI_O22 4;
BA_ "SPN" SG_ 2561146622 AuxI_O23 3846;
BA_ "SigType" SG_ 2561146622 AuxI_O23 4;
BA_ "SPN" SG_ 2561146622 AuxI_O24 3847;
BA_ "SigType" SG_ 2561146622 AuxI_O24 4;
BA_ "SPN" SG_ 2561146622 AuxI_O17 3840;
BA_ "SigType" SG_ 2561146622 AuxI_O17 4;
BA_ "SPN" SG_ 2561146622 AuxI_O18 3841;
BA_ "SigType" SG_ 2561146622 AuxI_O18 4;
BA_ "SPN" SG_ 2561146622 AuxI_O19 3842;
BA_ "SigType" SG_ 2561146622 AuxI_O19 4;
BA_ "SPN" SG_ 2561146622 AuxI_O20 3843;
BA_ "SigType" SG_ 2561146622 AuxI_O20 4;
BA_ "SPN" SG_ 2561081086 AuxI_O77 3900;
BA_ "SigType" SG_ 2561081086 AuxI_O77 4;
BA_ "SPN" SG_ 2561081086 AuxI_O78 3901;
BA_ "SigType" SG_ 2561081086 AuxI_O78 4;
BA_ "SPN" SG_ 2561081086 AuxI_O79 3902;
BA_ "SigType" SG_ 2561081086 AuxI_O79 4;
BA_ "SPN" SG_ 2561081086 AuxI_O80 3903;
BA_ "SigType" SG_ 2561081086 AuxI_O80 4;
BA_ "SPN" SG_ 2561081086 AuxI_O73 3896;
BA_ "SigType" SG_ 2561081086 AuxI_O73 4;
BA_ "SPN" SG_ 2561081086 AuxI_O74 3897;
BA_ "SigType" SG_ 2561081086 AuxI_O74 4;
BA_ "SPN" SG_ 2561081086 AuxI_O75 3898;
BA_ "SigType" SG_ 2561081086 AuxI_O75 4;
BA_ "SPN" SG_ 2561081086 AuxI_O76 3899;
BA_ "SigType" SG_ 2561081086 AuxI_O76 4;
BA_ "SPN" SG_ 2561081086 AuxI_O69 3892;
BA_ "SigType" SG_ 2561081086 AuxI_O69 4;
BA_ "SPN" SG_ 2561081086 AuxI_O70 3893;
BA_ "SigType" SG_ 2561081086 AuxI_O70 4;
BA_ "SPN" SG_ 2561081086 AuxI_O71 3894;
BA_ "SigType" SG_ 2561081086 AuxI_O71 4;
BA_ "SPN" SG_ 2561081086 AuxI_O72 3895;
BA_ "SigType" SG_ 2561081086 AuxI_O72 4;
BA_ "SPN" SG_ 2561081086 AuxI_O65 3888;
BA_ "SigType" SG_ 2561081086 AuxI_O65 4;
BA_ "SPN" SG_ 2561081086 AuxI_O66 3889;
BA_ "SigType" SG_ 2561081086 AuxI_O66 4;
BA_ "SPN" SG_ 2561081086 AuxI_O67 3890;
BA_ "SigType" SG_ 2561081086 AuxI_O67 4;
BA_ "SPN" SG_ 2561081086 AuxI_O68 3891;
BA_ "SigType" SG_ 2561081086 AuxI_O68 4;
BA_ "SPN" SG_ 2561081086 AuxI_O61 3884;
BA_ "SigType" SG_ 2561081086 AuxI_O61 4;
BA_ "SPN" SG_ 2561081086 AuxI_O62 3885;
BA_ "SigType" SG_ 2561081086 AuxI_O62 4;
BA_ "SPN" SG_ 2561081086 AuxI_O63 3886;
BA_ "SigType" SG_ 2561081086 AuxI_O63 4;
BA_ "SPN" SG_ 2561081086 AuxI_O64 3887;
BA_ "SigType" SG_ 2561081086 AuxI_O64 4;
BA_ "SPN" SG_ 2561081086 AuxI_O57 3880;
BA_ "SigType" SG_ 2561081086 AuxI_O57 4;
BA_ "SPN" SG_ 2561081086 AuxI_O58 3881;
BA_ "SigType" SG_ 2561081086 AuxI_O58 4;
BA_ "SPN" SG_ 2561081086 AuxI_O59 3882;
BA_ "SigType" SG_ 2561081086 AuxI_O59 4;
BA_ "SPN" SG_ 2561081086 AuxI_O60 3883;
BA_ "SigType" SG_ 2561081086 AuxI_O60 4;
BA_ "SPN" SG_ 2561081086 AuxI_O53 3876;
BA_ "SigType" SG_ 2561081086 AuxI_O53 4;
BA_ "SPN" SG_ 2561081086 AuxI_O54 3877;
BA_ "SigType" SG_ 2561081086 AuxI_O54 4;
BA_ "SPN" SG_ 2561081086 AuxI_O55 3878;
BA_ "SigType" SG_ 2561081086 AuxI_O55 4;
BA_ "SPN" SG_ 2561081086 AuxI_O56 3879;
BA_ "SigType" SG_ 2561081086 AuxI_O56 4;
BA_ "SPN" SG_ 2561081086 AuxI_O49 3872;
BA_ "SigType" SG_ 2561081086 AuxI_O49 4;
BA_ "SPN" SG_ 2561081086 AuxI_O50 3873;
BA_ "SigType" SG_ 2561081086 AuxI_O50 4;
BA_ "SPN" SG_ 2561081086 AuxI_O51 3874;
BA_ "SigType" SG_ 2561081086 AuxI_O51 4;
BA_ "SPN" SG_ 2561081086 AuxI_O52 3875;
BA_ "SigType" SG_ 2561081086 AuxI_O52 4;
BA_ "SPN" SG_ 2561015550 AuxI_O92 3915;
BA_ "SigType" SG_ 2561015550 AuxI_O92 4;
BA_ "SPN" SG_ 2561015550 AuxI_O85 3908;
BA_ "SigType" SG_ 2561015550 AuxI_O85 4;
BA_ "SPN" SG_ 2561015550 AuxI_O86 3909;
BA_ "SigType" SG_ 2561015550 AuxI_O86 4;
BA_ "SPN" SG_ 2561015550 AuxI_O87 3910;
BA_ "SigType" SG_ 2561015550 AuxI_O87 4;
BA_ "SPN" SG_ 2561015550 AuxI_O88 3911;
BA_ "SigType" SG_ 2561015550 AuxI_O88 4;
BA_ "SPN" SG_ 2561015550 AuxI_O81 3904;
BA_ "SigType" SG_ 2561015550 AuxI_O81 4;
BA_ "SPN" SG_ 2561015550 AuxI_O82 3905;
BA_ "SigType" SG_ 2561015550 AuxI_O82 4;
BA_ "SPN" SG_ 2561015550 AuxI_O83 3906;
BA_ "SigType" SG_ 2561015550 AuxI_O83 4;
BA_ "SPN" SG_ 2561015550 AuxI_O84 3907;
BA_ "SigType" SG_ 2561015550 AuxI_O84 4;
BA_ "SPN" SG_ 2561015550 AuxI_O109 3932;
BA_ "SigType" SG_ 2561015550 AuxI_O109 4;
BA_ "SPN" SG_ 2561015550 AuxI_O110 3933;
BA_ "SigType" SG_ 2561015550 AuxI_O110 4;
BA_ "SPN" SG_ 2561015550 AuxI_O111 3934;
BA_ "SigType" SG_ 2561015550 AuxI_O111 4;
BA_ "SPN" SG_ 2561015550 AuxI_O112 3935;
BA_ "SigType" SG_ 2561015550 AuxI_O112 4;
BA_ "SPN" SG_ 2561015550 AuxI_O105 3928;
BA_ "SigType" SG_ 2561015550 AuxI_O105 4;
BA_ "SPN" SG_ 2561015550 AuxI_O106 3929;
BA_ "SigType" SG_ 2561015550 AuxI_O106 4;
BA_ "SPN" SG_ 2561015550 AuxI_O107 3930;
BA_ "SigType" SG_ 2561015550 AuxI_O107 4;
BA_ "SPN" SG_ 2561015550 AuxI_O108 3931;
BA_ "SigType" SG_ 2561015550 AuxI_O108 4;
BA_ "SPN" SG_ 2561015550 AuxI_O101 3924;
BA_ "SigType" SG_ 2561015550 AuxI_O101 4;
BA_ "SPN" SG_ 2561015550 AuxI_O102 3925;
BA_ "SigType" SG_ 2561015550 AuxI_O102 4;
BA_ "SPN" SG_ 2561015550 AuxI_O103 3926;
BA_ "SigType" SG_ 2561015550 AuxI_O103 4;
BA_ "SPN" SG_ 2561015550 AuxI_O104 3927;
BA_ "SigType" SG_ 2561015550 AuxI_O104 4;
BA_ "SPN" SG_ 2561015550 AuxI_O97 3920;
BA_ "SigType" SG_ 2561015550 AuxI_O97 4;
BA_ "SPN" SG_ 2561015550 AuxI_O98 3921;
BA_ "SigType" SG_ 2561015550 AuxI_O98 4;
BA_ "SPN" SG_ 2561015550 AuxI_O99 3922;
BA_ "SigType" SG_ 2561015550 AuxI_O99 4;
BA_ "SPN" SG_ 2561015550 AuxI_O100 3923;
BA_ "SigType" SG_ 2561015550 AuxI_O100 4;
BA_ "SPN" SG_ 2561015550 AuxI_O93 3916;
BA_ "SigType" SG_ 2561015550 AuxI_O93 4;
BA_ "SPN" SG_ 2561015550 AuxI_O94 3917;
BA_ "SigType" SG_ 2561015550 AuxI_O94 4;
BA_ "SPN" SG_ 2561015550 AuxI_O95 3918;
BA_ "SigType" SG_ 2561015550 AuxI_O95 4;
BA_ "SPN" SG_ 2561015550 AuxI_O96 3919;
BA_ "SigType" SG_ 2561015550 AuxI_O96 4;
BA_ "SPN" SG_ 2561015550 AuxI_O89 3912;
BA_ "SigType" SG_ 2561015550 AuxI_O89 4;
BA_ "SPN" SG_ 2561015550 AuxI_O90 3913;
BA_ "SigType" SG_ 2561015550 AuxI_O90 4;
BA_ "SPN" SG_ 2561015550 AuxI_O91 3914;
BA_ "SigType" SG_ 2561015550 AuxI_O91 4;
BA_ "SPN" SG_ 2566746622 TrailerBrakeStrokeAxle5Right 3804;
BA_ "SPN" SG_ 2566746622 TrailerBrakeStrokeAxle5Left 3803;
BA_ "SPN" SG_ 2566746622 TrailerBrakeStrokeAxle4Right 3802;
BA_ "SPN" SG_ 2566746622 TrailerBrakeStrokeAxle4Left 3801;
BA_ "SPN" SG_ 2566746622 TrailerBrakeStrokeAxle3Right 3800;
BA_ "SPN" SG_ 2566746622 TrailerBrakeStrokeAxle3Left 3799;
BA_ "SPN" SG_ 2566746622 TrailerBrakeStrokeAxle2Right 3798;
BA_ "SPN" SG_ 2566746622 TrailerBrakeStrokeAxle2Left 3797;
BA_ "SPN" SG_ 2566746622 TrailerBrakeStrokeAxle1Right 3796;
BA_ "SPN" SG_ 2566746622 TrailerBrakeStrokeAxle1Left 3795;
BA_ "SPN" SG_ 2566746622 TractorBrakeStrokeAxle5Right 3794;
BA_ "SPN" SG_ 2566746622 TractorBrakeStrokeAxle5Left 3793;
BA_ "SPN" SG_ 2566746622 TractorBrakeStrokeAxle4Right 3792;
BA_ "SPN" SG_ 2566746622 TractorBrakeStrokeAxle4Left 3791;
BA_ "SPN" SG_ 2566746622 TractorBrakeStrokeAxle3Right 3790;
BA_ "SPN" SG_ 2566746622 TractorBrakeStrokeAxle3Left 3789;
BA_ "SPN" SG_ 2566746622 TractorBrakeStrokeAxle2Right 3788;
BA_ "SPN" SG_ 2566746622 TractorBrakeStrokeAxle2Left 3787;
BA_ "SPN" SG_ 2566746622 TractorBrakeStrokeAxle1Right 3786;
BA_ "SPN" SG_ 2566746622 TractorBrakeStrokeAxle1Left 3785;
BA_ "SPN" SG_ 2566845950 EngAirIntakeTemp 172;
BA_ "SigType" SG_ 2566845950 EngAirIntakeTemp 1;
BA_ "SPN" SG_ 2566845950 RoadSurfaceTemp 79;
BA_ "SigType" SG_ 2566845950 RoadSurfaceTemp 1;
BA_ "SPN" SG_ 2566845950 AmbientAirTemp 171;
BA_ "SigType" SG_ 2566845950 AmbientAirTemp 1;
BA_ "SPN" SG_ 2566845950 CabInteriorTemp 170;
BA_ "SigType" SG_ 2566845950 CabInteriorTemp 1;
BA_ "SPN" SG_ 2566845950 BarometricPress 108;
BA_ "SigType" SG_ 2566845950 BarometricPress 1;
BA_ "SPN" SG_ 2566840062 EngAirStartPress 82;
BA_ "SigType" SG_ 2566840062 EngAirStartPress 1;
BA_ "SPN" SG_ 2566827774 ServiceBrakeCircuit2AirPress 1088;
BA_ "SigType" SG_ 2566827774 ServiceBrakeCircuit2AirPress 1;
BA_ "SPN" SG_ 2566827774 ServiceBrakeCircuit1AirPress 1087;
BA_ "SigType" SG_ 2566827774 ServiceBrakeCircuit1AirPress 1;
BA_ "SPN" SG_ 2566827774 AirCompressorStatus 1351;
BA_ "SigType" SG_ 2566827774 AirCompressorStatus 4;
BA_ "SPN" SG_ 2566827774 AirSuspensionSupplyPress 1090;
BA_ "SigType" SG_ 2566827774 AirSuspensionSupplyPress 1;
BA_ "SPN" SG_ 2566827774 AuxEquipmentSupplyPress 1089;
BA_ "SigType" SG_ 2566827774 AuxEquipmentSupplyPress 1;
BA_ "SPN" SG_ 2566827774 ParkingAnd_OrTrailerAirPress 1086;
BA_ "SigType" SG_ 2566827774 ParkingAnd_OrTrailerAirPress 1;
BA_ "SPN" SG_ 2566827774 PneumaticSupplyPress 46;
BA_ "SigType" SG_ 2566827774 PneumaticSupplyPress 1;
BA_ "SPN" SG_ 2566846974 SteerAxleLubePress 2614;
BA_ "SigType" SG_ 2566846974 SteerAxleLubePress 1;
BA_ "SPN" SG_ 2566846974 SteerAxleTemp 75;
BA_ "SigType" SG_ 2566846974 SteerAxleTemp 1;
BA_ "SPN" SG_ 2566846974 DriveAxleLubePress 2613;
BA_ "SigType" SG_ 2566846974 DriveAxleLubePress 1;
BA_ "SPN" SG_ 2566846974 DriveAxleTemp 578;
BA_ "SigType" SG_ 2566846974 DriveAxleTemp 1;
BA_ "SPN" SG_ 2566846974 DriveAxleLiftAirPress 579;
BA_ "SigType" SG_ 2566846974 DriveAxleLiftAirPress 1;
BA_ "SPN" SG_ 2566846974 DriveAxleLocation 930;
BA_ "SigType" SG_ 2566846974 DriveAxleLocation 1;
BA_ "SPN" SG_ 2633935614 EngTurboWastegateValvePos 1693;
BA_ "SigType" SG_ 2633935614 EngTurboWastegateValvePos 1;
BA_ "SPN" SG_ 2633935614 EngGsMssFlwSnsrFelingCorrection 1694;
BA_ "SigType" SG_ 2633935614 EngGsMssFlwSnsrFelingCorrection 1;
BA_ "SPN" SG_ 2633935614 EngDsiredAbsIntakeManifoldPress 1692;
BA_ "SigType" SG_ 2633935614 EngDsiredAbsIntakeManifoldPress 1;
BA_ "SPN" SG_ 2633935614 EngGasFuelCorrectionFactor 1116;
BA_ "SigType" SG_ 2633935614 EngGasFuelCorrectionFactor 1;
BA_ "SPN" SG_ 2566803966 ACCUsageDemand 5023;
BA_ "SigType" SG_ 2566803966 ACCUsageDemand 4;
BA_ "SPN" SG_ 2566803966 RqedACCDistanceMode 1799;
BA_ "SPN" SG_ 2432593918 ForwardCollisionWarning 5022;
BA_ "SigType" SG_ 2432593918 ForwardCollisionWarning 4;
BA_ "SPN" SG_ 2432593918 ACCDistanceAlertSignal 1796;
BA_ "SigType" SG_ 2432593918 ACCDistanceAlertSignal 4;
BA_ "SPN" SG_ 2432593918 ACCSystemShutoffWarning 1797;
BA_ "SigType" SG_ 2432593918 ACCSystemShutoffWarning 4;
BA_ "SPN" SG_ 2432593918 ACCTargetDetected 1798;
BA_ "SigType" SG_ 2432593918 ACCTargetDetected 4;
BA_ "SPN" SG_ 2432593918 RoadCurvature 1591;
BA_ "SigType" SG_ 2432593918 RoadCurvature 1;
BA_ "SPN" SG_ 2432593918 AdptveCruiseCtrlSetDistanceMode 1589;
BA_ "SPN" SG_ 2432593918 AdaptiveCruiseCtrlMode 1590;
BA_ "SPN" SG_ 2432593918 AdaptiveCruiseCtrlSetSpeed 1588;
BA_ "SigType" SG_ 2432593918 AdaptiveCruiseCtrlSetSpeed 1;
BA_ "SPN" SG_ 2432593918 DistanceToForwardVehicle 1587;
BA_ "SigType" SG_ 2432593918 DistanceToForwardVehicle 1;
BA_ "SPN" SG_ 2432593918 SpeedOfForwardVehicle 1586;
BA_ "SigType" SG_ 2432593918 SpeedOfForwardVehicle 1;
BA_ "SPN" SG_ 2633935102 ArticulationAngle 1120;
BA_ "SigType" SG_ 2633935102 ArticulationAngle 1;
BA_ "SPN" SG_ 2633927934 RelativeHumidity 354;
BA_ "SigType" SG_ 2633927934 RelativeHumidity 1;
BA_ "SPN" SG_ 2633927934 AuxLevel 3087;
BA_ "SigType" SG_ 2633927934 AuxLevel 1;
BA_ "SPN" SG_ 2633927934 AuxPress2 1388;
BA_ "SigType" SG_ 2633927934 AuxPress2 1;
BA_ "SPN" SG_ 2633927934 AuxPress1 1387;
BA_ "SigType" SG_ 2633927934 AuxPress1 1;
BA_ "SPN" SG_ 2633927934 AuxTemp2 442;
BA_ "SigType" SG_ 2633927934 AuxTemp2 1;
BA_ "SPN" SG_ 2633927934 AuxTemp1 441;
BA_ "SigType" SG_ 2633927934 AuxTemp1 1;
BA_ "SPN" SG_ 2566847998 EngBlowerBypassValvePos 72;
BA_ "SigType" SG_ 2566847998 EngBlowerBypassValvePos 1;
BA_ "SPN" SG_ 2566847998 EngGasSupplyPress 159;
BA_ "SigType" SG_ 2566847998 EngGasSupplyPress 1;
BA_ "SPN" SG_ 2566803198 Status2OfDoors 3411;
BA_ "SigType" SG_ 2566803198 Status2OfDoors 4;
BA_ "SPN" SG_ 2566803198 Ramp_WheelChairLiftPos 1820;
BA_ "SigType" SG_ 2566803198 Ramp_WheelChairLiftPos 4;
BA_ "SPN" SG_ 2566803198 PosOfDoors 1821;
BA_ "SigType" SG_ 2566803198 PosOfDoors 4;
BA_ "SPN" SG_ 2565870334 FifthWheelRollWarningIndicator 3317;
BA_ "SigType" SG_ 2565870334 FifthWheelRollWarningIndicator 4;
BA_ "SPN" SG_ 2565870334 FifthWheelRollMoment 3310;
BA_ "SigType" SG_ 2565870334 FifthWheelRollMoment 1;
BA_ "SPN" SG_ 2565870334 FifthWheelDrawbarForce 3309;
BA_ "SigType" SG_ 2565870334 FifthWheelDrawbarForce 1;
BA_ "SPN" SG_ 2565870334 FifthWheelVerticalForce 3308;
BA_ "SigType" SG_ 2565870334 FifthWheelVerticalForce 1;
BA_ "SPN" SG_ 2566762238 FifthWheelSliderLockIndicator 3316;
BA_ "SigType" SG_ 2566762238 FifthWheelSliderLockIndicator 4;
BA_ "SPN" SG_ 2566762238 FifthWheelSliderPos 3311;
BA_ "SigType" SG_ 2566762238 FifthWheelSliderPos 1;
BA_ "SPN" SG_ 2566762238 FfthWhlLckCoupleStatusIndicator 3313;
BA_ "SigType" SG_ 2566762238 FfthWhlLckCoupleStatusIndicator 4;
BA_ "SPN" SG_ 2566762238 FfthWhlLckRadyToCoupleIndicator 3312;
BA_ "SigType" SG_ 2566762238 FfthWhlLckRadyToCoupleIndicator 4;
BA_ "SPN" SG_ 2566762238 FifthWheelErrorStatus 3307;
BA_ "SigType" SG_ 2566762238 FifthWheelErrorStatus 4;
BA_ "SPN" SG_ 2364543998 RollAndPitchMeasurementLatency 3327;
BA_ "SigType" SG_ 2364543998 RollAndPitchMeasurementLatency 1;
BA_ "SPN" SG_ 2364543998 PitchAndRollCompensated 3326;
BA_ "SigType" SG_ 2364543998 PitchAndRollCompensated 4;
BA_ "SPN" SG_ 2364543998 PitchRateFigureOfMerit 3325;
BA_ "SigType" SG_ 2364543998 PitchRateFigureOfMerit 4;
BA_ "SPN" SG_ 2364543998 RollAngleFigureOfMerit 3324;
BA_ "SigType" SG_ 2364543998 RollAngleFigureOfMerit 4;
BA_ "SPN" SG_ 2364543998 PitchAngleFigureOfMerit 3323;
BA_ "SigType" SG_ 2364543998 PitchAngleFigureOfMerit 4;
BA_ "SPN" SG_ 2364543998 PitchRate 3322;
BA_ "SigType" SG_ 2364543998 PitchRate 1;
BA_ "SPN" SG_ 2364543998 RollAngle 3319;
BA_ "SigType" SG_ 2364543998 RollAngle 1;
BA_ "SPN" SG_ 2364543998 PitchAngle 3318;
BA_ "SigType" SG_ 2364543998 PitchAngle 1;
BA_ "SPN" SG_ 2566846718 TransOilLevelMeasurementStatus 3026;
BA_ "SigType" SG_ 2566846718 TransOilLevelMeasurementStatus 4;
BA_ "SPN" SG_ 2566846718 TransOilLevelCountdownTimer 3028;
BA_ "SigType" SG_ 2566846718 TransOilLevelCountdownTimer 4;
BA_ "SPN" SG_ 2566846718 TransOilLevelHigh_Low 3027;
BA_ "SigType" SG_ 2566846718 TransOilLevelHigh_Low 1;
BA_ "SPN" SG_ 2566846718 TransOilTemp 177;
BA_ "SigType" SG_ 2566846718 TransOilTemp 1;
BA_ "SPN" SG_ 2566846718 TransOilPress 127;
BA_ "SigType" SG_ 2566846718 TransOilPress 1;
BA_ "SPN" SG_ 2566846718 TransFilterDiffPress 126;
BA_ "SigType" SG_ 2566846718 TransFilterDiffPress 1;
BA_ "SPN" SG_ 2566846718 TransOilLevel 124;
BA_ "SigType" SG_ 2566846718 TransOilLevel 1;
BA_ "SPN" SG_ 2566846718 ClutchPress 123;
BA_ "SigType" SG_ 2566846718 ClutchPress 1;
BA_ "SPN" SG_ 2566846462 ChargingSystemPotential 167;
BA_ "SigType" SG_ 2566846462 ChargingSystemPotential 1;
BA_ "SPN" SG_ 2566846462 AltCurrent 115;
BA_ "SigType" SG_ 2566846462 AltCurrent 1;
BA_ "SPN" SG_ 2566846462 NetBatteryCurrent 114;
BA_ "SigType" SG_ 2566846462 NetBatteryCurrent 1;
BA_ "SPN" SG_ 2566846462 KeyswitchBatteryPotential 158;
BA_ "SigType" SG_ 2566846462 KeyswitchBatteryPotential 1;
BA_ "SPN" SG_ 2566846462 BatteryPotential_PowerInput1 168;
BA_ "SigType" SG_ 2566846462 BatteryPotential_PowerInput1 1;
BA_ "SPN" SG_ 2566760702 WrlessCommunicationNetworkType2 3446;
BA_ "SigType" SG_ 2566760702 WrlessCommunicationNetworkType2 1;
BA_ "SPN" SG_ 2566760702 NetworkSignalStrength2 3445;
BA_ "SigType" SG_ 2566760702 NetworkSignalStrength2 1;
BA_ "SPN" SG_ 2566760702 NetworkAntennaStatus2 3444;
BA_ "SigType" SG_ 2566760702 NetworkAntennaStatus2 1;
BA_ "SPN" SG_ 2566760702 NetworkServiceStatus2 3443;
BA_ "SigType" SG_ 2566760702 NetworkServiceStatus2 1;
BA_ "SPN" SG_ 2566760702 NetworkTransceiverStatus2 3442;
BA_ "SigType" SG_ 2566760702 NetworkTransceiverStatus2 1;
BA_ "SPN" SG_ 2566760958 WrlessCommunicationNetworkType1 3372;
BA_ "SigType" SG_ 2566760958 WrlessCommunicationNetworkType1 1;
BA_ "SPN" SG_ 2566760958 NetworkSignalStrength1 3371;
BA_ "SigType" SG_ 2566760958 NetworkSignalStrength1 1;
BA_ "SPN" SG_ 2566760958 NetworkAntennaStatus1 3370;
BA_ "SigType" SG_ 2566760958 NetworkAntennaStatus1 1;
BA_ "SPN" SG_ 2566760958 NetworkServiceStatus1 3369;
BA_ "SigType" SG_ 2566760958 NetworkServiceStatus1 1;
BA_ "SPN" SG_ 2566760958 NetworkTransceiverStatus1 3368;
BA_ "SigType" SG_ 2566760958 NetworkTransceiverStatus1 1;
VAL_ 2566758654 Aftrtrtmnt2FlInjctor1HeaterCtrl 4 "Max";
VAL_ 2566758654 Aftrtratment2FuelEnableActuator 0 "notActive" 1 "active" 2 "reservedForSAEAssignment" 3 "notAvailable";
VAL_ 2566758654 Aftrtratment2RegenerationStatus 0 "notActive" 1 "active" 2 "reservedForSAEAssignment" 3 "notAvailable";
VAL_ 2566758654 Aftertreatment2Ignt 0 "notActive" 1 "active" 2 "reservedForSAEAssignment" 3 "notAvailable";
VAL_ 2566758654 Aftrtreatment2FuelDrainActuator 0 "notActive" 1 "active" 2 "reservedForSAEAssignment" 3 "notAvailable";
VAL_ 2565869822 Aftrtrtmnt2IntkGsSnsrPwerStatus 0 "NotInRange" 1 "InRange" 2 "Error" 3 "NotAvailable";
VAL_ 2565869822 Aftrtrtmnt2IntkGsSnsrHeaterCtrl 0 "Automatic" 1 "Preheat2" 2 "Preheat1" 3 "HeaterOff";
VAL_ 2565869822 Aftrtrtmnt2IntkWdRngO2RdngStble 0 "NotStable" 1 "Stable" 2 "Error" 3 "NotAvailable";
VAL_ 2565869822 Aftrtrtmnt2IntkNOxReadingStable 0 "NotStable" 1 "Stable" 2 "Error" 3 "NotAvailable";
VAL_ 2565869822 Aftrtrtmnt2IntkeGasSensorAtTemp 0 "NotInRange" 1 "InRange" 2 "Error" 3 "NotAvailable";
VAL_ 2565870078 Aftrtrtmnt2OtltGsSnsrPwerStatus 0 "NotInRange" 1 "InRange" 2 "Error" 3 "NotAvailable";
VAL_ 2565870078 Aftrtrtmnt2OtltGsSnsrHeaterCtrl 0 "Automatic" 1 "Preheat2" 2 "Preheat1" 3 "HeaterOff";
VAL_ 2565870078 Aftrtrtmnt2OtltWdRngO2RdngStble 0 "NotStable" 1 "Stable" 2 "Error" 3 "NotAvailable";
VAL_ 2565870078 Aftrtrtmnt2OtltNOxReadingStable 0 "NotStable" 1 "Stable" 2 "Error" 3 "NotAvailable";
VAL_ 2565870078 Aftrtrtmnt2OtletGasSensorAtTemp 0 "NotInRange" 1 "InRange" 2 "Error" 3 "NotAvailable";
VAL_ 2566748926 DslPrtclteFilter2AshLoadPercent 4 "LevelIsTargetAshServiceInterval";
VAL_ 2566748926 DslPrtcltFilter2SootLoadPercent 4 "LvlIsActvRgnerationTriggerLevel";
VAL_ 2566748926 Aftrtrtmnt2DslPrtcltFltrStLdRgnr 4 "IsLvlAtWhchActvDslPrtcltFltrRgn";
VAL_ 2365428478 EngEmergencyShutdownIndication 0 "Off" 1 "On" 2 "Reserved" 3 "DontCare_TakeNoAction";
VAL_ 2365428478 EngCtrlledShutdownRq 0 "Off" 1 "On" 2 "Reserved" 3 "DontCare_TakeNoAction";
VAL_ 2365428478 EngCoolantCirculatingPumpCtrl 0 "Off" 1 "On" 2 "Reserved" 3 "DontCare_TakeNoAction";
VAL_ 2365428478 EngBlock_CoolantPreheaterCtrl 0 "Off" 1 "On" 2 "Reserved" 3 "Unavailable";
VAL_ 2365428478 EngElctrclSystmPwrCnsrvtionCtrl 0 "Off" 1 "On" 2 "Reserved" 3 "Unavailable";
VAL_ 2365428478 EngOilPreheaterCtrl 0 "Off" 1 "On" 2 "Reserved" 3 "DontCare_TakeNoAction";
VAL_ 2365428478 EngOilPrimingPumpCtrl 0 "Off" 1 "On" 2 "Reserved" 3 "Unavailable";
VAL_ 2365428478 EngFuelShutoffValveLeakTestCtrl 0 "Off" 1 "On" 2 "Reserved" 3 "DontCare_TakeNoAction";
VAL_ 2365428478 EngFuelShutoff2Ctrl 0 "Open" 1 "Closed" 2 "Reserved" 3 "DontCare_TakeNoAction";
VAL_ 2365428478 EngFuelShutoff1Ctrl 0 "Open" 1 "Closed" 2 "Reserved" 3 "DontCare_TakeNoAction";
VAL_ 2365428478 EngFuelShutoffVentCtrl 0 "Closed" 1 "Open" 2 "Reserved" 3 "DontCare_TakeNoAction";
VAL_ 2365428478 FuelPumpPrimerCtrl 0 "Deactivate" 1 "Activate" 2 "Reserved" 3 "Unavailable";
VAL_ 2362638078 SpeedDependentLevelCtrlRq 0 "Deactivate" 1 "Activate" 2 "Reserved" 3 "DonTCare_TakeNoAction";
VAL_ 2362638078 PrhbtAutomaticAirSuspensionCtrl 0 "NRq01RqstPrhbtdAtmtcArSspnsnCtr" 1 "RqPrhbtAtmaticAirSuspensionCtrl" 2 "ErrorIndicator" 3 "NotAvailable";
VAL_ 2362638078 MemoryLevelRq 0 "NoMemoryLevelRq" 1 "MemoryLevel1Rq" 2 "MemoryLevel2Rq" 3 "MemoryLevel3Rq" 4 "MemoryLevel4Rq" 5 "MemoryLevel5Rq" 9 "StoreMemoryLevel1" 10 "StoreMemoryLevel2" 11 "StoreMemoryLevel3" 12 "StoreMemoryLevel4" 13 "StoreMemoryLevel5" 14 "Reserved" 15 "DontCare";
VAL_ 2362638078 AllowLevelCtrlDuringBrakingCmd 0 "DisallowLevelCtrlDuringBraking" 1 "AllowLevelCtrlDuringBraking" 2 "Reserved" 3 "DonTCare_TakeNoAction";
VAL_ 2362638078 ProhibitAirSuspensionCtrl 0 "NoRq" 1 "RqProhibitAirSuspensionCtrl" 2 "ErrorIndicator" 3 "NotAvailable";
VAL_ 2362638078 KneelingCmdRearAxle 0 "DeactivateKneeling" 1 "ActivateKneeling" 2 "Reserved" 3 "DontCare_TakeNoAction";
VAL_ 2362638078 KneelingCmdFrontAxle 0 "DeactivateKneeling" 1 "ActivateKneeling" 2 "Reserved" 3 "DontCare_TakeNoAction";
VAL_ 2362638078 LevelCtrlModeRq 0 "NrmlOprtnISystmPrfrmsAPrCtrlOfT" 1 "TrctnHlpIDrvnAxlIsLddTAMxVlGvnB" 2 "LdFxngIDrvnAxlIsLddTAVlDfndByTh" 3 "PrssRt1IRtBtwnThPrssrsAtThDrvnA" 4 "PrssRt2IRtBtwnThPrssrsAtThDrvnA" 5 "OptmmTrctn1IPrssAtThDrvnAxlIsCt" 6 "OptmmTrctn2IPrssAtThDrvnAxlIsCt" 7 "TractionHelpLoadReduce" 8 "ExhaustBellows" 9 "1101NotDefined" 14 "Reserved" 15 "DontCare_TakeNoAction";
VAL_ 2362638078 NominalLevelRqRearAxle 0 "NoLevelRq" 1 "NormalLevel1" 2 "NormalLevel2" 3 "NormalLevel3" 4 "PresetLevel" 5 "CustomerLevel" 6 "UpperLevel" 7 "LowerLevel" 8 "StopLevelChange" 9 "RaiseRq" 10 "LowerRq" 11 "1101NotDefined" 14 "Reserved" 15 "DontCare_TakeNoAction";
VAL_ 2362638078 NominalLevelRqFrontAxle 0 "NoLevelRq" 1 "NormalLevel1" 2 "NormalLevel2" 3 "NormalLevel3" 4 "PresetLevel" 5 "CustomerLevel" 6 "UpperLevel" 7 "LowerLevel" 8 "StopLevelChange" 9 "RaiseRq" 10 "LowerRq" 11 "1101NotDefined" 14 "Reserved" 15 "DontCare_TakeNoAction";
VAL_ 2362638078 KneelingCtrlModeRq 0 "AutomaticallyActuated" 1 "ManuallyActuated" 2 "Reserved" 3 "DontCare_TakeNoAction";
VAL_ 2362638078 KneelingRqRightSide 0 "NoKneelingRq" 1 "KneelingRq" 2 "Reserved" 3 "DontCare_TakeNoAction";
VAL_ 2362638078 KneelingRqLeftSide 0 "NoKneelingRq" 1 "KneelingRq" 2 "Reserved" 3 "DontCare_TakeNoAction";
VAL_ 2362638078 AutomaticTractionHelp 0 "DisableAutomaticTractionHelp" 1 "EnableAutomaticTractionHelp" 2 "Reserved" 3 "DontCare";
VAL_ 2362638078 LiftAxle2PosCmd 0 "LiftAxlePosDown_TagAxleLaden" 1 "LiftAxlePosUp_TagAxleUnladen" 2 "Reserved" 3 "DontCare_TakeNoAction";
VAL_ 2362638078 LiftAxle1PosCmd 0 "LiftAxlePosDown_TagAxleLaden" 1 "LiftAxlePosUp_TagAxleUnladen" 2 "Reserved" 3 "DontCare_TakeNoAction";
VAL_ 2365479678 SpeedDependantLevelCtrlStatus 0 "Inactive" 1 "Active" 2 "Reserved" 3 "DonTCare_TakeNoAction";
VAL_ 2365479678 MemoryLevel 0 "NoMemoryLevel" 1 "MemoryLevel1Selected" 2 "MemoryLevel2Selected" 3 "MemoryLevel3Selected" 4 "MemoryLevel4Selected" 5 "MemoryLevel5Selected" 8 "Reserved" 9 "MemoryLevel1Stored" 10 "MemoryLevel2Stored" 11 "MemoryLevel3Stored" 12 "MemoryLevel4Stored" 13 "MemoryLevel5Stored" 14 "ErrorIndicator" 15 "NotAvailable";
VAL_ 2365479678 AllwLvelCtrlDuringBrakingStatus 0 "Deactivate" 1 "Activate" 2 "Reserved" 3 "DonTCare_TakeNoAction";
VAL_ 2365479678 SspensionCtrlRefusalInformation 0 "ActualRqNotRefused" 1 "AxleLoadLimitReached" 2 "WouldExceedAxleLoadLimit" 3 "BogieDiffNotLocked" 4 "AboveSpeedLimit" 5 "BelowSpeedLimit" 6 "GnrlRjctINSpcifiedReasonApplies" 7 "RqedLevelNotAvailable" 8 "1101NotDefined" 14 "Error" 15 "NotAvailable";
VAL_ 2365479678 SuspensionRemoteCtrl2 0 "NotActive" 1 "Active" 2 "Error" 3 "NotAvailable";
VAL_ 2365479678 SuspensionRemoteCtrl1 0 "NotActive" 1 "Active" 2 "Error" 3 "NotAvailable";
VAL_ 2365479678 RearAxleInBumperRange 0 "ActualLevelOutOfBumperRange" 1 "ActualLevelWithinBumperRange" 2 "Error" 3 "NotAvailable";
VAL_ 2365479678 FrontAxleInBumperRange 0 "ActualLevelOutOfBumperRange" 1 "ActualLevelWithinBumperRange" 2 "Error" 3 "NotAvailable";
VAL_ 2365479678 DoorRelease 0 "DoorsMayNotBeOpened" 1 "DoorsMayBeOpened" 2 "Error" 3 "NotAvailable";
VAL_ 2365479678 VehicleMotionInhibit 0 "VehicleMayBeMoved" 1 "VehicleMotionIsInhibited" 2 "Error" 3 "NotAvailable";
VAL_ 2365479678 SecurityDevice 0 "NotActive" 1 "Active" 2 "Error" 3 "NotAvailable";
VAL_ 2365479678 LevelCtrlMode 0 "NrmlOprtnISystmPrfrmsAPrCtrlOfT" 1 "TrctnHlpIDrvnAxlIsLddTAMxVlGvnB" 2 "LdFxngIDrvnAxlnIsLddTAVlDfndByT" 3 "PrssRt1IRtBtwnThPrssrsAtThDrvnA" 4 "PrssRt2IRtBtwnThPrssrsAtThDrvnA" 5 "OptmmTrctn1IPrssAtThDrvnAxlIsCt" 6 "OptmmTrctn2IPrssAtThDrvnAxlIsCt" 7 "TractionHelpLoadReduce" 8 "ExhstngBllwFnctnIBllwsArExhstdT" 9 "AirSuspensionCtrlProhibited" 10 "AtmtcArSuspensionCtrlProhibited" 11 "1101NotDefined" 14 "Error" 15 "NotAvailable";
VAL_ 2365479678 KneelingInformation 0 "NotActive" 2 "KneelingLevelReached" 3 "LiftingActive" 4 "KneelingAborted" 5 "1101NotDefined" 14 "Error" 15 "NotAvailable";
VAL_ 2365479678 LiftingCtrlModeRearAxle 0 "LiftingNotActive" 1 "LiftingActive" 2 "Error" 3 "NotAvailable";
VAL_ 2365479678 LiftingCtrlModeFrontAxle 0 "LiftingNotActive" 1 "LiftingActive" 2 "Error" 3 "NotAvailable";
VAL_ 2365479678 LoweringCtrlModeRearAxle 0 "LoweringNotActive" 1 "LoweringActive" 2 "Error" 3 "NotAvailable";
VAL_ 2365479678 LoweringCtrlModeFrontAxle 0 "LoweringNotActive" 1 "LoweringActive" 2 "Error" 3 "NotAvailable";
VAL_ 2365479678 AboveNominalLevelRearAxle 0 "NotAbove" 1 "Above" 2 "Error" 3 "NotAvailable";
VAL_ 2365479678 AboveNominalLevelFrontAxle 0 "NotAbove" 1 "Above" 2 "Error" 3 "NotAvailable";
VAL_ 2365479678 BelowNominalLevelRearAxle 0 "NotBelow" 1 "Below" 2 "Error" 3 "NotAvailable";
VAL_ 2365479678 BelowNominalLevelFrontAxle 0 "NotBelow" 1 "Below" 2 "Error" 3 "NotAvailable";
VAL_ 2365479678 NominalLevelRearAxle 0 "LevelNotSpecified" 1 "NormalLevel1" 2 "NormalLevel2" 3 "NormalLevel3" 4 "PresetLevel" 5 "CustomerLevel" 6 "UpperLevel" 7 "LowerLevel" 8 "NotDefined" 9 "Raising" 10 "Lowering" 11 "1101NotDefined" 14 "Error" 15 "NotAvailable";
VAL_ 2365479678 NominalLevelFrontAxle 0 "LevelNotSpecified" 1 "NormalLevel1" 2 "NormalLevel2" 3 "NormalLevel3" 4 "PresetLevel" 5 "CustomerLevel" 6 "UpperLevel" 7 "LowerLevel" 8 "NotDefined" 9 "Raising" 10 "Lowering" 11 "1101NotDefined" 14 "Error" 15 "NotAvailable";
VAL_ 2365479678 LiftAxle2Pos 0 "LiftAxlePosDown_TagAxleLaden" 1 "LiftAxlePosUp_TagAxleUnladen" 2 "Error" 3 "NotAvailable";
VAL_ 2365479678 LiftAxle1Pos 0 "LiftAxlePosDown_TagAxleLaden" 1 "LiftAxlePosUp_TagAxleUnladen" 2 "Error" 3 "NotAvailable";
VAL_ 2566837758 Alt4Status 0 "Alt4NotCharging" 1 "Alt4Charging" 2 "error" 3 "notAvailable";
VAL_ 2566837758 Alt3Status 0 "Alt3NotCharging" 1 "Alt3Charging" 2 "error" 3 "notAvailable";
VAL_ 2566837758 Alt2Status 0 "Alt2NotCharging" 1 "Alt2Charging" 2 "error" 3 "notAvailable";
VAL_ 2566837758 Alt1Status 0 "Alt1NotCharging" 1 "Alt1Charging" 2 "error" 3 "notAvailable";
VAL_ 2499635966 AxleGroupLocation 0 "Reserved" 1 "SteerAxleGroup" 2 "TrailerEAxleGroup" 3 "TrailerFAxleGroup";
VAL_ 2633853438 AxleGroupLocation 0 "Reserved" 1 "SteerAxleGroup" 2 "TrailerEAxleGroup" 3 "TrailerFAxleGroup";
VAL_ 2432520702 AftrcoolerCoolantThermostatMode 0 "TempCtrlMode" 1 "PosCtrlMode" 2 "Reserved" 3 "DontCare_Reserved";
VAL_ 2566745086 AddtnlTrlrAxlGrpWeightAvailable 0 "AddtnlTrilerAxleGroupNotPresent" 1 "AddtonalTrailerAxleGroupPresent" 2 "Reserved" 3 "NotAvailable_NotApplicable";
VAL_ 2566745086 TrilerHAxleGroupWeightAvailable 0 "TrailerHAxleGroupNotPresent" 1 "TrailerHAxleGroupPresent" 2 "Reserved" 3 "NotAvailable_NotApplicable";
VAL_ 2566745086 TrilerGAxleGroupWeightAvailable 0 "TrailerGAxleGroupNotPresent" 1 "TrailerGAxleGroupPresent" 2 "Reserved" 3 "NotAvailable_NotApplicable";
VAL_ 2566745086 TrilerFAxleGroupWeightAvailable 0 "TrailerFAxleGroupNotPresent" 1 "TrailerFAxleGroupPresent" 2 "Reserved" 3 "NotAvailable_NotApplicable";
VAL_ 2566745086 TrilerEAxleGroupWeightAvailable 0 "TrailerEAxleGroupNotPresent" 1 "TrailerEAxleGroupPresent" 2 "Reserved" 3 "NotAvailable_NotApplicable";
VAL_ 2566745086 TrilerDAxleGroupWeightAvailable 0 "TrailerDAxleGroupNotPresent" 1 "TrailerDAxleGroupPresent" 2 "Reserved" 3 "NotAvailable_NotApplicable";
VAL_ 2566745086 TrilerCAxleGroupWeightAvailable 0 "TrailerCAxleGroupNotPresent" 1 "TrailerCAxleGroupPresent" 2 "Reserved" 3 "NotAvailable_NotApplicable";
VAL_ 2566745086 TrilerBAxleGroupWeightAvailable 0 "TrailerBAxleGroupNotPresent" 1 "TrailerBAxleGroupPresent" 2 "Reserved" 3 "NotAvailable_NotApplicable";
VAL_ 2566745086 TrilerAAxleGroupWeightAvailable 0 "TrailerAAxleGroupNotPresent" 1 "TrailerAAxleGroupPresent" 2 "Reserved" 3 "NotAvailable_NotApplicable";
VAL_ 2566745086 AddtnlTrctrAxlGrpWightAvailable 0 "AddtnlTrctorAxleGroupNotPresent" 1 "AddtonalTractorAxleGroupPresent" 2 "Reserved" 3 "NotAvailable_NotApplicable";
VAL_ 2566745086 TagAxleGroupWeightAvailable 0 "TagAxleGroupNotPresent" 1 "TagAxleGroupPresent" 2 "Reserved" 3 "NotAvailable_NotApplicable";
VAL_ 2566745086 DriveAxleGroupWeightAvailable 0 "DriveAxleGroupNotPresent" 1 "DriveAxleGroupPresent" 2 "Reserved" 3 "NotAvailable_NotApplicable";
VAL_ 2566745086 LiftAxleGroupWeightAvailable 0 "LiftAxleGroupNotPresent" 1 "LiftAxleGroupPresent" 2 "Reserved" 3 "NotAvailable_NotApplicable";
VAL_ 2566745086 SteerAxleGroupWeightAvailable 0 "SteerAxleGroupNotPresent" 1 "SteerAxleGroupPresent" 2 "Reserved" 3 "NotAvailable_NotApplicable";
VAL_ 2566744062 ZeroNetVehicleWeightChange 0 "NChangeToNetVehicleWeightChange" 1 "ZeroNetVehicleWeightChange" 2 "Reserved" 3 "NotAvailable_NotApplicable";
VAL_ 2566754558 AETCDataCollectionStandard 0 "SAEJ1995" 1 "1101NotDefined" 15 "NotAvailable";
VAL_ 2566749950 RightHeadlampLightDistribution 0 "LghtDstrbtnTwnBscLghtDstrbtnFrT" 1 "LghtDstrbtnCntryCntryLghtIsMstl" 2 "LghtDstrbtnMtrwyTskOfMtrwyLghtI" 3 "LghtDstrbtnHghBmHghBmDstrbtnOfT" 4 "LghtDstrbtnAdvrsWthrAdvrsWthrLg" 5 "LghtDstrbtnFlSfPsMdlIsDmgdCrrnt" 6 "LghtDstrbtnFlrMdlIsDmgdCrrntPsM" 7 "DffrntLghtDstrbtnsNtAvlblNAFSDs" 8 "1110Reserved" 15 "NotAvailable";
VAL_ 2566749950 LeftHeadlampLightDistribution 0 "LghtDstrbtnTwnBscLghtDstrbtnFrT" 1 "LghtDstrbtnCntryCntryLghtIsMstl" 2 "LghtDstrbtnMtrwyTskOfMtrwyLghtI" 3 "LghtDstrbtnHghBmHghBmDstrbtnOfT" 4 "LghtDstrbtnAdvrsWthrAdvrsWthrLg" 5 "LghtDstrbtnFlSfPsMdlIsDmgdCrrnt" 6 "LghtDstrbtnFlrMdlIsDmgdCrrntPsM" 7 "DffrntLghtDstrbtnsNtAvlblNAFSDs" 8 "1110Reserved" 15 "NotAvailable";
VAL_ 2566749950 RghtHeadlampDynamicBendingLight 0 "DynmcBndngLghtDctvtdThrIsNPrblm" 1 "DynmcBndngLghtIsWrkngPrprlyNrml" 2 "DynmcBndngLghtFlSfPsBndngLghtIs" 3 "DynmcBndngLghtFlrBndngLghtDsNtW" 4 "110Reserved" 7 "NotAvailable";
VAL_ 2566749950 LeftHeadlampDynamicBendingLight 0 "DynmcBndngLghtDctvtdThrIsNPrblm" 1 "DynmcBndngLghtIsWrkngPrprlyNrml" 2 "DynmcBndngLghtFlSfPsBndngLghtIs" 3 "DynmcBndngLghtFlrBndngLghtDsNtW" 4 "110Reserved" 7 "NotAvailable";
VAL_ 2566838782 AuxI_O16 0 "AuxChannelOff" 1 "AuxChannelOn" 2 "Error" 3 "NotAvailable";
VAL_ 2566838782 AuxI_O15 0 "AuxChannelOff" 1 "AuxChannelOn" 2 "Error" 3 "NotAvailable";
VAL_ 2566838782 AuxI_O14 0 "AuxChannelOff" 1 "AuxChannelOn" 2 "Error" 3 "NotAvailable";
VAL_ 2566838782 AuxI_O13 0 "AuxChannelOff" 1 "AuxChannelOn" 2 "Error" 3 "NotAvailable";
VAL_ 2566838782 AuxI_O12 0 "AuxChannelOff" 1 "AuxChannelOn" 2 "Error" 3 "NotAvailable";
VAL_ 2566838782 AuxI_O11 0 "AuxChannelOff" 1 "AuxChannelOn" 2 "Error" 3 "NotAvailable";
VAL_ 2566838782 AuxI_O10 0 "AuxChannelOff" 1 "AuxChannelOn" 2 "Error" 3 "NotAvailable";
VAL_ 2566838782 AuxI_O09 0 "AuxChannelOff" 1 "AuxChannelOn" 2 "Error" 3 "NotAvailable";
VAL_ 2566838782 AuxI_O08 0 "AuxChannelOff" 1 "AuxChannelOn" 2 "Error" 3 "NotAvailable";
VAL_ 2566838782 AuxI_O07 0 "AuxChannelOff" 1 "AuxChannelOn" 2 "Error" 3 "NotAvailable";
VAL_ 2566838782 AuxI_O06 0 "AuxChannelOff" 1 "AuxChannelOn" 2 "Error" 3 "NotAvailable";
VAL_ 2566838782 AuxI_O05 0 "AuxChannelOff" 1 "AuxChannelOn" 2 "Error" 3 "NotAvailable";
VAL_ 2566838782 AuxI_O04 0 "AuxChannelOff" 1 "AuxChannelOn" 2 "Error" 3 "NotAvailable";
VAL_ 2566838782 AuxI_O03 0 "AuxChannelOff" 1 "AuxChannelOn" 2 "Error" 3 "NotAvailable";
VAL_ 2566838782 AuxI_O02 0 "AuxChannelOff" 1 "AuxChannelOn" 2 "Error" 3 "NotAvailable";
VAL_ 2566838782 AuxI_O01 0 "AuxChannelOff" 1 "AuxChannelOn" 2 "Error" 3 "NotAvailable";
VAL_ 2561146622 AuxI_O45 0 "AuxChannelOff" 1 "AuxChannelOn" 2 "ErrrIndctrNotUsedDependingOnApp" 3 "NtAvlblTkNoActionDependingOnApp";
VAL_ 2561146622 AuxI_O46 0 "AuxChannelOff" 1 "AuxChannelOn" 2 "ErrrIndctrNotUsedDependingOnApp" 3 "NtAvlblTkNoActionDependingOnApp";
VAL_ 2561146622 AuxI_O47 0 "AuxChannelOff" 1 "AuxChannelOn" 2 "ErrrIndctrNotUsedDependingOnApp" 3 "NtAvlblTkNoActionDependingOnApp";
VAL_ 2561146622 AuxI_O48 0 "AuxChannelOff" 1 "AuxChannelOn" 2 "ErrrIndctrNotUsedDependingOnApp" 3 "NtAvlblTkNoActionDependingOnApp";
VAL_ 2561146622 AuxI_O41 0 "AuxChannelOff" 1 "AuxChannelOn" 2 "ErrrIndctrNotUsedDependingOnApp" 3 "NtAvlblTkNoActionDependingOnApp";
VAL_ 2561146622 AuxI_O42 0 "AuxChannelOff" 1 "AuxChannelOn" 2 "ErrrIndctrNotUsedDependingOnApp" 3 "NtAvlblTkNoActionDependingOnApp";
VAL_ 2561146622 AuxI_O43 0 "AuxChannelOff" 1 "AuxChannelOn" 2 "ErrrIndctrNotUsedDependingOnApp" 3 "NtAvlblTkNoActionDependingOnApp";
VAL_ 2561146622 AuxI_O44 0 "AuxChannelOff" 1 "AuxChannelOn" 2 "ErrrIndctrNotUsedDependingOnApp" 3 "NtAvlblTkNoActionDependingOnApp";
VAL_ 2561146622 AuxI_O37 0 "AuxChannelOff" 1 "AuxChannelOn" 2 "ErrrIndctrNotUsedDependingOnApp" 3 "NtAvlblTkNoActionDependingOnApp";
VAL_ 2561146622 AuxI_O38 0 "AuxChannelOff" 1 "AuxChannelOn" 2 "ErrrIndctrNotUsedDependingOnApp" 3 "NtAvlblTkNoActionDependingOnApp";
VAL_ 2561146622 AuxI_O39 0 "AuxChannelOff" 1 "AuxChannelOn" 2 "ErrrIndctrNotUsedDependingOnApp" 3 "NtAvlblTkNoActionDependingOnApp";
VAL_ 2561146622 AuxI_O40 0 "AuxChannelOff" 1 "AuxChannelOn" 2 "ErrrIndctrNotUsedDependingOnApp" 3 "NtAvlblTkNoActionDependingOnApp";
VAL_ 2561146622 AuxI_O33 0 "AuxChannelOff" 1 "AuxChannelOn" 2 "ErrrIndctrNotUsedDependingOnApp" 3 "NtAvlblTkNoActionDependingOnApp";
VAL_ 2561146622 AuxI_O34 0 "AuxChannelOff" 1 "AuxChannelOn" 2 "ErrrIndctrNotUsedDependingOnApp" 3 "NtAvlblTkNoActionDependingOnApp";
VAL_ 2561146622 AuxI_O35 0 "AuxChannelOff" 1 "AuxChannelOn" 2 "ErrrIndctrNotUsedDependingOnApp" 3 "NtAvlblTkNoActionDependingOnApp";
VAL_ 2561146622 AuxI_O36 0 "AuxChannelOff" 1 "AuxChannelOn" 2 "ErrrIndctrNotUsedDependingOnApp" 3 "NtAvlblTkNoActionDependingOnApp";
VAL_ 2561146622 AuxI_O29 0 "AuxChannelOff" 1 "AuxChannelOn" 2 "ErrrIndctrNotUsedDependingOnApp" 3 "NtAvlblTkNoActionDependingOnApp";
VAL_ 2561146622 AuxI_O30 0 "AuxChannelOff" 1 "AuxChannelOn" 2 "ErrrIndctrNotUsedDependingOnApp" 3 "NtAvlblTkNoActionDependingOnApp";
VAL_ 2561146622 AuxI_O31 0 "AuxChannelOff" 1 "AuxChannelOn" 2 "ErrrIndctrNotUsedDependingOnApp" 3 "NtAvlblTkNoActionDependingOnApp";
VAL_ 2561146622 AuxI_O32 0 "AuxChannelOff" 1 "AuxChannelOn" 2 "ErrrIndctrNotUsedDependingOnApp" 3 "NtAvlblTkNoActionDependingOnApp";
VAL_ 2561146622 AuxI_O25 0 "AuxChannelOff" 1 "AuxChannelOn" 2 "ErrrIndctrNotUsedDependingOnApp" 3 "NtAvlblTkNoActionDependingOnApp";
VAL_ 2561146622 AuxI_O26 0 "AuxChannelOff" 1 "AuxChannelOn" 2 "ErrrIndctrNotUsedDependingOnApp" 3 "NtAvlblTkNoActionDependingOnApp";
VAL_ 2561146622 AuxI_O27 0 "AuxChannelOff" 1 "AuxChannelOn" 2 "ErrrIndctrNotUsedDependingOnApp" 3 "NtAvlblTkNoActionDependingOnApp";
VAL_ 2561146622 AuxI_O28 0 "AuxChannelOff" 1 "AuxChannelOn" 2 "ErrrIndctrNotUsedDependingOnApp" 3 "NtAvlblTkNoActionDependingOnApp";
VAL_ 2561146622 AuxI_O21 0 "AuxChannelOff" 1 "AuxChannelOn" 2 "ErrrIndctrNotUsedDependingOnApp" 3 "NtAvlblTkNoActionDependingOnApp";
VAL_ 2561146622 AuxI_O22 0 "AuxChannelOff" 1 "AuxChannelOn" 2 "ErrrIndctrNotUsedDependingOnApp" 3 "NtAvlblTkNoActionDependingOnApp";
VAL_ 2561146622 AuxI_O23 0 "AuxChannelOff" 1 "AuxChannelOn" 2 "ErrrIndctrNotUsedDependingOnApp" 3 "NtAvlblTkNoActionDependingOnApp";
VAL_ 2561146622 AuxI_O24 0 "AuxChannelOff" 1 "AuxChannelOn" 2 "ErrrIndctrNotUsedDependingOnApp" 3 "NtAvlblTkNoActionDependingOnApp";
VAL_ 2561146622 AuxI_O17 0 "AuxChannelOff" 1 "AuxChannelOn" 2 "ErrrIndctrNotUsedDependingOnApp" 3 "NtAvlblTkNoActionDependingOnApp";
VAL_ 2561146622 AuxI_O18 0 "AuxChannelOff" 1 "AuxChannelOn" 2 "ErrrIndctrNotUsedDependingOnApp" 3 "NtAvlblTkNoActionDependingOnApp";
VAL_ 2561146622 AuxI_O19 0 "AuxChannelOff" 1 "AuxChannelOn" 2 "ErrrIndctrNotUsedDependingOnApp" 3 "NtAvlblTkNoActionDependingOnApp";
VAL_ 2561146622 AuxI_O20 0 "AuxChannelOff" 1 "AuxChannelOn" 2 "ErrrIndctrNotUsedDependingOnApp" 3 "NtAvlblTkNoActionDependingOnApp";
VAL_ 2561081086 AuxI_O77 0 "AuxChannelOff" 1 "AuxChannelOn" 2 "ErrrIndctrNotUsedDependingOnApp" 3 "NtAvlblTkNoActionDependingOnApp";
VAL_ 2561081086 AuxI_O78 0 "AuxChannelOff" 1 "AuxChannelOn" 2 "ErrrIndctrNotUsedDependingOnApp" 3 "NtAvlblTkNoActionDependingOnApp";
VAL_ 2561081086 AuxI_O79 0 "AuxChannelOff" 1 "AuxChannelOn" 2 "ErrrIndctrNotUsedDependingOnApp" 3 "NtAvlblTkNoActionDependingOnApp";
VAL_ 2561081086 AuxI_O80 0 "AuxChannelOff" 1 "AuxChannelOn" 2 "ErrrIndctrNotUsedDependingOnApp" 3 "NtAvlblTkNoActionDependingOnApp";
VAL_ 2561081086 AuxI_O73 0 "AuxChannelOff" 1 "AuxChannelOn" 2 "ErrrIndctrNotUsedDependingOnApp" 3 "NtAvlblTkNoActionDependingOnApp";
VAL_ 2561081086 AuxI_O74 0 "AuxChannelOff" 1 "AuxChannelOn" 2 "ErrrIndctrNotUsedDependingOnApp" 3 "NtAvlblTkNoActionDependingOnApp";
VAL_ 2561081086 AuxI_O75 0 "AuxChannelOff" 1 "AuxChannelOn" 2 "ErrrIndctrNotUsedDependingOnApp" 3 "NtAvlblTkNoActionDependingOnApp";
VAL_ 2561081086 AuxI_O76 0 "AuxChannelOff" 1 "AuxChannelOn" 2 "ErrrIndctrNotUsedDependingOnApp" 3 "NtAvlblTkNoActionDependingOnApp";
VAL_ 2561081086 AuxI_O69 0 "AuxChannelOff" 1 "AuxChannelOn" 2 "ErrrIndctrNotUsedDependingOnApp" 3 "NtAvlblTkNoActionDependingOnApp";
VAL_ 2561081086 AuxI_O70 0 "AuxChannelOff" 1 "AuxChannelOn" 2 "ErrrIndctrNotUsedDependingOnApp" 3 "NtAvlblTkNoActionDependingOnApp";
VAL_ 2561081086 AuxI_O71 0 "AuxChannelOff" 1 "AuxChannelOn" 2 "ErrrIndctrNotUsedDependingOnApp" 3 "NtAvlblTkNoActionDependingOnApp";
VAL_ 2561081086 AuxI_O72 0 "AuxChannelOff" 1 "AuxChannelOn" 2 "ErrrIndctrNotUsedDependingOnApp" 3 "NtAvlblTkNoActionDependingOnApp";
VAL_ 2561081086 AuxI_O65 0 "AuxChannelOff" 1 "AuxChannelOn" 2 "ErrrIndctrNotUsedDependingOnApp" 3 "NtAvlblTkNoActionDependingOnApp";
VAL_ 2561081086 AuxI_O66 0 "AuxChannelOff" 1 "AuxChannelOn" 2 "ErrrIndctrNotUsedDependingOnApp" 3 "NtAvlblTkNoActionDependingOnApp";
VAL_ 2561081086 AuxI_O67 0 "AuxChannelOff" 1 "AuxChannelOn" 2 "ErrrIndctrNotUsedDependingOnApp" 3 "NtAvlblTkNoActionDependingOnApp";
VAL_ 2561081086 AuxI_O68 0 "AuxChannelOff" 1 "AuxChannelOn" 2 "ErrrIndctrNotUsedDependingOnApp" 3 "NtAvlblTkNoActionDependingOnApp";
VAL_ 2561081086 AuxI_O61 0 "AuxChannelOff" 1 "AuxChannelOn" 2 "ErrrIndctrNotUsedDependingOnApp" 3 "NtAvlblTkNoActionDependingOnApp";
VAL_ 2561081086 AuxI_O62 0 "AuxChannelOff" 1 "AuxChannelOn" 2 "ErrrIndctrNotUsedDependingOnApp" 3 "NtAvlblTkNoActionDependingOnApp";
VAL_ 2561081086 AuxI_O63 0 "AuxChannelOff" 1 "AuxChannelOn" 2 "ErrrIndctrNotUsedDependingOnApp" 3 "NtAvlblTkNoActionDependingOnApp";
VAL_ 2561081086 AuxI_O64 0 "AuxChannelOff" 1 "AuxChannelOn" 2 "ErrrIndctrNotUsedDependingOnApp" 3 "NtAvlblTkNoActionDependingOnApp";
VAL_ 2561081086 AuxI_O57 0 "AuxChannelOff" 1 "AuxChannelOn" 2 "ErrrIndctrNotUsedDependingOnApp" 3 "NtAvlblTkNoActionDependingOnApp";
VAL_ 2561081086 AuxI_O58 0 "AuxChannelOff" 1 "AuxChannelOn" 2 "ErrrIndctrNotUsedDependingOnApp" 3 "NtAvlblTkNoActionDependingOnApp";
VAL_ 2561081086 AuxI_O59 0 "AuxChannelOff" 1 "AuxChannelOn" 2 "ErrrIndctrNotUsedDependingOnApp" 3 "NtAvlblTkNoActionDependingOnApp";
VAL_ 2561081086 AuxI_O60 0 "AuxChannelOff" 1 "AuxChannelOn" 2 "ErrrIndctrNotUsedDependingOnApp" 3 "NtAvlblTkNoActionDependingOnApp";
VAL_ 2561081086 AuxI_O53 0 "AuxChannelOff" 1 "AuxChannelOn" 2 "ErrrIndctrNotUsedDependingOnApp" 3 "NtAvlblTkNoActionDependingOnApp";
VAL_ 2561081086 AuxI_O54 0 "AuxChannelOff" 1 "AuxChannelOn" 2 "ErrrIndctrNotUsedDependingOnApp" 3 "NtAvlblTkNoActionDependingOnApp";
VAL_ 2561081086 AuxI_O55 0 "AuxChannelOff" 1 "AuxChannelOn" 2 "ErrrIndctrNotUsedDependingOnApp" 3 "NtAvlblTkNoActionDependingOnApp";
VAL_ 2561081086 AuxI_O56 0 "AuxChannelOff" 1 "AuxChannelOn" 2 "ErrrIndctrNotUsedDependingOnApp" 3 "NtAvlblTkNoActionDependingOnApp";
VAL_ 2561081086 AuxI_O49 0 "AuxChannelOff" 1 "AuxChannelOn" 2 "ErrrIndctrNotUsedDependingOnApp" 3 "NtAvlblTkNoActionDependingOnApp";
VAL_ 2561081086 AuxI_O50 0 "AuxChannelOff" 1 "AuxChannelOn" 2 "ErrrIndctrNotUsedDependingOnApp" 3 "NtAvlblTkNoActionDependingOnApp";
VAL_ 2561081086 AuxI_O51 0 "AuxChannelOff" 1 "AuxChannelOn" 2 "ErrrIndctrNotUsedDependingOnApp" 3 "NtAvlblTkNoActionDependingOnApp";
VAL_ 2561081086 AuxI_O52 0 "AuxChannelOff" 1 "AuxChannelOn" 2 "ErrrIndctrNotUsedDependingOnApp" 3 "NtAvlblTkNoActionDependingOnApp";
VAL_ 2561015550 AuxI_O92 0 "AuxChannelOff" 1 "AuxChannelOn" 2 "ErrrIndctrNotUsedDependingOnApp" 3 "NtAvlblTkNoActionDependingOnApp";
VAL_ 2561015550 AuxI_O85 0 "AuxChannelOff" 1 "AuxChannelOn" 2 "ErrrIndctrNotUsedDependingOnApp" 3 "NtAvlblTkNoActionDependingOnApp";
VAL_ 2561015550 AuxI_O86 0 "AuxChannelOff" 1 "AuxChannelOn" 2 "ErrrIndctrNotUsedDependingOnApp" 3 "NtAvlblTkNoActionDependingOnApp";
VAL_ 2561015550 AuxI_O87 0 "AuxChannelOff" 1 "AuxChannelOn" 2 "ErrrIndctrNotUsedDependingOnApp" 3 "NtAvlblTkNoActionDependingOnApp";
VAL_ 2561015550 AuxI_O88 0 "AuxChannelOff" 1 "AuxChannelOn" 2 "ErrrIndctrNotUsedDependingOnApp" 3 "NtAvlblTkNoActionDependingOnApp";
VAL_ 2561015550 AuxI_O81 0 "AuxChannelOff" 1 "AuxChannelOn" 2 "ErrrIndctrNotUsedDependingOnApp" 3 "NtAvlblTkNoActionDependingOnApp";
VAL_ 2561015550 AuxI_O82 0 "AuxChannelOff" 1 "AuxChannelOn" 2 "ErrrIndctrNotUsedDependingOnApp" 3 "NtAvlblTkNoActionDependingOnApp";
VAL_ 2561015550 AuxI_O83 0 "AuxChannelOff" 1 "AuxChannelOn" 2 "ErrrIndctrNotUsedDependingOnApp" 3 "NtAvlblTkNoActionDependingOnApp";
VAL_ 2561015550 AuxI_O84 0 "AuxChannelOff" 1 "AuxChannelOn" 2 "ErrrIndctrNotUsedDependingOnApp" 3 "NtAvlblTkNoActionDependingOnApp";
VAL_ 2561015550 AuxI_O109 0 "AuxChannelOff" 1 "AuxChannelOn" 2 "ErrrIndctrNotUsedDependingOnApp" 3 "NtAvlblTkNoActionDependingOnApp";
VAL_ 2561015550 AuxI_O110 0 "AuxChannelOff" 1 "AuxChannelOn" 2 "ErrrIndctrNotUsedDependingOnApp" 3 "NtAvlblTkNoActionDependingOnApp";
VAL_ 2561015550 AuxI_O111 0 "AuxChannelOff" 1 "AuxChannelOn" 2 "ErrrIndctrNotUsedDependingOnApp" 3 "NtAvlblTkNoActionDependingOnApp";
VAL_ 2561015550 AuxI_O112 0 "AuxChannelOff" 1 "AuxChannelOn" 2 "ErrrIndctrNotUsedDependingOnApp" 3 "NtAvlblTkNoActionDependingOnApp";
VAL_ 2561015550 AuxI_O105 0 "AuxChannelOff" 1 "AuxChannelOn" 2 "ErrrIndctrNotUsedDependingOnApp" 3 "NtAvlblTkNoActionDependingOnApp";
VAL_ 2561015550 AuxI_O106 0 "AuxChannelOff" 1 "AuxChannelOn" 2 "ErrrIndctrNotUsedDependingOnApp" 3 "NtAvlblTkNoActionDependingOnApp";
VAL_ 2561015550 AuxI_O107 0 "AuxChannelOff" 1 "AuxChannelOn" 2 "ErrrIndctrNotUsedDependingOnApp" 3 "NtAvlblTkNoActionDependingOnApp";
VAL_ 2561015550 AuxI_O108 0 "AuxChannelOff" 1 "AuxChannelOn" 2 "ErrrIndctrNotUsedDependingOnApp" 3 "NtAvlblTkNoActionDependingOnApp";
VAL_ 2561015550 AuxI_O101 0 "AuxChannelOff" 1 "AuxChannelOn" 2 "ErrrIndctrNotUsedDependingOnApp" 3 "NtAvlblTkNoActionDependingOnApp";
VAL_ 2561015550 AuxI_O102 0 "AuxChannelOff" 1 "AuxChannelOn" 2 "ErrrIndctrNotUsedDependingOnApp" 3 "NtAvlblTkNoActionDependingOnApp";
VAL_ 2561015550 AuxI_O103 0 "AuxChannelOff" 1 "AuxChannelOn" 2 "ErrrIndctrNotUsedDependingOnApp" 3 "NtAvlblTkNoActionDependingOnApp";
VAL_ 2561015550 AuxI_O104 0 "AuxChannelOff" 1 "AuxChannelOn" 2 "ErrrIndctrNotUsedDependingOnApp" 3 "NtAvlblTkNoActionDependingOnApp";
VAL_ 2561015550 AuxI_O97 0 "AuxChannelOff" 1 "AuxChannelOn" 2 "ErrrIndctrNotUsedDependingOnApp" 3 "NtAvlblTkNoActionDependingOnApp";
VAL_ 2561015550 AuxI_O98 0 "AuxChannelOff" 1 "AuxChannelOn" 2 "ErrrIndctrNotUsedDependingOnApp" 3 "NtAvlblTkNoActionDependingOnApp";
VAL_ 2561015550 AuxI_O99 0 "AuxChannelOff" 1 "AuxChannelOn" 2 "ErrrIndctrNotUsedDependingOnApp" 3 "NtAvlblTkNoActionDependingOnApp";
VAL_ 2561015550 AuxI_O100 0 "AuxChannelOff" 1 "AuxChannelOn" 2 "ErrrIndctrNotUsedDependingOnApp" 3 "NtAvlblTkNoActionDependingOnApp";
VAL_ 2561015550 AuxI_O93 0 "AuxChannelOff" 1 "AuxChannelOn" 2 "ErrrIndctrNotUsedDependingOnApp" 3 "NtAvlblTkNoActionDependingOnApp";
VAL_ 2561015550 AuxI_O94 0 "AuxChannelOff" 1 "AuxChannelOn" 2 "ErrrIndctrNotUsedDependingOnApp" 3 "NtAvlblTkNoActionDependingOnApp";
VAL_ 2561015550 AuxI_O95 0 "AuxChannelOff" 1 "AuxChannelOn" 2 "ErrrIndctrNotUsedDependingOnApp" 3 "NtAvlblTkNoActionDependingOnApp";
VAL_ 2561015550 AuxI_O96 0 "AuxChannelOff" 1 "AuxChannelOn" 2 "ErrrIndctrNotUsedDependingOnApp" 3 "NtAvlblTkNoActionDependingOnApp";
VAL_ 2561015550 AuxI_O89 0 "AuxChannelOff" 1 "AuxChannelOn" 2 "ErrrIndctrNotUsedDependingOnApp" 3 "NtAvlblTkNoActionDependingOnApp";
VAL_ 2561015550 AuxI_O90 0 "AuxChannelOff" 1 "AuxChannelOn" 2 "ErrrIndctrNotUsedDependingOnApp" 3 "NtAvlblTkNoActionDependingOnApp";
VAL_ 2561015550 AuxI_O91 0 "AuxChannelOff" 1 "AuxChannelOn" 2 "ErrrIndctrNotUsedDependingOnApp" 3 "NtAvlblTkNoActionDependingOnApp";
VAL_ 2566746622 TrailerBrakeStrokeAxle5Right 0 "OK" 1 "Nonfunctioning" 2 "Overstroke" 3 "DraggingBrake" 5 "Reserved" 6 "SensorError" 7 "NotAvailable";
VAL_ 2566746622 TrailerBrakeStrokeAxle5Left 0 "OK" 1 "Nonfunctioning" 2 "Overstroke" 3 "DraggingBrake" 5 "Reserved" 6 "SensorError" 7 "NotAvailable";
VAL_ 2566746622 TrailerBrakeStrokeAxle4Right 0 "OK" 1 "Nonfunctioning" 2 "Overstroke" 3 "DraggingBrake" 5 "Reserved" 6 "SensorError" 7 "NotAvailable";
VAL_ 2566746622 TrailerBrakeStrokeAxle4Left 0 "OK" 1 "Nonfunctioning" 2 "Overstroke" 3 "DraggingBrake" 5 "Reserved" 6 "SensorError" 7 "NotAvailable";
VAL_ 2566746622 TrailerBrakeStrokeAxle3Right 0 "OK" 1 "Nonfunctioning" 2 "Overstroke" 3 "DraggingBrake" 5 "Reserved" 6 "SensorError" 7 "NotAvailable";
VAL_ 2566746622 TrailerBrakeStrokeAxle3Left 0 "OK" 1 "Nonfunctioning" 2 "Overstroke" 3 "DraggingBrake" 5 "Reserved" 6 "SensorError" 7 "NotAvailable";
VAL_ 2566746622 TrailerBrakeStrokeAxle2Right 0 "OK" 1 "Nonfunctioning" 2 "Overstroke" 3 "DraggingBrake" 5 "Reserved" 6 "SensorError" 7 "NotAvailable";
VAL_ 2566746622 TrailerBrakeStrokeAxle2Left 0 "OK" 1 "Nonfunctioning" 2 "Overstroke" 3 "DraggingBrake" 5 "Reserved" 6 "SensorError" 7 "NotAvailable";
VAL_ 2566746622 TrailerBrakeStrokeAxle1Right 0 "OK" 1 "Nonfunctioning" 2 "Overstroke" 3 "DraggingBrake" 5 "Reserved" 6 "SensorError" 7 "NotAvailable";
VAL_ 2566746622 TrailerBrakeStrokeAxle1Left 0 "OK" 1 "Nonfunctioning" 2 "Overstroke" 3 "DraggingBrake" 5 "Reserved" 6 "SensorError" 7 "NotAvailable";
VAL_ 2566746622 TractorBrakeStrokeAxle5Right 0 "OK" 1 "Nonfunctioning" 2 "Overstroke" 3 "DraggingBrake" 5 "Reserved" 6 "SensorError" 7 "NotAvailable";
VAL_ 2566746622 TractorBrakeStrokeAxle5Left 0 "OK" 1 "Nonfunctioning" 2 "Overstroke" 3 "DraggingBrake" 5 "Reserved" 6 "SensorError" 7 "NotAvailable";
VAL_ 2566746622 TractorBrakeStrokeAxle4Right 0 "OK" 1 "Nonfunctioning" 2 "Overstroke" 3 "DraggingBrake" 5 "Reserved" 6 "SensorError" 7 "NotAvailable";
VAL_ 2566746622 TractorBrakeStrokeAxle4Left 0 "OK" 1 "Nonfunctioning" 2 "Overstroke" 3 "DraggingBrake" 5 "Reserved" 6 "SensorError" 7 "NotAvailable";
VAL_ 2566746622 TractorBrakeStrokeAxle3Right 0 "OK" 1 "Nonfunctioning" 2 "Overstroke" 3 "DraggingBrake" 5 "Reserved" 6 "SensorError" 7 "NotAvailable";
VAL_ 2566746622 TractorBrakeStrokeAxle3Left 0 "OK" 1 "Nonfunctioning" 2 "Overstroke" 3 "DraggingBrake" 5 "Reserved" 6 "SensorError" 7 "NotAvailable";
VAL_ 2566746622 TractorBrakeStrokeAxle2Right 0 "OK" 1 "Nonfunctioning" 2 "Overstroke" 3 "DraggingBrake" 5 "Reserved" 6 "SensorError" 7 "NotAvailable";
VAL_ 2566746622 TractorBrakeStrokeAxle2Left 0 "OK" 1 "Nonfunctioning" 2 "Overstroke" 3 "DraggingBrake" 5 "Reserved" 6 "SensorError" 7 "NotAvailable";
VAL_ 2566746622 TractorBrakeStrokeAxle1Right 0 "OK" 1 "Nonfunctioning" 2 "Overstroke" 3 "DraggingBrake" 5 "Reserved" 6 "SensorError" 7 "NotAvailable";
VAL_ 2566746622 TractorBrakeStrokeAxle1Left 0 "OK" 1 "Nonfunctioning" 2 "Overstroke" 3 "DraggingBrake" 5 "Reserved" 6 "SensorError" 7 "NotAvailable";
VAL_ 2566827774 AirCompressorStatus 0 "CompressorNotActive" 1 "CompressorActive" 2 "ErrorIndicator" 3 "NotAvailable";
VAL_ 2566803966 ACCUsageDemand 0 "drvrDmndFrNtUsngACCDstncKpngCtr" 1 "drvrDmndFrUsngACCDstncKpingCtrl" 2 "reserved" 3 "dontCare";
VAL_ 2566803966 RqedACCDistanceMode 0 "RqedACCDistanceMode1" 1 "RqedACCDistanceMode2" 2 "RqedACCDistanceMode3" 3 "RqedACCDistanceMode4" 4 "RqedACCDistanceMode5" 5 "notDefined" 6 "errorCondition" 7 "notAvailable";
VAL_ 2432593918 ForwardCollisionWarning 0 "NoWarning" 1 "CollisionIsImminent" 2 "ErrorIndicator" 3 "notAvailable";
VAL_ 2432593918 ACCDistanceAlertSignal 0 "ACCDASNotActive" 1 "ACCDASActive" 2 "Reserved" 3 "TakeNoAction";
VAL_ 2432593918 ACCSystemShutoffWarning 0 "ACCSSOWNotActive" 1 "ACCSSOWActive" 2 "Reserved" 3 "TakeNoAction";
VAL_ 2432593918 ACCTargetDetected 0 "NoTargetsDetected" 1 "TargetDetected" 2 "Reserved" 3 "TakeNoAction";
VAL_ 2432593918 AdptveCruiseCtrlSetDistanceMode 0 "ACCDistanceMode1" 1 "ACCDistanceMode2" 2 "ACCDistanceMode3" 3 "ACCDistanceMode4" 4 "ACCDistanceMode5" 5 "ConventionalCruiseCtrlMode" 6 "ErrorCondition" 7 "NotAvailable_NotValid";
VAL_ 2432593918 AdaptiveCruiseCtrlMode 0 "OffUsdTIndctACCIsEnbldInClbCnfg" 1 "SpeedCtrlActive" 2 "DstncCtrlActvUsdTIndctThtACCIsO" 3 "OvertakeMode" 4 "HldMdUsdTIndctThtACCHsLstThPrvs" 5 "FinishMode" 6 "DsbldErrrCndtnUsdTIndctThtACCIs" 7 "NotAvailable_NotValid";
VAL_ 2566803198 Status2OfDoors 0 "allBusDoorsAreDisabled" 1 "atLeast1BusDoorEnabled" 2 "error" 3 "notAvailable";
VAL_ 2566803198 Ramp_WheelChairLiftPos 0 "InsideBus" 1 "OutsideBus" 2 "Error" 3 "NotAvailable";
VAL_ 2566803198 PosOfDoors 0 "AtLeast1DoorIsOpen" 1 "ClosingLastDoor" 2 "AllDoorsClosed" 3 "1101NotDefined" 14 "Error" 15 "NotAvailable";
VAL_ 2565870334 FifthWheelRollWarningIndicator 0 "LimitNotExceeded" 1 "LimitExceeded" 2 "error" 3 "NotAvailable";
VAL_ 2566762238 FifthWheelSliderLockIndicator 0 "NotLocked" 1 "Locked" 2 "Error" 3 "NotAvailable";
VAL_ 2566762238 FfthWhlLckCoupleStatusIndicator 0 "IncmpltBdCplTrckShuldNotBeMoved" 1 "SuccessfulCoupleDetected" 2 "Error" 3 "NotAvailable";
VAL_ 2566762238 FfthWhlLckRadyToCoupleIndicator 0 "LockNotOpenNotReadyToCouple" 1 "LockOpenReadyToCouple" 2 "Error" 3 "NotAvailable";
VAL_ 2566762238 FifthWheelErrorStatus 0 "ImproperCouple" 1 "LocksClosed_NoKingpinAtStartup" 2 "Kingpin_LocksOpenAtStartup" 5 "CouplingSequenceError" 6 "CouplingSequenceError_Kingpin" 7 "CouplingTimingError" 8 "KingpinMissingMoreThan5Seconds" 9 "Kingpin_LockOpen" 14 "NotUsed" 15 "NotAvailable";
VAL_ 2364543998 PitchAndRollCompensated 0 "CompensationOn" 1 "NotAvailable" 2 "Error" 3 "NotAvailable";
VAL_ 2364543998 PitchRateFigureOfMerit 0 "PtchRtDgrddDtIsSspctDTEnvrnmntl" 1 "NotAvailable" 2 "Error" 3 "NotAvailable";
VAL_ 2364543998 RollAngleFigureOfMerit 0 "RollAngleFullyFunctional" 1 "RollAngleDegraded" 2 "Error" 3 "NotAvailable";
VAL_ 2364543998 PitchAngleFigureOfMerit 0 "PtchAnglDgrddDtIsSspctDTEnvrnmn" 1 "NotAvailable" 2 "Error" 3 "NotAvailable";
VAL_ 2566846718 TransOilLevelMeasurementStatus 0 "CndtnsVldFrTrnsOlLvlMeasurement" 1 "CndtnsNtVldSttlngTmrStllCntngDw" 2 "ConditionsNotValidTransInGear" 3 "CndtnsNtVldTransFluidTempTooLow" 4 "CndtnsNtVldTrnsFluidTempTooHigh" 5 "CndtnsNtVldVhclMvngOtptShftSpdT" 6 "CndtionsNotValidVehicleNotLevel" 7 "CnditionsNotValidEngSpeedTooLow" 8 "CndtionsNotValidEngSpeedTooHigh" 9 "CnditionsNotValidNoRqForReading" 12 "NotDefined" 13 "ConditionsNotValidOther" 14 "Error" 15 "NotAvailable";
VAL_ 2566846718 TransOilLevelCountdownTimer 0 "lessThan1Minute" 1 "OneMinute" 2 "TwoMinutes" 3 "ThreeMinutes" 4 "FourMinutes" 5 "FiveMinutes" 6 "SixMinutes" 7 "SevenMinutes" 8 "EightMinutes" 9 "NineMinutes" 10 "TenMinutes" 11 "ElevenMinutes" 12 "TwelveMinutes" 13 "ThirteenMinutes" 14 "Error" 15 "NotAvailable";
VAL_ 2566846718 TransOilLevelHigh_Low 251 "CondNotAcceptableForValidMeasure";
VAL_ 2566760702 WrlessCommunicationNetworkType2 0 "CellularNetwork1" 1 "CellularNetwork2";
VAL_ 2566760702 NetworkAntennaStatus2 0 "Off" 1 "On";
VAL_ 2566760702 NetworkServiceStatus2 0 "LocalService" 1 "RoamingService";
VAL_ 2566760702 NetworkTransceiverStatus2 0 "Off" 1 "On";
VAL_ 2566760958 WrlessCommunicationNetworkType1 0 "CellularNetwork1" 1 "CellularNetwork2";
VAL_ 2566760958 NetworkAntennaStatus1 0 "Off" 1 "On";
VAL_ 2566760958 NetworkServiceStatus1 0 "LocalService" 1 "RoamingService";
VAL_ 2566760958 NetworkTransceiverStatus1 0 "Off" 1 "On";
